VERSION ""

NS_ :

BS_:

BU_: BCM DMS NAB NDG NQS NVO SGW

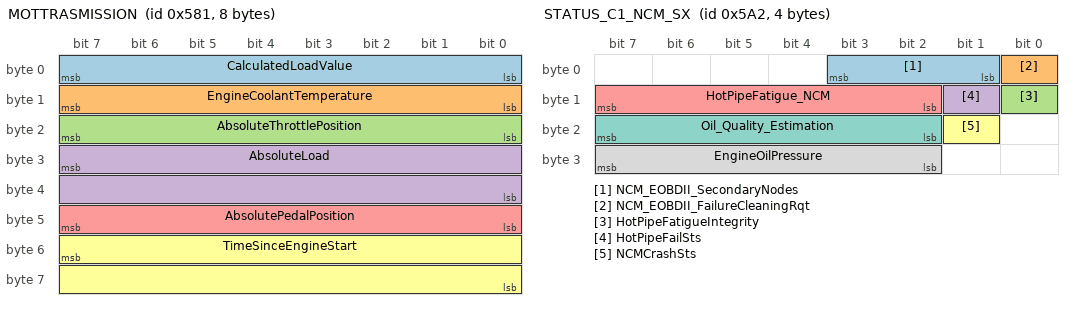
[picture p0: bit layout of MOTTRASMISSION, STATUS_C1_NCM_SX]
BO_ 1409 MOTTRASMISSION: 8 SGW
 SG_ CalculatedLoadValue : 7|8@0+ (0.392,0) [0|99.96] "%" Vector__XXX
 SG_ EngineCoolantTemperature : 15|8@0+ (1,-40) [-40|215] "°C" Vector__XXX
 SG_ AbsoluteThrottlePosition : 23|8@0+ (0.392,0) [0|99.96] "%"  NAB
 SG_ AbsoluteLoad : 31|16@0+ (0.392,0) [0|25689.72] "%" Vector__XXX
 SG_ AbsolutePedalPosition : 47|8@0+ (0.392,0) [0|99.96] "%" Vector__XXX
 SG_ TimeSinceEngineStart : 55|16@0+ (1,0) [0|65535] "sec." Vector__XXX

BO_ 1441 STATUS_C_NCM2: 8 SGW
 SG_ Checksum_STATUS_C_NCM2 : 7|8@0+ (1,0) [0|255] ""  BCM,DMS,NQS
 SG_ EngineOilTemperature : 8|8@0+ (1,-48) [-10|179] "°C"  BCM,NDG,NQS
 SG_ ReducePowerAssist : 9|1@0+ (1,0) [0|1] ""  BCM
 SG_ EM_Ready_Indication : 10|1@0+ (1,0) [0|1] ""  BCM,NQS
 SG_ FuelCapCheckWarning : 13|1@0+ (1,0) [0|1] ""  BCM,NQS
 SG_ VehicleNotInUse : 15|2@0+ (1,0) [0|3] ""  BCM,NDG,NQS
 SG_ EngineOilTemperatureValidData : 16|1@0+ (1,0) [0|1] ""  BCM,NDG,NQS
 SG_ BatteryVoltageLevel : 30|7@0+ (0.16,0) [0|18] "volt"  BCM
 SG_ CruiseControlSts : 31|1@0+ (1,0) [0|1] ""  BCM
 SG_ CruiseControlLampSts : 33|2@0+ (1,0) [0|3] ""  BCM,NAB,NDG,NQS,NVO
 SG_ RechargeSts : 34|1@0+ (1,0) [0|1] ""  BCM
 SG_ MessageCounter : 38|4@0+ (1,0) [0|15] ""  BCM,DMS,NQS
 SG_ BatteryVoltageLevelFailSts : 39|1@0+ (1,0) [0|1] ""  BCM
 SG_ StopStartVisualizationCode : 43|4@0+ (1,0) [0|15] ""  BCM,NDG,NQS
 SG_ EngineSts : 45|2@0+ (1,0) [0|3] ""  BCM,DMS,NDG,NQS
 SG_ StopStartSts : 47|2@0+ (1,0) [0|3] ""  BCM,NQS
 SG_ ColdStartTime : 48|1@0+ (1,0) [0|1] ""  BCM
 SG_ NCMMildHybSysWarningForDisplay : 52|4@0+ (1,0) [0|15] ""  BCM
 SG_ EDriveSts : 54|2@0+ (1,0) [0|3] ""  BCM,DMS,NDG,NQS
 SG_ EngineBonnetSts2 : 55|1@0+ (1,0) [0|1] ""  BCM
 SG_ TargetSpeed : 63|8@0+ (1,0) [0|255] "km/h"  BCM,NQS

BO_ 1442 STATUS_C1_NCM_SX: 4 SGW
 SG_ NCM_EOBDII_SecondaryNodes : 3|3@0+ (1,0) [0|7] ""  BCM
 SG_ NCM_EOBDII_FailureCleaningRqt : 0|1@0+ (1,0) [0|1] ""  BCM
 SG_ HotPipeFatigueIntegrity : 8|1@0+ (1,0) [0|1] ""  NQS
 SG_ HotPipeFailSts : 9|1@0+ (1,0) [0|1] ""  NDG,NQS
 SG_ HotPipeFatigue_NCM : 15|6@0+ (0.016,0) [0|1.008] ""  NQS
 SG_ NCMCrashSts : 17|1@0+ (1,0) [0|1] ""  BCM
 SG_ Oil_Quality_Estimation : 23|6@0+ (1.6,-1) [-1|99.8] "%"  NDG,NQS
 SG_ EngineOilPressure : 31|6@0+ (0.2,0) [0|10] "bar"  NDG,NQS

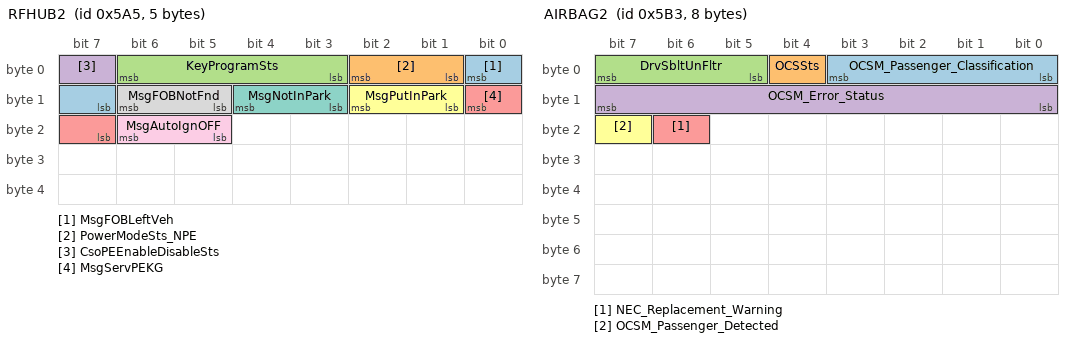
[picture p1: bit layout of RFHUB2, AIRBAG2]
BO_ 1445 RFHUB2: 5 BCM
 SG_ MsgFOBLeftVeh : 0|2@0+ (1,0) [0|3] ""  NQS
 SG_ PowerModeSts_NPE : 2|2@0+ (1,0) [0|3] "" Vector__XXX
 SG_ KeyProgramSts : 6|4@0+ (1,0) [0|15] ""  NDG,NQS
 SG_ CsoPEEnableDisableSts : 7|1@0+ (1,0) [0|1] ""  NQS
 SG_ MsgServPEKG : 8|2@0+ (1,0) [0|3] ""  NDG,NQS
 SG_ MsgPutInPark : 10|2@0+ (1,0) [0|3] ""  NQS
 SG_ MsgNotInPark : 12|2@0+ (1,0) [0|3] ""  NQS
 SG_ MsgFOBNotFnd : 14|2@0+ (1,0) [0|3] ""  NQS
 SG_ MsgAutoIgnOFF : 22|2@0+ (1,0) [0|3] "" Vector__XXX

BO_ 1459 AIRBAG2: 8 NAB
 SG_ OCSM_Passenger_Classification : 3|4@0+ (1,0) [0|15] "" Vector__XXX
 SG_ OCSSts : 4|1@0+ (1,0) [0|1] ""  NQS
 SG_ DrvSbltUnFltr : 7|3@0+ (1,0) [0|7] "" Vector__XXX
 SG_ OCSM_Error_Status : 15|8@0+ (1,0) [0|255] "" Vector__XXX
 SG_ NEC_Replacement_Warning : 22|1@0+ (1,0) [0|1] ""  BCM
 SG_ OCSM_Passenger_Detected : 23|1@0+ (1,0) [0|1] "" Vector__XXX

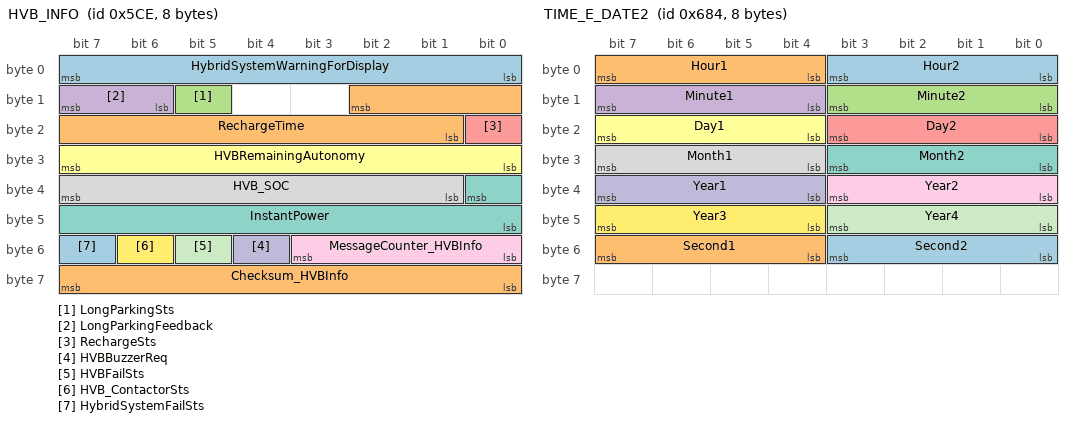
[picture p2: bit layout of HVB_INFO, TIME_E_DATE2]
BO_ 1486 HVB_INFO: 8 SGW
 SG_ HybridSystemWarningForDisplay : 7|8@0+ (1,0) [0|255] ""  BCM,NDG,NQS
 SG_ RechargeTime : 10|10@0+ (1,0) [0|540] "minute"  BCM,NDG,NQS
 SG_ LongParkingSts : 13|1@0+ (1,0) [0|1] ""  BCM,NQS
 SG_ LongParkingFeedback : 15|2@0+ (1,0) [0|3] ""  BCM
 SG_ RechargeSts : 16|1@0+ (1,0) [0|1] ""  BCM,NDG,NQS
 SG_ HVBRemainingAutonomy : 31|8@0+ (1,0) [0|255] "day"  BCM,NDG,NQS
 SG_ InstantPower : 32|9@0+ (1,-256) [-256|255] "kW"  BCM,NQS
 SG_ HVB_SOC : 39|7@0+ (1,0) [0|100] "%"  BCM,NDG,NQS
 SG_ MessageCounter_HVBInfo : 51|4@0+ (1,0) [0|15] ""  BCM,NQS
 SG_ HVBBuzzerReq : 52|1@0+ (1,0) [0|1] ""  BCM,NQS
 SG_ HVBFailSts : 53|1@0+ (1,0) [0|1] ""  BCM,NDG,NQS
 SG_ HVB_ContactorSts : 54|1@0+ (1,0) [0|1] ""  BCM
 SG_ HybridSystemFailSts : 55|1@0+ (1,0) [0|1] ""  BCM,NDG,NQS
 SG_ Checksum_HVBInfo : 63|8@0+ (1,0) [0|255] ""  BCM,NQS

BO_ 1504 STATUS_B_CAN2: 8 BCM
 SG_ EngineOilPressureValidData : 0|1@0+ (1,0) [0|1] ""  SGW
 SG_ EngineOilTemperatureValidData : 1|1@0+ (1,0) [0|1] ""  SGW
 SG_ FuelFlapSts : 2|1@0+ (1,0) [0|1] ""  SGW
 SG_ LowBeamSts : 3|1@0+ (1,0) [0|1] "" Vector__XXX
 SG_ FuelButtonSts : 4|1@0+ (1,0) [0|1] ""  SGW
 SG_ CapoteSts : 7|3@0+ (1,0) [0|7] ""  DMS,SGW
 SG_ EngineOilTemperature : 15|8@0+ (1,-48) [-10|179] "°C"  SGW
 SG_ FoldMirrorSts : 16|1@0+ (1,0) [0|1] ""  SGW
 SG_ WalkAwayEnabled : 17|1@0+ (1,0) [0|1] ""  SGW
 SG_ EngineOilPressure : 23|6@0+ (0.2,0) [0|10] "bar"  SGW
 SG_ TotalOdometer : 27|20@0+ (1,0) [0|999999] "km"  DMS,NAB,SGW
 SG_ ElectricSteeringLamp_FailSts : 29|2@0+ (1,0) [0|3] ""  SGW
 SG_ NAMEnable : 30|1@0+ (1,0) [0|1] ""  SGW
 SG_ InternalLightLevel : 51|4@0+ (1,0) [0|15] ""  SGW
 SG_ NightDaySts : 52|1@0+ (1,0) [0|1] ""  SGW
 SG_ LongParkingSetting : 54|2@0+ (1,0) [0|3] ""  SGW
 SG_ AVHDriverDoorSts : 55|1@0+ (1,0) [0|1] ""  SGW
 SG_ Alcohol_Interlock_Inhibit : 56|1@0+ (1,0) [0|1] ""  SGW
 SG_ TrunkFailSts : 57|1@0+ (1,0) [0|1] ""  NQS,SGW
 SG_ EngineBonnetSts_LH : 58|1@0+ (1,0) [0|1] ""  SGW
 SG_ RechargeFlapSts : 62|1@0+ (1,0) [0|1] ""  SGW
 SG_ InternalLightSts : 63|1@0+ (1,0) [0|1] ""  SGW

BO_ 1628 NQS_DBG_SLWF_07: 8 NQS
 SG_ OUT_DBG_SLWF25 : 7|16@0- (1,0) [-32768|32767] "" Vector__XXX
 SG_ OUT_DBG_SLWF26 : 23|16@0- (1,0) [-32768|32767] "" Vector__XXX
 SG_ OUT_DBG_SLWF27 : 39|16@0- (1,0) [-32768|32767] "" Vector__XXX
 SG_ OUT_DBG_SLWF28 : 55|16@0- (1,0) [-32768|32767] "" Vector__XXX

BO_ 1668 TIME_E_DATE2: 8 NQS
 SG_ Hour2 : 3|4@0+ (1,0) [0|9] ""  NAB
 SG_ Hour1 : 7|4@0+ (1,0) [0|9] ""  NAB
 SG_ Minute2 : 11|4@0+ (1,0) [0|9] ""  NAB
 SG_ Minute1 : 15|4@0+ (1,0) [0|9] ""  NAB
 SG_ Day2 : 19|4@0+ (1,0) [0|9] ""  NAB
 SG_ Day1 : 23|4@0+ (1,0) [0|9] ""  NAB
 SG_ Month2 : 27|4@0+ (1,0) [0|9] ""  NAB
 SG_ Month1 : 31|4@0+ (1,0) [0|9] ""  NAB
 SG_ Year2 : 35|4@0+ (1,0) [0|9] ""  NAB
 SG_ Year1 : 39|4@0+ (1,0) [0|9] ""  NAB
 SG_ Year4 : 43|4@0+ (1,0) [0|9] ""  NAB
 SG_ Year3 : 47|4@0+ (1,0) [0|9] ""  NAB
 SG_ Second2 : 51|4@0+ (1,0) [0|9] ""  NAB
 SG_ Second1 : 55|4@0+ (1,0) [0|9] ""  NAB

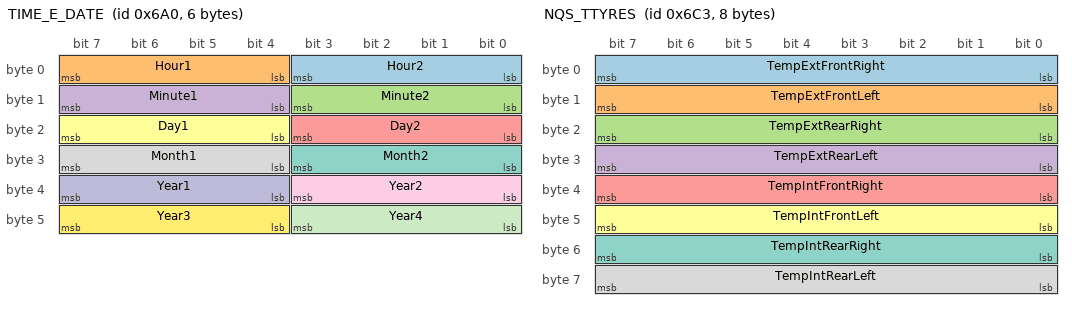
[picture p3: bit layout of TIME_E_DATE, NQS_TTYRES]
BO_ 1696 TIME_E_DATE: 6 NQS
 SG_ Hour2 : 3|4@0+ (1,0) [0|9] ""  BCM,DMS,SGW
 SG_ Hour1 : 7|4@0+ (1,0) [0|9] ""  BCM,DMS,SGW
 SG_ Minute2 : 11|4@0+ (1,0) [0|9] ""  BCM,DMS,SGW
 SG_ Minute1 : 15|4@0+ (1,0) [0|9] ""  BCM,DMS,SGW
 SG_ Day2 : 19|4@0+ (1,0) [0|9] ""  BCM,DMS,SGW
 SG_ Day1 : 23|4@0+ (1,0) [0|9] ""  BCM,DMS,SGW
 SG_ Month2 : 27|4@0+ (1,0) [0|9] ""  BCM,DMS,SGW
 SG_ Month1 : 31|4@0+ (1,0) [0|9] ""  BCM,DMS,SGW
 SG_ Year2 : 35|4@0+ (1,0) [0|9] ""  BCM,DMS,SGW
 SG_ Year1 : 39|4@0+ (1,0) [0|9] ""  BCM,DMS,SGW
 SG_ Year4 : 43|4@0+ (1,0) [0|9] ""  BCM,DMS,SGW
 SG_ Year3 : 47|4@0+ (1,0) [0|9] ""  BCM,DMS,SGW

BO_ 1727 NQS_DBG_SLWF_04: 8 NQS
 SG_ OUT_DBG_SLWF13 : 7|16@0- (1,0) [-32768|32767] "" Vector__XXX
 SG_ OUT_DBG_SLWF14 : 23|16@0- (1,0) [-32768|32767] "" Vector__XXX
 SG_ OUT_DBG_SLWF15 : 39|16@0- (1,0) [-32768|32767] "" Vector__XXX
 SG_ OUT_DBG_SLWF16 : 55|16@0- (1,0) [-32768|32767] "" Vector__XXX

BO_ 1728 EOL_CONFIGURATION_V4: 8 BCM
 SG_ RearWheelCircumference : 7|8@0+ (5,1440) [1440|2715] "mm"  SGW
 SG_ DISABLE_SSV : 8|1@0+ (1,0) [0|1] ""  SGW
 SG_ ENABLE_SAA : 9|1@0+ (1,0) [0|1] ""  SGW
 SG_ BatteryType : 13|4@0+ (1,0) [0|15] ""  SGW
 SG_ NotInUseMonitoringTimer : 15|2@0+ (10,10) [10|40] "minutes"  SGW
 SG_ NCMSoftwareVariant : 18|3@0+ (1,0) [0|7] ""  SGW
 SG_ Vehicle_Type : 22|4@0+ (1,0) [0|15] ""  SGW
 SG_ EOL_CruiseControl : 23|1@0+ (1,0) [0|1] ""  SGW
 SG_ Rear_Doors : 24|1@0+ (1,0) [0|1] ""  SGW
 SG_ STOPANDSTART : 26|1@0+ (1,0) [0|1] ""  SGW
 SG_ TrafficType : 27|1@0+ (1,0) [0|1] ""  SGW
 SG_ Vehicle_Variant : 31|4@0+ (1,0) [0|15] ""  SGW
 SG_ Adaptive_Cruise_Control : 32|1@0+ (1,0) [0|1] ""  SGW
 SG_ Forward_Collision_Mitigation : 33|1@0+ (1,0) [0|1] ""  SGW
 SG_ ACCManettinoHighThr : 42|3@0+ (1,0) [0|7] "count"  SGW
 SG_ Node_19_NSV : 43|1@0+ (1,0) [0|1] ""  SGW
 SG_ EOL_PlockLimiter : 45|1@0+ (1,0) [0|1] ""  SGW
 SG_ Engine_Fan_Management : 46|1@0+ (1,0) [0|1] ""  SGW
 SG_ PowerUnit : 47|1@0+ (1,0) [0|1] ""  SGW

BO_ 1730 NQS_DBG_SLWF_05: 8 NQS
 SG_ OUT_DBG_SLWF17 : 7|16@0- (1,0) [-32768|32767] "" Vector__XXX
 SG_ OUT_DBG_SLWF18 : 23|16@0- (1,0) [-32768|32767] "" Vector__XXX
 SG_ OUT_DBG_SLWF19 : 39|16@0- (1,0) [-32768|32767] "" Vector__XXX
 SG_ OUT_DBG_SLWF20 : 55|16@0- (1,0) [-32768|32767] "" Vector__XXX

BO_ 1731 NQS_TTYRES: 8 NQS
 SG_ TempExtFrontRight : 7|8@0+ (2,-40) [-40|470] "°C"  SGW
 SG_ TempExtFrontLeft : 15|8@0+ (2,-40) [-40|470] "°C"  SGW
 SG_ TempExtRearRight : 23|8@0+ (2,-40) [-40|470] "°C"  SGW
 SG_ TempExtRearLeft : 31|8@0+ (2,-40) [-40|470] "°C"  SGW
 SG_ TempIntFrontRight : 39|8@0+ (2,-40) [-40|470] "°C"  SGW
 SG_ TempIntFrontLeft : 47|8@0+ (2,-40) [-40|470] "°C"  SGW
 SG_ TempIntRearRight : 55|8@0+ (2,-40) [-40|470] "°C"  SGW
 SG_ TempIntRearLeft : 63|8@0+ (2,-40) [-40|470] "°C"  SGW

BO_ 1732 NQS_DBG_SLWF_06: 8 NQS
 SG_ OUT_DBG_SLWF21 : 7|16@0- (1,0) [-32768|32767] "" Vector__XXX
 SG_ OUT_DBG_SLWF22 : 23|16@0- (1,0) [-32768|32767] "" Vector__XXX
 SG_ OUT_DBG_SLWF23 : 39|16@0- (1,0) [-32768|32767] "" Vector__XXX
 SG_ OUT_DBG_SLWF24 : 55|16@0- (1,0) [-32768|32767] "" Vector__XXX

BO_ 1734 NQS_DBG_SLWF_08: 8 NQS
 SG_ OUT_DBG_SLWF29 : 7|16@0- (1,0) [-32768|32767] "" Vector__XXX
 SG_ OUT_DBG_SLWF30 : 23|16@0- (1,0) [-32768|32767] "" Vector__XXX
 SG_ OUT_DBG_SLWF31 : 39|16@0- (1,0) [-32768|32767] "" Vector__XXX
 SG_ OUT_DBG_SLWF32 : 55|16@0- (1,0) [-32768|32767] "" Vector__XXX

BO_ 1742 NQS_DBG_SLWF_09: 8 NQS
 SG_ OUT_DBG_SLWF33 : 7|16@0- (1,0) [-32768|32767] "" Vector__XXX
 SG_ OUT_DBG_SLWF34 : 23|16@0- (1,0) [-32768|32767] "" Vector__XXX
 SG_ OUT_DBG_SLWF35 : 39|16@0- (1,0) [-32768|32767] "" Vector__XXX
 SG_ OUT_DBG_SLWF36 : 55|16@0- (1,0) [-32768|32767] "" Vector__XXX

BO_ 1743 NQS_DBG_SLWF_10: 8 NQS
 SG_ OUT_DBG_SLWF37 : 7|16@0- (1,0) [-32768|32767] "" Vector__XXX
 SG_ OUT_DBG_SLWF38 : 23|16@0- (1,0) [-32768|32767] "" Vector__XXX
 SG_ OUT_DBG_SLWF39 : 39|16@0- (1,0) [-32768|32767] "" Vector__XXX
 SG_ OUT_DBG_SLWF40 : 55|16@0- (1,0) [-32768|32767] "" Vector__XXX

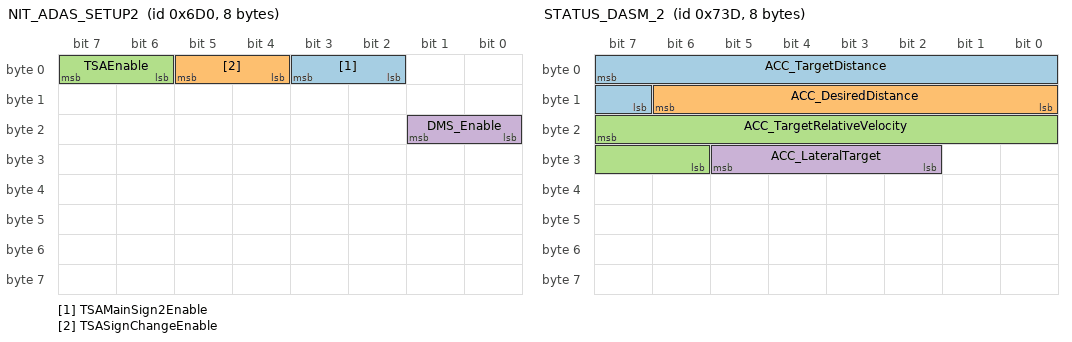
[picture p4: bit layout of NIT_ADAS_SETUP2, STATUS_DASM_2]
BO_ 1744 NIT_ADAS_SETUP2: 8 SGW
 SG_ TSAMainSign2Enable : 3|2@0+ (1,0) [0|3] "" Vector__XXX
 SG_ TSASignChangeEnable : 5|2@0+ (1,0) [0|3] "" Vector__XXX
 SG_ TSAEnable : 7|2@0+ (1,0) [0|3] "" Vector__XXX
 SG_ DMS_Enable : 17|2@0+ (1,0) [0|3] ""  DMS

BO_ 1745 NQS_DBG_SLWF_03: 8 NQS
 SG_ OUT_DBG_SLWF09 : 7|16@0- (1,0) [-32768|32767] "" Vector__XXX
 SG_ OUT_DBG_SLWF10 : 23|16@0- (1,0) [-32768|32767] "" Vector__XXX
 SG_ OUT_DBG_SLWF11 : 39|16@0- (1,0) [-32768|32767] "" Vector__XXX
 SG_ OUT_DBG_SLWF12 : 55|16@0- (1,0) [-32768|32767] "" Vector__XXX

BO_ 1746 NQS_DBG_SLWF_01: 8 NQS
 SG_ OUT_DBG_SLWF01 : 7|16@0- (1,0) [-32768|32767] "" Vector__XXX
 SG_ OUT_DBG_SLWF02 : 23|16@0- (1,0) [-32768|32767] "" Vector__XXX
 SG_ OUT_DBG_SLWF03 : 39|16@0- (1,0) [-32768|32767] "" Vector__XXX
 SG_ OUT_DBG_SLWF04 : 55|16@0- (1,0) [-32768|32767] "" Vector__XXX

BO_ 1747 NQS_DBG_SLWF_02: 8 NQS
 SG_ OUT_DBG_SLWF05 : 7|16@0- (1,0) [-32768|32767] "" Vector__XXX
 SG_ OUT_DBG_SLWF06 : 23|16@0- (1,0) [-32768|32767] "" Vector__XXX
 SG_ OUT_DBG_SLWF07 : 39|16@0- (1,0) [-32768|32767] "" Vector__XXX
 SG_ OUT_DBG_SLWF08 : 55|16@0- (1,0) [-32768|32767] "" Vector__XXX

BO_ 1852 STATUS_DASM: 8 SGW
 SG_ ACC_Dist_fbk : 2|3@0+ (1,0) [0|7] "" Vector__XXX
 SG_ ACCFailReversibleSts : 4|2@0+ (1,0) [0|3] "" Vector__XXX
 SG_ DASMTemporaryFailSts : 8|1@0+ (1,0) [0|1] ""  NAB
 SG_ DASMFailSts : 9|1@0+ (1,0) [0|1] ""  NAB,NQS
 SG_ RadarBlinded : 10|1@0+ (1,0) [0|1] "" Vector__XXX
 SG_ FCWSystemSts : 12|2@0+ (1,0) [0|3] ""  NAB,NQS
 SG_ ACC_DrivingMode_fbk : 13|1@0+ (1,0) [0|1] "" Vector__XXX
 SG_ FCWSts : 15|2@0+ (1,0) [0|3] "" Vector__XXX
 SG_ HMICode_FCW : 21|6@0+ (1,0) [0|63] ""  NQS
 SG_ CameraBlinded : 22|1@0+ (1,0) [0|1] ""  NQS
 SG_ CameraFailure : 23|1@0+ (1,0) [0|1] ""  NQS
 SG_ ACC_SetSpeedKPH : 31|8@0+ (1,0) [0|255] "Kph"  NQS
 SG_ ACC_SetSpeedMPH : 39|8@0+ (1,0) [0|255] "mph"  NQS
 SG_ HMICode_ACC : 45|8@0+ (1,0) [0|255] ""  NQS
 SG_ ACCFailSts : 47|1@0+ (1,0) [0|1] ""  NAB,NQS
 SG_ HMIDisplay_ACC : 53|6@0+ (1,0) [0|63] ""  NQS
 SG_ FCWSensibilitySts : 57|2@0+ (1,0) [0|3] "" Vector__XXX
 SG_ ACC_RadarBlinded : 58|1@0+ (1,0) [0|1] ""  NQS
 SG_ ACCSystemSts : 62|3@0+ (1,0) [0|7] ""  BCM,NAB,NQS,NVO

BO_ 1853 STATUS_DASM_2: 8 SGW
 SG_ ACC_TargetDistance : 7|9@0+ (1,0) [0|511] ""  NQS
 SG_ ACC_DesiredDistance : 14|7@0+ (1,0) [0|127] ""  NQS
 SG_ ACC_TargetRelativeVelocity : 23|10@0+ (0.25,-128) [-128|127.75] "m/s" Vector__XXX
 SG_ ACC_LateralTarget : 29|4@0+ (1,0) [0|15] "" Vector__XXX

BO_ 1904 NQS_DBG_CCM_01: 8 NQS
 SG_ OUT_DBG_debug01_UW : 7|16@0- (1,0) [-32768|32767] "" Vector__XXX
 SG_ OUT_DBG_debug02_UW : 23|16@0- (1,0) [-32768|32767] "" Vector__XXX
 SG_ OUT_DBG_debug03_UW : 39|16@0- (1,0) [-32768|32767] "" Vector__XXX
 SG_ OUT_DBG_debug04_UW : 55|16@0- (1,0) [-32768|32767] "" Vector__XXX

BO_ 1905 NQS_DBG_CCM_02: 8 NQS
 SG_ OUT_DBG_debug05_UW : 7|16@0- (1,0) [-32768|32767] "" Vector__XXX
 SG_ OUT_DBG_debug06_UW : 23|16@0- (1,0) [-32768|32767] "" Vector__XXX
 SG_ OUT_DBG_debug07_UW : 39|16@0- (1,0) [-32768|32767] "" Vector__XXX
 SG_ OUT_DBG_debug08_UW : 55|16@0- (1,0) [-32768|32767] "" Vector__XXX

BO_ 1906 NQS_DBG_CCM_03: 8 NQS
 SG_ OUT_DBG_debug09_UW : 7|16@0- (1,0) [-32768|32767] "" Vector__XXX
 SG_ OUT_DBG_debug10_UW : 23|16@0- (1,0) [-32768|32767] "" Vector__XXX
 SG_ OUT_DBG_debug11_UW : 39|16@0- (1,0) [-32768|32767] "" Vector__XXX
 SG_ OUT_DBG_debug12_UW : 55|16@0- (1,0) [-32768|32767] "" Vector__XXX

BO_ 1907 NQS_DBG_CCM_04: 8 NQS
 SG_ OUT_DBG_debug13_UW : 7|16@0- (1,0) [-32768|32767] "" Vector__XXX
 SG_ OUT_DBG_debug14_UW : 23|16@0- (1,0) [-32768|32767] "" Vector__XXX
 SG_ OUT_DBG_debug15_UW : 39|16@0- (1,0) [-32768|32767] "" Vector__XXX
 SG_ OUT_DBG_debug16_UW : 55|16@0- (1,0) [-32768|32767] "" Vector__XXX

BO_ 1908 NQS_DBG_CCM_05: 8 NQS
 SG_ OUT_DBG_debug17_UW : 7|16@0- (1,0) [-32768|32767] "" Vector__XXX
 SG_ OUT_DBG_debug18_UW : 23|16@0- (1,0) [-32768|32767] "" Vector__XXX
 SG_ OUT_DBG_debug19_UW : 39|16@0- (1,0) [-32768|32767] "" Vector__XXX
 SG_ OUT_DBG_debug20_UW : 55|16@0- (1,0) [-32768|32767] "" Vector__XXX

BO_ 1909 NQS_DBG_CCM_06: 8 NQS
 SG_ OUT_DBG_debug21_UW : 7|16@0- (1,0) [-32768|32767] "" Vector__XXX
 SG_ OUT_DBG_debug22_UW : 23|16@0- (1,0) [-32768|32767] "" Vector__XXX
 SG_ OUT_DBG_debug23_UW : 39|16@0- (1,0) [-32768|32767] "" Vector__XXX
 SG_ OUT_DBG_debug24_UW : 55|16@0- (1,0) [-32768|32767] "" Vector__XXX

BO_ 1910 NQS_DBG_CCM_07: 8 NQS
 SG_ OUT_DBG_debug25_UW : 7|16@0- (1,0) [-32768|32767] "" Vector__XXX
 SG_ OUT_DBG_debug26_UW : 23|16@0- (1,0) [-32768|32767] "" Vector__XXX
 SG_ OUT_DBG_debug27_UW : 39|16@0- (1,0) [-32768|32767] "" Vector__XXX
 SG_ OUT_DBG_debug28_UW : 55|16@0- (1,0) [-32768|32767] "" Vector__XXX

BO_ 1911 NQS_DBG_CCM_08: 8 NQS
 SG_ OUT_DBG_debug29_UW : 7|16@0- (1,0) [-32768|32767] "" Vector__XXX
 SG_ OUT_DBG_debug30_UW : 23|16@0- (1,0) [-32768|32767] "" Vector__XXX
 SG_ OUT_DBG_debug31_UW : 39|16@0- (1,0) [-32768|32767] "" Vector__XXX
 SG_ OUT_DBG_debug32_UW : 55|16@0- (1,0) [-32768|32767] "" Vector__XXX

BO_ 1912 NQS_DBG_CCM_09: 8 NQS
 SG_ OUT_DBG_debug33_UW : 7|16@0- (1,0) [-32768|32767] "" Vector__XXX
 SG_ OUT_DBG_debug34_UW : 23|16@0- (1,0) [-32768|32767] "" Vector__XXX
 SG_ OUT_DBG_debug35_UW : 39|16@0- (1,0) [-32768|32767] "" Vector__XXX
 SG_ OUT_DBG_debug36_UW : 55|16@0- (1,0) [-32768|32767] "" Vector__XXX

BO_ 1913 NQS_DBG_CCM_10: 8 NQS
 SG_ OUT_DBG_debug37_UW : 7|16@0- (1,0) [-32768|32767] "" Vector__XXX
 SG_ OUT_DBG_debug38_UW : 23|16@0- (1,0) [-32768|32767] "" Vector__XXX
 SG_ OUT_DBG_debug39_UW : 39|16@0- (1,0) [-32768|32767] "" Vector__XXX
 SG_ OUT_DBG_debug40_UW : 55|16@0- (1,0) [-32768|32767] "" Vector__XXX

BO_ 1914 NQS_DBG_CCM_11: 8 NQS
 SG_ OUT_DBG_debug41_UW : 7|16@0- (1,0) [-32768|32767] "" Vector__XXX
 SG_ OUT_DBG_debug42_UW : 23|16@0- (1,0) [-32768|32767] "" Vector__XXX
 SG_ OUT_DBG_debug43_UW : 39|16@0- (1,0) [-32768|32767] "" Vector__XXX
 SG_ OUT_DBG_debug44_UW : 55|16@0- (1,0) [-32768|32767] "" Vector__XXX

BO_ 1915 NQS_DBG_CCM_12: 8 NQS
 SG_ OUT_DBG_debug45_UW : 7|16@0- (1,0) [-32768|32767] "" Vector__XXX
 SG_ OUT_DBG_debug46_UW : 23|16@0- (1,0) [-32768|32767] "" Vector__XXX
 SG_ OUT_DBG_debug47_UW : 39|16@0- (1,0) [-32768|32767] "" Vector__XXX
 SG_ OUT_DBG_debug48_UW : 55|16@0- (1,0) [-32768|32767] "" Vector__XXX

BO_ 1916 NQS_DBG_CCM_13: 8 NQS
 SG_ OUT_DBG_debug49_UW : 7|16@0- (1,0) [0|65535] "" Vector__XXX
 SG_ OUT_DBG_debug50_UW : 23|16@0- (1,0) [0|65535] "" Vector__XXX
 SG_ OUT_DBG_debug51_UW : 39|16@0- (1,0) [0|65535] "" Vector__XXX
 SG_ OUT_DBG_debug52_UW : 55|16@0- (1,0) [0|65535] "" Vector__XXX

BO_ 1917 NQS_DBG_CCM_14: 8 NQS
 SG_ OUT_DBG_debug53_UW : 7|16@0- (1,0) [0|65535] "" Vector__XXX
 SG_ OUT_DBG_debug54_UW : 23|16@0- (1,0) [0|65535] "" Vector__XXX
 SG_ OUT_DBG_debug55_UW : 39|16@0- (1,0) [0|65535] "" Vector__XXX
 SG_ OUT_DBG_debug56_UW : 55|16@0- (1,0) [0|65535] "" Vector__XXX

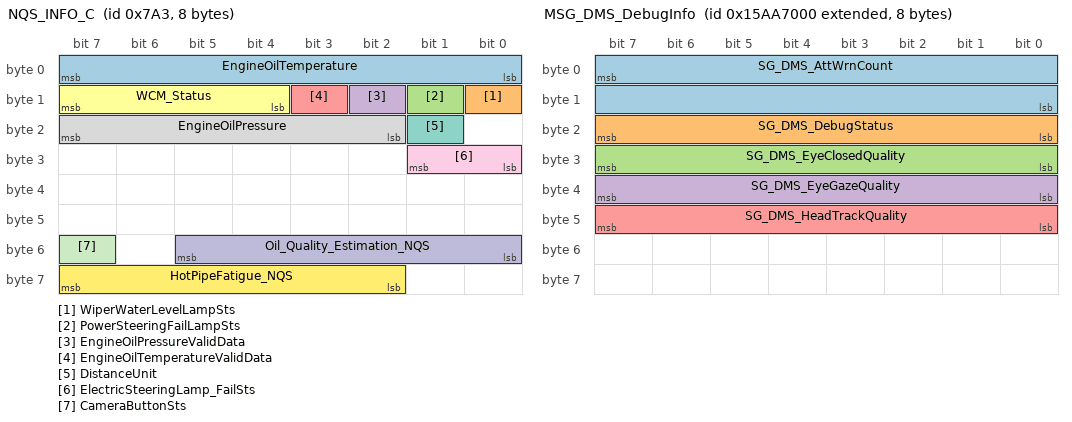
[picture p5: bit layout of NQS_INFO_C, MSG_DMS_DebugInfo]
BO_ 1955 NQS_INFO_C: 8 NQS
 SG_ EngineOilTemperature : 7|8@0+ (1,-48) [-10|179] "°C"  BCM,SGW
 SG_ WiperWaterLevelLampSts : 8|1@0+ (1,0) [0|1] ""  BCM,SGW
 SG_ PowerSteeringFailLampSts : 9|1@0+ (1,0) [0|1] ""  BCM,SGW
 SG_ EngineOilPressureValidData : 10|1@0+ (1,0) [0|1] ""  BCM,SGW
 SG_ EngineOilTemperatureValidData : 11|1@0+ (1,0) [0|1] ""  BCM,SGW
 SG_ WCM_Status : 15|4@0+ (1,0) [0|15] ""  BCM,SGW
 SG_ DistanceUnit : 17|1@0+ (1,0) [0|1] ""  BCM,SGW
 SG_ EngineOilPressure : 23|6@0+ (0.2,0) [0|10] "bar"  BCM,SGW
 SG_ ElectricSteeringLamp_FailSts : 25|2@0+ (1,0) [0|3] ""  BCM,NDG,SGW
 SG_ Oil_Quality_Estimation_NQS : 53|6@0+ (1.6,-1) [-1|99.8] "%"  BCM,SGW
 SG_ CameraButtonSts : 55|1@0+ (1,0) [0|1] ""  BCM,SGW
 SG_ HotPipeFatigue_NQS : 63|6@0+ (0.016,0) [0|1.008] ""  BCM,SGW

BO_ 2443860262 SGW_INFO: 8 SGW
 SG_ SGW_Status : 57|2@0+ (1,0) [0|3] ""  NQS

BO_ 2443869696 DONGLE_INFO: 8 SGW
 SG_ Vin_MSG_MuxID_ M : 2|3@0+ (1,0) [0|7] ""  NDG
 SG_ SCENARIO_ : 4|2@0+ (1,0) [0|3] ""  NDG
 SG_ Station_ : 7|3@0+ (1,0) [0|7] ""  NDG
 SG_ Market_Part2 m6 : 15|40@0+ (1,0) [0|1099511627775] ""  NDG
 SG_ Timestamp_Part2 m3 : 15|48@0+ (1,0) [0|281474976710655] ""  NDG
 SG_ UserID_Part1 m4 : 15|56@0+ (1,0) [0|7.20575940379279E+016] ""  NDG
 SG_ UserID_Part2 m5 : 15|16@0+ (1,0) [0|65535] ""  NDG
 SG_ Vin_Part1 m0 : 15|56@0+ (1,0) [0|7.20575940379279E+016] ""  NDG
 SG_ Vin_Part2 m1 : 15|56@0+ (1,0) [0|7.20575940379279E+016] ""  NDG
 SG_ Vin_Part3 m2 : 15|24@0+ (1,0) [0|16777215] ""  NDG
 SG_ Market_Part1 m5 : 31|40@0+ (1,0) [0|1099511627775] ""  NDG
 SG_ Timestamp_Part1 m2 : 39|32@0+ (1,0) [0|4294967295] ""  NDG
 SG_ TestResult m3 : 63|8@0+ (1,0) [0|255] ""  NDG

BO_ 2510974976 MSG_DMS_DebugInfo: 8 DMS
 SG_ SG_DMS_AttWrnCount : 7|16@0+ (1,0) [0|65535] "" Vector__XXX
 SG_ SG_DMS_DebugStatus : 23|8@0+ (1,0) [0|15] "" Vector__XXX
 SG_ SG_DMS_EyeClosedQuality : 31|8@0+ (1,0) [0|100] "%" Vector__XXX
 SG_ SG_DMS_EyeGazeQuality : 39|8@0+ (1,0) [0|100] "%" Vector__XXX
 SG_ SG_DMS_HeadTrackQuality : 47|8@0+ (1,0) [0|100] "%" Vector__XXX

BO_ 2510974977 MSG_DMS_EyePositionL: 8 DMS
 SG_ SG_DMS_EyePositionLX : 7|16@0- (1,0) [-32768|32767] "mm" Vector__XXX
 SG_ SG_DMS_EyePositionLY : 23|16@0- (1,0) [-32768|32767] "mm" Vector__XXX
 SG_ SG_DMS_EyePositionLZ : 39|16@0- (1,0) [-32768|32767] "mm" Vector__XXX

BO_ 2510974978 MSG_DMS_EyePositionR: 8 DMS
 SG_ SG_DMS_EyePositionRX : 7|16@0- (1,0) [-32768|32767] "mm" Vector__XXX
 SG_ SG_DMS_EyePositionRY : 23|16@0- (1,0) [-32768|32767] "mm" Vector__XXX
 SG_ SG_DMS_EyePositionRZ : 39|16@0- (1,0) [-32768|32767] "mm" Vector__XXX

BO_ 2510974979 MSG_DMS_GazeDirection: 8 DMS
 SG_ SG_DMS_EyeGazeDirectionX : 7|16@0- (1,0) [-32768|32767] "mrad" Vector__XXX
 SG_ SG_DMS_EyeGazeDirectionY : 23|16@0- (1,0) [-32768|32767] "mrad" Vector__XXX
 SG_ SG_DMS_EyeGazeDirectionZ : 39|16@0- (1,0) [-32768|32767] "mrad" Vector__XXX

BO_ 2564440305 UDS_DIAG_REQ_NBC: 8 SGW
 SG_ TPDU_DREQ_NBC : 7|64@0+ (1,0) [0|1.84467440737096E+019] ""  BCM

BO_ 2564443633 UDS_DIAG_REQ_DMS: 8 SGW
 SG_ TPDU_DREQ_DMS : 7|64@0+ (1,0) [0|1.84467440737096E+019] ""  DMS

BO_ 2564452593 UDS_DIAG_REQ_WLMR: 8 SGW
 SG_ TPDU_DREQ_WLMR : 7|64@0+ (1,0) [0|1.84467440737096E+019] ""  BCM

BO_ 2564452849 UDS_DIAG_REQ_WLML: 8 SGW
 SG_ TPDU_DREQ_WLML : 7|64@0+ (1,0) [0|1.84467440737096E+019] ""  BCM

BO_ 2564460785 UDS_DIAG_REQ_NPE: 8 SGW
 SG_ TPDU_DREQ_NPE : 7|64@0+ (1,0) [0|1.84467440737096E+019] ""  BCM

BO_ 2564473073 UDS_DIAG_REQ_NAB: 8 SGW
 SG_ TPDU_DREQ_NAB : 7|64@0+ (1,0) [0|1.84467440737096E+019] ""  NAB

BO_ 2564478449 UDS_DIAG_REQ_LCC: 8 SGW
 SG_ TPDU_DREQ_LCC : 7|64@0+ (1,0) [0|1.84467440737096E+019] ""  BCM

BO_ 2564485440 UDS_DIAG_RES_NBC: 8 BCM
 SG_ TPDU_DRES_NBC : 7|64@0+ (1,0) [0|1.84467440737096E+019] ""  SGW

BO_ 2564485453 UDS_DIAG_RES_DMS: 8 DMS
 SG_ TPDU_DRES_DMS : 7|64@0+ (1,0) [0|1.84467440737096E+019] ""  SGW

BO_ 2564485488 UDS_DIAG_RES_WLMR: 8 BCM
 SG_ TPDU_DRES_WLMR : 7|64@0+ (1,0) [0|1.84467440737096E+019] ""  SGW

BO_ 2564485489 UDS_DIAG_RES_WLML: 8 BCM
 SG_ TPDU_DRES_WLML : 7|64@0+ (1,0) [0|1.84467440737096E+019] ""  SGW

BO_ 2564485520 UDS_DIAG_RES_NPE: 8 BCM
 SG_ TPDU_DRES_NPE : 7|64@0+ (1,0) [0|1.84467440737096E+019] ""  SGW

BO_ 2564485568 UDS_DIAG_RES_NAB: 8 NAB
 SG_ TPDU_DRES_NAB : 7|64@0+ (1,0) [0|1.84467440737096E+019] ""  SGW

BO_ 2564485589 UDS_DIAG_RES_LCC: 8 BCM
 SG_ TPDU_DRES_LCC : 7|64@0+ (1,0) [0|1.84467440737096E+019] ""  SGW

BO_ 2564554481 UDS_DIAG_REQ_FUNC_BODY_CAN: 8 SGW
 SG_ TPDU_UDSFUNC : 7|64@0+ (1,0) [0|1.84467440737096E+019] ""  BCM,DMS,NAB,NQS,NVO

BO_ 2564554737 EDR_DIAG_DATA_REQ: 8 SGW
 SG_ TPDU_EDRDATAREQ : 7|64@0+ (1,0) [0|1.84467440737096E+019] ""  NAB

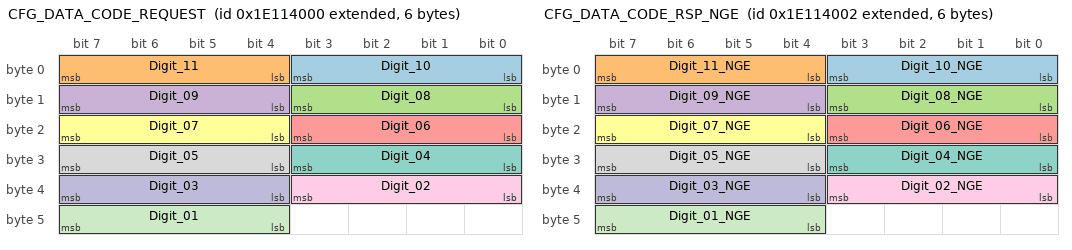
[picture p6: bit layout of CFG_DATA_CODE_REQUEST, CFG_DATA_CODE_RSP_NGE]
BO_ 2651930624 CFG_DATA_CODE_REQUEST: 6 BCM
 SG_ Digit_10 : 3|4@0+ (1,0) [0|15] ""  DMS,NAB,SGW
 SG_ Digit_11 : 7|4@0+ (1,0) [0|15] ""  DMS,NAB,SGW
 SG_ Digit_08 : 11|4@0+ (1,0) [0|15] ""  DMS,NAB,SGW
 SG_ Digit_09 : 15|4@0+ (1,0) [0|15] ""  DMS,NAB,SGW
 SG_ Digit_06 : 19|4@0+ (1,0) [0|15] ""  DMS,NAB,SGW
 SG_ Digit_07 : 23|4@0+ (1,0) [0|15] ""  DMS,NAB,SGW
 SG_ Digit_04 : 27|4@0+ (1,0) [0|15] ""  DMS,NAB,SGW
 SG_ Digit_05 : 31|4@0+ (1,0) [0|15] ""  DMS,NAB,SGW
 SG_ Digit_02 : 35|4@0+ (1,0) [0|15] ""  DMS,NAB,SGW
 SG_ Digit_03 : 39|4@0+ (1,0) [0|15] ""  DMS,NAB,SGW
 SG_ Digit_01 : 47|4@0+ (1,0) [0|15] ""  DMS,NAB,SGW

BO_ 2651930626 CFG_DATA_CODE_RSP_NGE: 6 SGW
 SG_ Digit_10_NGE : 3|4@0+ (1,0) [0|15] ""  BCM
 SG_ Digit_11_NGE : 7|4@0+ (1,0) [0|15] ""  BCM
 SG_ Digit_08_NGE : 11|4@0+ (1,0) [0|15] ""  BCM
 SG_ Digit_09_NGE : 15|4@0+ (1,0) [0|15] ""  BCM
 SG_ Digit_06_NGE : 19|4@0+ (1,0) [0|15] ""  BCM
 SG_ Digit_07_NGE : 23|4@0+ (1,0) [0|15] ""  BCM
 SG_ Digit_04_NGE : 27|4@0+ (1,0) [0|15] ""  BCM
 SG_ Digit_05_NGE : 31|4@0+ (1,0) [0|15] ""  BCM
 SG_ Digit_02_NGE : 35|4@0+ (1,0) [0|15] ""  BCM
 SG_ Digit_03_NGE : 39|4@0+ (1,0) [0|15] ""  BCM
 SG_ Digit_01_NGE : 47|4@0+ (1,0) [0|15] ""  BCM

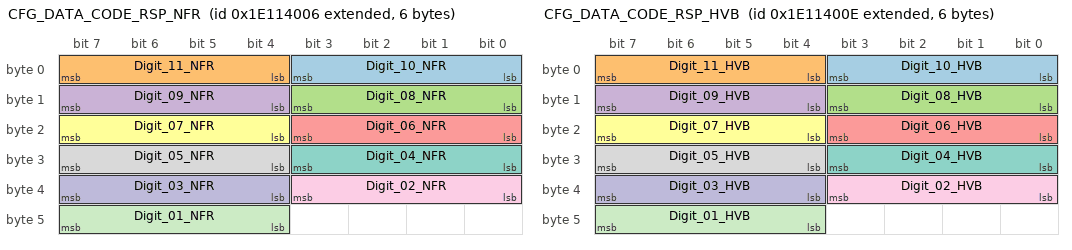
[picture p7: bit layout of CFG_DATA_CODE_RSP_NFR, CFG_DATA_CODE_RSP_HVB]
BO_ 2651930630 CFG_DATA_CODE_RSP_NFR: 6 SGW
 SG_ Digit_10_NFR : 3|4@0+ (1,0) [0|15] ""  BCM
 SG_ Digit_11_NFR : 7|4@0+ (1,0) [0|15] ""  BCM
 SG_ Digit_08_NFR : 11|4@0+ (1,0) [0|15] ""  BCM
 SG_ Digit_09_NFR : 15|4@0+ (1,0) [0|15] ""  BCM
 SG_ Digit_06_NFR : 19|4@0+ (1,0) [0|15] ""  BCM
 SG_ Digit_07_NFR : 23|4@0+ (1,0) [0|15] ""  BCM
 SG_ Digit_04_NFR : 27|4@0+ (1,0) [0|15] ""  BCM
 SG_ Digit_05_NFR : 31|4@0+ (1,0) [0|15] ""  BCM
 SG_ Digit_02_NFR : 35|4@0+ (1,0) [0|15] ""  BCM
 SG_ Digit_03_NFR : 39|4@0+ (1,0) [0|15] ""  BCM
 SG_ Digit_01_NFR : 47|4@0+ (1,0) [0|15] ""  BCM

BO_ 2651930638 CFG_DATA_CODE_RSP_HVB: 6 SGW
 SG_ Digit_10_HVB : 3|4@0+ (1,0) [0|15] ""  BCM
 SG_ Digit_11_HVB : 7|4@0+ (1,0) [0|15] ""  BCM
 SG_ Digit_08_HVB : 11|4@0+ (1,0) [0|15] ""  BCM
 SG_ Digit_09_HVB : 15|4@0+ (1,0) [0|15] ""  BCM
 SG_ Digit_06_HVB : 19|4@0+ (1,0) [0|15] ""  BCM
 SG_ Digit_07_HVB : 23|4@0+ (1,0) [0|15] ""  BCM
 SG_ Digit_04_HVB : 27|4@0+ (1,0) [0|15] ""  BCM
 SG_ Digit_05_HVB : 31|4@0+ (1,0) [0|15] ""  BCM
 SG_ Digit_02_HVB : 35|4@0+ (1,0) [0|15] ""  BCM
 SG_ Digit_03_HVB : 39|4@0+ (1,0) [0|15] ""  BCM
 SG_ Digit_01_HVB : 47|4@0+ (1,0) [0|15] ""  BCM

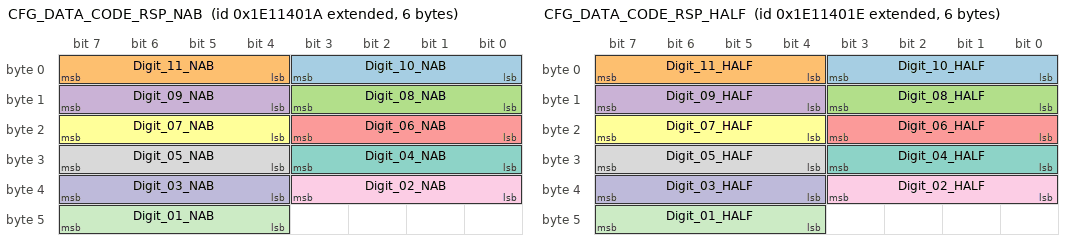
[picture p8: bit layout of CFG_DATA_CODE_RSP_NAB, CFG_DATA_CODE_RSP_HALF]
BO_ 2651930650 CFG_DATA_CODE_RSP_NAB: 6 NAB
 SG_ Digit_10_NAB : 3|4@0+ (1,0) [0|15] ""  BCM
 SG_ Digit_11_NAB : 7|4@0+ (1,0) [0|15] ""  BCM
 SG_ Digit_08_NAB : 11|4@0+ (1,0) [0|15] ""  BCM
 SG_ Digit_09_NAB : 15|4@0+ (1,0) [0|15] ""  BCM
 SG_ Digit_06_NAB : 19|4@0+ (1,0) [0|15] ""  BCM
 SG_ Digit_07_NAB : 23|4@0+ (1,0) [0|15] ""  BCM
 SG_ Digit_04_NAB : 27|4@0+ (1,0) [0|15] ""  BCM
 SG_ Digit_05_NAB : 31|4@0+ (1,0) [0|15] ""  BCM
 SG_ Digit_02_NAB : 35|4@0+ (1,0) [0|15] ""  BCM
 SG_ Digit_03_NAB : 39|4@0+ (1,0) [0|15] ""  BCM
 SG_ Digit_01_NAB : 47|4@0+ (1,0) [0|15] ""  BCM

BO_ 2651930654 CFG_DATA_CODE_RSP_HALF: 6 SGW
 SG_ Digit_10_HALF : 3|4@0+ (1,0) [0|15] ""  BCM
 SG_ Digit_11_HALF : 7|4@0+ (1,0) [0|15] ""  BCM
 SG_ Digit_08_HALF : 11|4@0+ (1,0) [0|15] ""  BCM
 SG_ Digit_09_HALF : 15|4@0+ (1,0) [0|15] ""  BCM
 SG_ Digit_06_HALF : 19|4@0+ (1,0) [0|15] ""  BCM
 SG_ Digit_07_HALF : 23|4@0+ (1,0) [0|15] ""  BCM
 SG_ Digit_04_HALF : 27|4@0+ (1,0) [0|15] ""  BCM
 SG_ Digit_05_HALF : 31|4@0+ (1,0) [0|15] ""  BCM
 SG_ Digit_02_HALF : 35|4@0+ (1,0) [0|15] ""  BCM
 SG_ Digit_03_HALF : 39|4@0+ (1,0) [0|15] ""  BCM
 SG_ Digit_01_HALF : 47|4@0+ (1,0) [0|15] ""  BCM

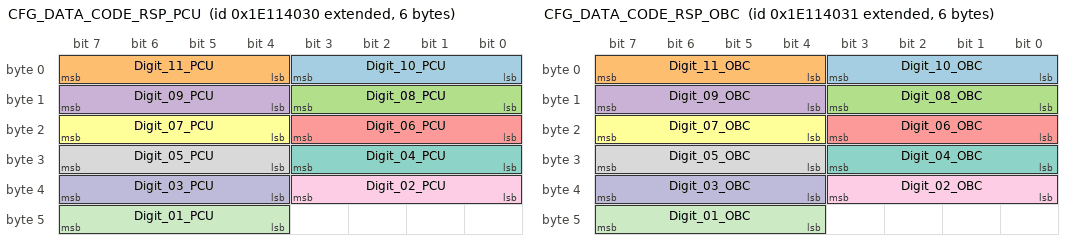
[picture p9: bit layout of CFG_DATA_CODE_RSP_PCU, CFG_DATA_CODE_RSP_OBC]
BO_ 2651930672 CFG_DATA_CODE_RSP_PCU: 6 SGW
 SG_ Digit_10_PCU : 3|4@0+ (1,0) [0|15] ""  BCM
 SG_ Digit_11_PCU : 7|4@0+ (1,0) [0|15] ""  BCM
 SG_ Digit_08_PCU : 11|4@0+ (1,0) [0|15] ""  BCM
 SG_ Digit_09_PCU : 15|4@0+ (1,0) [0|15] ""  BCM
 SG_ Digit_06_PCU : 19|4@0+ (1,0) [0|15] ""  BCM
 SG_ Digit_07_PCU : 23|4@0+ (1,0) [0|15] ""  BCM
 SG_ Digit_04_PCU : 27|4@0+ (1,0) [0|15] ""  BCM
 SG_ Digit_05_PCU : 31|4@0+ (1,0) [0|15] ""  BCM
 SG_ Digit_02_PCU : 35|4@0+ (1,0) [0|15] ""  BCM
 SG_ Digit_03_PCU : 39|4@0+ (1,0) [0|15] ""  BCM
 SG_ Digit_01_PCU : 47|4@0+ (1,0) [0|15] ""  BCM

BO_ 2651930673 CFG_DATA_CODE_RSP_OBC: 6 SGW
 SG_ Digit_10_OBC : 3|4@0+ (1,0) [0|15] ""  BCM
 SG_ Digit_11_OBC : 7|4@0+ (1,0) [0|15] ""  BCM
 SG_ Digit_08_OBC : 11|4@0+ (1,0) [0|15] ""  BCM
 SG_ Digit_09_OBC : 15|4@0+ (1,0) [0|15] ""  BCM
 SG_ Digit_06_OBC : 19|4@0+ (1,0) [0|15] ""  BCM
 SG_ Digit_07_OBC : 23|4@0+ (1,0) [0|15] ""  BCM
 SG_ Digit_04_OBC : 27|4@0+ (1,0) [0|15] ""  BCM
 SG_ Digit_05_OBC : 31|4@0+ (1,0) [0|15] ""  BCM
 SG_ Digit_02_OBC : 35|4@0+ (1,0) [0|15] ""  BCM
 SG_ Digit_03_OBC : 39|4@0+ (1,0) [0|15] ""  BCM
 SG_ Digit_01_OBC : 47|4@0+ (1,0) [0|15] ""  BCM

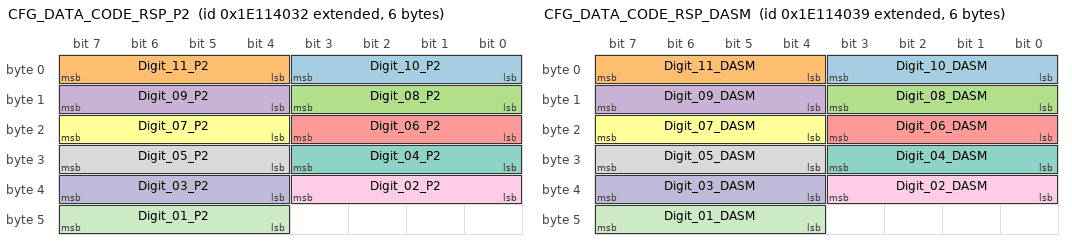
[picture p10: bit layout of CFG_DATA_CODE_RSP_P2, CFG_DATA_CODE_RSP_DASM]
BO_ 2651930674 CFG_DATA_CODE_RSP_P2: 6 SGW
 SG_ Digit_10_P2 : 3|4@0+ (1,0) [0|15] ""  BCM
 SG_ Digit_11_P2 : 7|4@0+ (1,0) [0|15] ""  BCM
 SG_ Digit_08_P2 : 11|4@0+ (1,0) [0|15] ""  BCM
 SG_ Digit_09_P2 : 15|4@0+ (1,0) [0|15] ""  BCM
 SG_ Digit_06_P2 : 19|4@0+ (1,0) [0|15] ""  BCM
 SG_ Digit_07_P2 : 23|4@0+ (1,0) [0|15] ""  BCM
 SG_ Digit_04_P2 : 27|4@0+ (1,0) [0|15] ""  BCM
 SG_ Digit_05_P2 : 31|4@0+ (1,0) [0|15] ""  BCM
 SG_ Digit_02_P2 : 35|4@0+ (1,0) [0|15] ""  BCM
 SG_ Digit_03_P2 : 39|4@0+ (1,0) [0|15] ""  BCM
 SG_ Digit_01_P2 : 47|4@0+ (1,0) [0|15] ""  BCM

BO_ 2651930681 CFG_DATA_CODE_RSP_DASM: 6 SGW
 SG_ Digit_10_DASM : 3|4@0+ (1,0) [0|15] ""  BCM
 SG_ Digit_11_DASM : 7|4@0+ (1,0) [0|15] ""  BCM
 SG_ Digit_08_DASM : 11|4@0+ (1,0) [0|15] ""  BCM
 SG_ Digit_09_DASM : 15|4@0+ (1,0) [0|15] ""  BCM
 SG_ Digit_06_DASM : 19|4@0+ (1,0) [0|15] ""  BCM
 SG_ Digit_07_DASM : 23|4@0+ (1,0) [0|15] ""  BCM
 SG_ Digit_04_DASM : 27|4@0+ (1,0) [0|15] ""  BCM
 SG_ Digit_05_DASM : 31|4@0+ (1,0) [0|15] ""  BCM
 SG_ Digit_02_DASM : 35|4@0+ (1,0) [0|15] ""  BCM
 SG_ Digit_03_DASM : 39|4@0+ (1,0) [0|15] ""  BCM
 SG_ Digit_01_DASM : 47|4@0+ (1,0) [0|15] ""  BCM

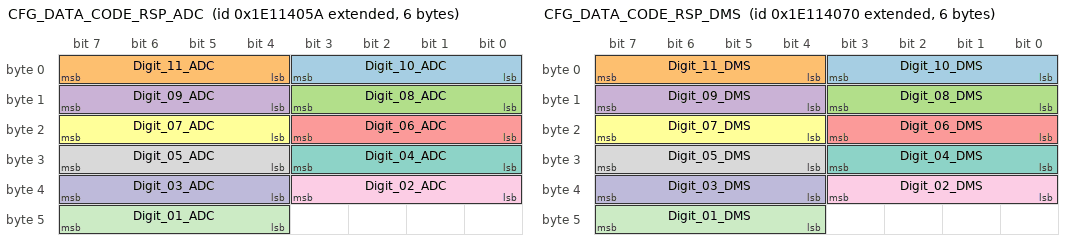
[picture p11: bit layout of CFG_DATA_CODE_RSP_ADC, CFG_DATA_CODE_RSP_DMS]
BO_ 2651930714 CFG_DATA_CODE_RSP_ADC: 6 SGW
 SG_ Digit_10_ADC : 3|4@0+ (1,0) [0|15] ""  BCM
 SG_ Digit_11_ADC : 7|4@0+ (1,0) [0|15] ""  BCM
 SG_ Digit_08_ADC : 11|4@0+ (1,0) [0|15] ""  BCM
 SG_ Digit_09_ADC : 15|4@0+ (1,0) [0|15] ""  BCM
 SG_ Digit_06_ADC : 19|4@0+ (1,0) [0|15] ""  BCM
 SG_ Digit_07_ADC : 23|4@0+ (1,0) [0|15] ""  BCM
 SG_ Digit_04_ADC : 27|4@0+ (1,0) [0|15] ""  BCM
 SG_ Digit_05_ADC : 31|4@0+ (1,0) [0|15] ""  BCM
 SG_ Digit_02_ADC : 35|4@0+ (1,0) [0|15] ""  BCM
 SG_ Digit_03_ADC : 39|4@0+ (1,0) [0|15] ""  BCM
 SG_ Digit_01_ADC : 47|4@0+ (1,0) [0|15] ""  BCM

BO_ 2651930736 CFG_DATA_CODE_RSP_DMS: 6 DMS
 SG_ Digit_10_DMS : 3|4@0+ (1,0) [0|15] ""  BCM
 SG_ Digit_11_DMS : 7|4@0+ (1,0) [0|15] ""  BCM
 SG_ Digit_08_DMS : 11|4@0+ (1,0) [0|15] ""  BCM
 SG_ Digit_09_DMS : 15|4@0+ (1,0) [0|15] ""  BCM
 SG_ Digit_06_DMS : 19|4@0+ (1,0) [0|15] ""  BCM
 SG_ Digit_07_DMS : 23|4@0+ (1,0) [0|15] ""  BCM
 SG_ Digit_04_DMS : 27|4@0+ (1,0) [0|15] ""  BCM
 SG_ Digit_05_DMS : 31|4@0+ (1,0) [0|15] ""  BCM
 SG_ Digit_02_DMS : 35|4@0+ (1,0) [0|15] ""  BCM
 SG_ Digit_03_DMS : 39|4@0+ (1,0) [0|15] ""  BCM
 SG_ Digit_01_DMS : 47|4@0+ (1,0) [0|15] ""  BCM

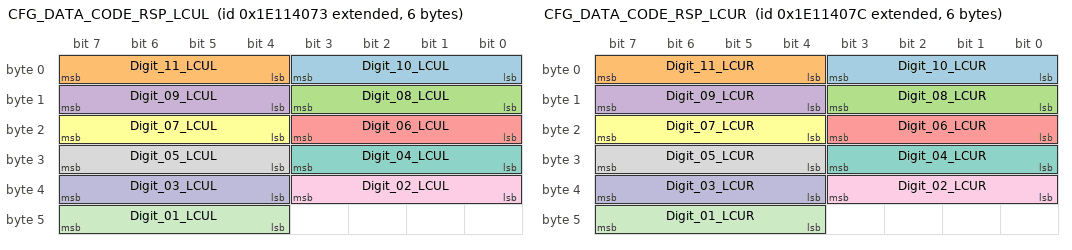
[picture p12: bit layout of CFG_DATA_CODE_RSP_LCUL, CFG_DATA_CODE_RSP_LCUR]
BO_ 2651930739 CFG_DATA_CODE_RSP_LCUL: 6 SGW
 SG_ Digit_10_LCUL : 3|4@0+ (1,0) [0|15] ""  BCM
 SG_ Digit_11_LCUL : 7|4@0+ (1,0) [0|15] ""  BCM
 SG_ Digit_08_LCUL : 11|4@0+ (1,0) [0|15] ""  BCM
 SG_ Digit_09_LCUL : 15|4@0+ (1,0) [0|15] ""  BCM
 SG_ Digit_06_LCUL : 19|4@0+ (1,0) [0|15] ""  BCM
 SG_ Digit_07_LCUL : 23|4@0+ (1,0) [0|15] ""  BCM
 SG_ Digit_04_LCUL : 27|4@0+ (1,0) [0|15] ""  BCM
 SG_ Digit_05_LCUL : 31|4@0+ (1,0) [0|15] ""  BCM
 SG_ Digit_02_LCUL : 35|4@0+ (1,0) [0|15] ""  BCM
 SG_ Digit_03_LCUL : 39|4@0+ (1,0) [0|15] ""  BCM
 SG_ Digit_01_LCUL : 47|4@0+ (1,0) [0|15] ""  BCM

BO_ 2651930748 CFG_DATA_CODE_RSP_LCUR: 6 SGW
 SG_ Digit_10_LCUR : 3|4@0+ (1,0) [0|15] ""  BCM
 SG_ Digit_11_LCUR : 7|4@0+ (1,0) [0|15] ""  BCM
 SG_ Digit_08_LCUR : 11|4@0+ (1,0) [0|15] ""  BCM
 SG_ Digit_09_LCUR : 15|4@0+ (1,0) [0|15] ""  BCM
 SG_ Digit_06_LCUR : 19|4@0+ (1,0) [0|15] ""  BCM
 SG_ Digit_07_LCUR : 23|4@0+ (1,0) [0|15] ""  BCM
 SG_ Digit_04_LCUR : 27|4@0+ (1,0) [0|15] ""  BCM
 SG_ Digit_05_LCUR : 31|4@0+ (1,0) [0|15] ""  BCM
 SG_ Digit_02_LCUR : 35|4@0+ (1,0) [0|15] ""  BCM
 SG_ Digit_03_LCUR : 39|4@0+ (1,0) [0|15] ""  BCM
 SG_ Digit_01_LCUR : 47|4@0+ (1,0) [0|15] ""  BCM

BO_ 2654208000 WAKE_C_NBC: 8 BCM
 SG_ WakeRsn_BCM : 6|7@0+ (1,0) [0|127] ""  SGW
 SG_ MainWakeSts_BCM : 7|1@0+ (1,0) [0|1] ""  DMS,NAB,SGW
 SG_ WakeCntr_BCM : 15|8@0+ (1,0) [0|255] ""  SGW
 SG_ Node24 : 16|1@0+ (1,0) [0|1] ""  SGW
 SG_ Node25 : 17|1@0+ (1,0) [0|1] ""  SGW
 SG_ Node26 : 18|1@0+ (1,0) [0|1] ""  SGW
 SG_ Node27 : 19|1@0+ (1,0) [0|1] ""  SGW
 SG_ Node28 : 20|1@0+ (1,0) [0|1] ""  SGW
 SG_ Node29 : 21|1@0+ (1,0) [0|1] ""  SGW
 SG_ Node30 : 22|1@0+ (1,0) [0|1] ""  SGW
 SG_ Node31 : 23|1@0+ (1,0) [0|1] ""  SGW
 SG_ Node16 : 24|1@0+ (1,0) [0|1] ""  SGW
 SG_ Node17 : 25|1@0+ (1,0) [0|1] ""  SGW
 SG_ Node18 : 26|1@0+ (1,0) [0|1] ""  SGW
 SG_ Node19 : 27|1@0+ (1,0) [0|1] ""  SGW
 SG_ Node20 : 28|1@0+ (1,0) [0|1] ""  SGW
 SG_ Node21 : 29|1@0+ (1,0) [0|1] ""  SGW
 SG_ Node22 : 30|1@0+ (1,0) [0|1] ""  SGW
 SG_ Node23 : 31|1@0+ (1,0) [0|1] ""  SGW
 SG_ Node8 : 32|1@0+ (1,0) [0|1] ""  SGW
 SG_ Node9 : 33|1@0+ (1,0) [0|1] ""  NAB,SGW
 SG_ Node10 : 34|1@0+ (1,0) [0|1] ""  SGW
 SG_ Node11 : 35|1@0+ (1,0) [0|1] ""  SGW
 SG_ Node12 : 36|1@0+ (1,0) [0|1] ""  SGW
 SG_ Node13 : 37|1@0+ (1,0) [0|1] ""  SGW
 SG_ Node14 : 38|1@0+ (1,0) [0|1] ""  SGW
 SG_ Node15 : 39|1@0+ (1,0) [0|1] ""  SGW
 SG_ Node0 : 40|1@0+ (1,0) [0|1] ""  DMS,NAB,SGW
 SG_ Node1 : 41|1@0+ (1,0) [0|1] ""  SGW
 SG_ Node2 : 42|1@0+ (1,0) [0|1] ""  SGW
 SG_ Node3 : 43|1@0+ (1,0) [0|1] ""  SGW
 SG_ Node4 : 44|1@0+ (1,0) [0|1] ""  SGW
 SG_ Node5 : 45|1@0+ (1,0) [0|1] ""  SGW
 SG_ Node6 : 46|1@0+ (1,0) [0|1] ""  SGW
 SG_ Node7 : 47|1@0+ (1,0) [0|1] ""  SGW

BO_ 2654208001 WAKE_C_NCM: 4 SGW
 SG_ WakeRsn_NCM : 6|7@0+ (1,0) [0|127] ""  BCM
 SG_ WakeReq_NCM : 7|1@0+ (1,0) [0|1] ""  BCM
 SG_ WakeCntr_NCM : 15|8@0+ (1,0) [0|255] ""  BCM
 SG_ WakeUpNodeAddress : 23|8@0+ (1,0) [0|255] ""  BCM

BO_ 2654208006 WAKE_C_NFR: 4 SGW
 SG_ WakeRsn_NFR : 6|7@0+ (1,0) [0|127] ""  BCM
 SG_ WakeReq_NFR : 7|1@0+ (1,0) [0|1] ""  BCM
 SG_ WakeCntr_NFR : 15|8@0+ (1,0) [0|255] ""  BCM
 SG_ WakeUpNodeAddress : 23|8@0+ (1,0) [0|255] ""  BCM

BO_ 2654208014 WAKE_C_HVB: 4 SGW
 SG_ WakeRsn_HVB : 6|7@0+ (1,0) [0|127] ""  BCM
 SG_ WakeReq_HVB : 7|1@0+ (1,0) [0|1] ""  BCM
 SG_ WakeCntr_HVB : 15|8@0+ (1,0) [0|255] ""  BCM
 SG_ WakeUpNodeAddress : 23|8@0+ (1,0) [0|255] ""  BCM

BO_ 2654208026 WAKE_C_NAB: 4 NAB
 SG_ WakeRsn_NAB : 6|7@0+ (1,0) [0|127] ""  BCM
 SG_ WakeReq_NAB : 7|1@0+ (1,0) [0|1] ""  BCM
 SG_ WakeCntr_NAB : 15|8@0+ (1,0) [0|255] ""  BCM
 SG_ WakeUpNodeAddress : 23|8@0+ (1,0) [0|255] ""  BCM

BO_ 2654208028 WAKE_C_NTP: 4 SGW
 SG_ WakeRsn_NTP : 6|7@0+ (1,0) [0|127] ""  BCM
 SG_ WakeReq_NTP : 7|1@0+ (1,0) [0|1] ""  BCM
 SG_ WakeCntr_NTP : 15|8@0+ (1,0) [0|255] ""  BCM
 SG_ WakeUpNodeAddress : 23|8@0+ (1,0) [0|255] ""  BCM

BO_ 2654208048 WAKE_C_PCU: 4 SGW
 SG_ WakeRsn_PCU : 6|7@0+ (1,0) [0|127] ""  BCM
 SG_ WakeReq_PCU : 7|1@0+ (1,0) [0|1] ""  BCM
 SG_ WakeCntr_PCU : 15|8@0+ (1,0) [0|255] ""  BCM
 SG_ WakeUpNodeAddress : 23|8@0+ (1,0) [0|255] ""  BCM

BO_ 2654208049 WAKE_C_OBC: 4 SGW
 SG_ WakeRsn_OBC : 6|7@0+ (1,0) [0|127] ""  BCM
 SG_ WakeReq_OBC : 7|1@0+ (1,0) [0|1] ""  BCM
 SG_ WakeCntr_OBC : 15|8@0+ (1,0) [0|255] ""  BCM
 SG_ WakeUpNodeAddress : 23|8@0+ (1,0) [0|255] ""  BCM

BO_ 2654208050 WAKE_C_P2: 4 SGW
 SG_ WakeRsn_P2 : 6|7@0+ (1,0) [0|127] ""  BCM
 SG_ WakeReq_P2 : 7|1@0+ (1,0) [0|1] ""  BCM
 SG_ WakeCntr_P2 : 15|8@0+ (1,0) [0|255] ""  BCM
 SG_ WakeUpNodeAddress : 23|8@0+ (1,0) [0|255] ""  BCM

BO_ 2654208089 WAKE_C_SGW: 4 SGW
 SG_ WakeRsn_SGW : 6|7@0+ (1,0) [0|127] ""  BCM
 SG_ WakeReq_SGW : 7|1@0+ (1,0) [0|1] ""  BCM
 SG_ WakeCntr_SGW : 15|8@0+ (1,0) [0|255] ""  BCM
 SG_ WakeUpNodeAddress_SGW : 23|8@0+ (1,0) [0|255] ""  BCM

BO_ 2654208090 WAKE_C_ADC: 4 SGW
 SG_ WakeRsn_ADC : 6|7@0+ (1,0) [0|127] ""  BCM
 SG_ WakeReq_ADC : 7|1@0+ (1,0) [0|1] ""  BCM
 SG_ WakeCntr_ADC : 15|8@0+ (1,0) [0|255] ""  BCM
 SG_ WakeUpNodeAddress : 23|8@0+ (1,0) [0|255] ""  BCM

BO_ 2654208112 WAKE_C_DMS: 4 DMS
 SG_ WakeRsn_DMS : 6|7@0+ (1,0) [0|127] ""  BCM
 SG_ WakeReq_DMS : 7|1@0+ (1,0) [0|1] ""  BCM
 SG_ WakeCntr_DMS : 15|8@0+ (1,0) [0|255] ""  BCM
 SG_ WakeUpNodeAddress_DMS : 23|8@0+ (1,0) [0|255] ""  BCM

BO_ 2654208125 WAKE_C_BES: 4 SGW
 SG_ WakeRsn_BES : 6|7@0+ (1,0) [0|127] ""  BCM
 SG_ WakeReq_BES : 7|1@0+ (1,0) [0|1] ""  BCM
 SG_ WakeCntr_BES : 15|8@0+ (1,0) [0|255] ""  BCM
 SG_ WakeUpNodeAddress_BES : 23|8@0+ (1,0) [0|255] ""  BCM

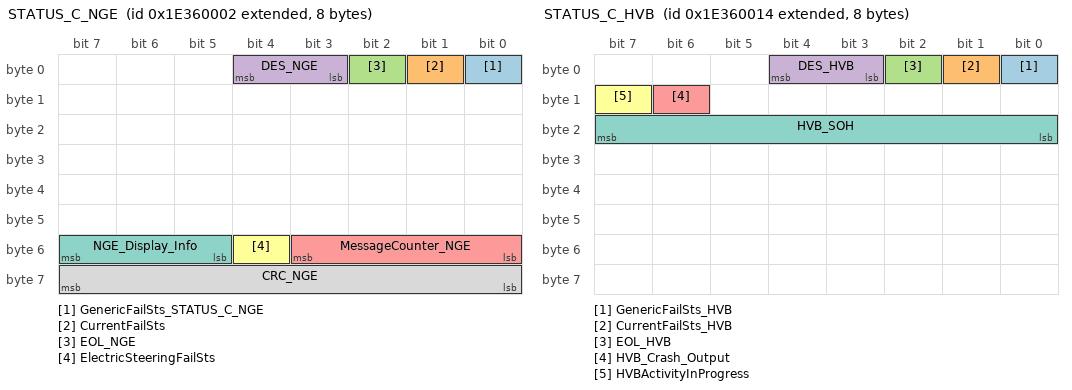
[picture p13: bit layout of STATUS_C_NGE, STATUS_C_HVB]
BO_ 2654339074 STATUS_C_NGE: 8 SGW
 SG_ GenericFailSts_STATUS_C_NGE : 0|1@0+ (1,0) [0|1] ""  BCM
 SG_ CurrentFailSts : 1|1@0+ (1,0) [0|1] ""  BCM
 SG_ EOL_NGE : 2|1@0+ (1,0) [0|1] ""  BCM
 SG_ DES_NGE : 4|2@0+ (1,0) [0|3] ""  BCM
 SG_ MessageCounter_NGE : 51|4@0+ (1,0) [0|15] ""  BCM,NQS
 SG_ ElectricSteeringFailSts : 52|1@0+ (1,0) [0|1] ""  NDG,NQS
 SG_ NGE_Display_Info : 55|3@0+ (1,0) [0|7] ""  NDG,NQS
 SG_ CRC_NGE : 63|8@0+ (1,0) [0|255] ""  BCM,NQS

BO_ 2654339092 STATUS_C_HVB: 8 SGW
 SG_ GenericFailSts_HVB : 0|1@0+ (1,0) [0|1] ""  BCM
 SG_ CurrentFailSts_HVB : 1|1@0+ (1,0) [0|1] ""  BCM
 SG_ EOL_HVB : 2|1@0+ (1,0) [0|1] ""  BCM
 SG_ DES_HVB : 4|2@0+ (1,0) [0|3] ""  BCM
 SG_ HVB_Crash_Output : 14|1@0+ (1,0) [0|1] ""  BCM
 SG_ HVBActivityInProgress : 15|1@0+ (1,0) [0|1] ""  BCM
 SG_ HVB_SOH : 23|8@0+ (0.392156862745098,0) [0|100] "%"  NDG

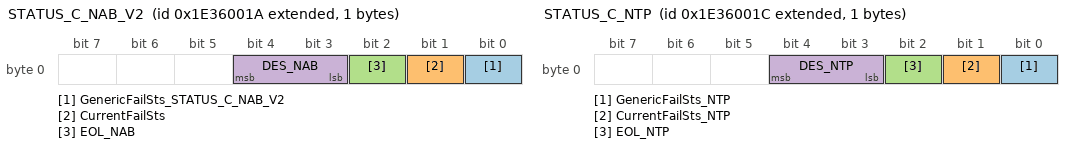
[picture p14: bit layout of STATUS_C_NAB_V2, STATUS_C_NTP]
BO_ 2654339098 STATUS_C_NAB_V2: 1 NAB
 SG_ GenericFailSts_STATUS_C_NAB_V2 : 0|1@0+ (1,0) [0|1] ""  BCM
 SG_ CurrentFailSts : 1|1@0+ (1,0) [0|1] ""  BCM
 SG_ EOL_NAB : 2|1@0+ (1,0) [0|1] ""  BCM
 SG_ DES_NAB : 4|2@0+ (1,0) [0|3] ""  BCM

BO_ 2654339100 STATUS_C_NTP: 1 SGW
 SG_ GenericFailSts_NTP : 0|1@0+ (1,0) [0|1] ""  BCM
 SG_ CurrentFailSts_NTP : 1|1@0+ (1,0) [0|1] ""  BCM
 SG_ EOL_NTP : 2|1@0+ (1,0) [0|1] ""  BCM
 SG_ DES_NTP : 4|2@0+ (1,0) [0|3] ""  BCM

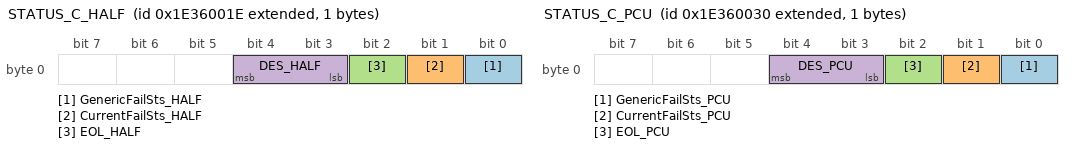
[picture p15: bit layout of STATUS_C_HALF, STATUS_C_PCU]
BO_ 2654339102 STATUS_C_HALF: 1 SGW
 SG_ GenericFailSts_HALF : 0|1@0+ (1,0) [0|1] ""  BCM
 SG_ CurrentFailSts_HALF : 1|1@0+ (1,0) [0|1] ""  BCM
 SG_ EOL_HALF : 2|1@0+ (1,0) [0|1] ""  BCM
 SG_ DES_HALF : 4|2@0+ (1,0) [0|3] ""  BCM

BO_ 2654339120 STATUS_C_PCU: 1 SGW
 SG_ GenericFailSts_PCU : 0|1@0+ (1,0) [0|1] ""  BCM
 SG_ CurrentFailSts_PCU : 1|1@0+ (1,0) [0|1] ""  BCM
 SG_ EOL_PCU : 2|1@0+ (1,0) [0|1] ""  BCM
 SG_ DES_PCU : 4|2@0+ (1,0) [0|3] ""  BCM

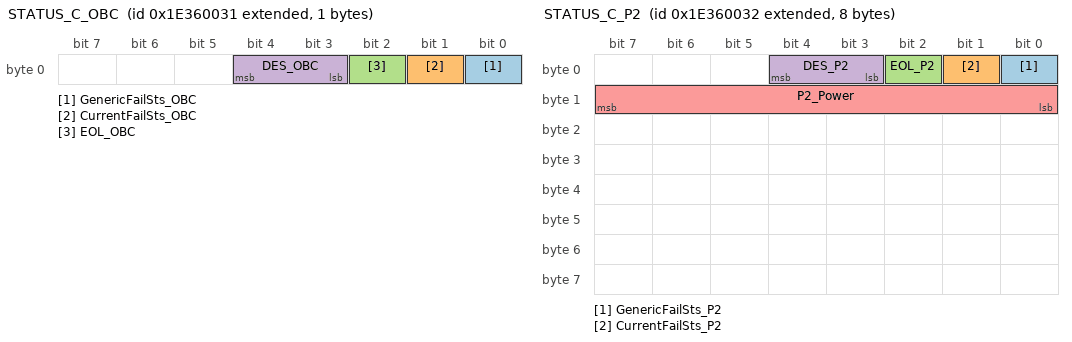
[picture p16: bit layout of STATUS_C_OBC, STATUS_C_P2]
BO_ 2654339121 STATUS_C_OBC: 1 SGW
 SG_ GenericFailSts_OBC : 0|1@0+ (1,0) [0|1] ""  BCM
 SG_ CurrentFailSts_OBC : 1|1@0+ (1,0) [0|1] ""  BCM
 SG_ EOL_OBC : 2|1@0+ (1,0) [0|1] ""  BCM
 SG_ DES_OBC : 4|2@0+ (1,0) [0|3] ""  BCM

BO_ 2654339122 STATUS_C_P2: 8 SGW
 SG_ GenericFailSts_P2 : 0|1@0+ (1,0) [0|1] ""  BCM
 SG_ CurrentFailSts_P2 : 1|1@0+ (1,0) [0|1] ""  BCM
 SG_ EOL_P2 : 2|1@0+ (1,0) [0|1] ""  BCM
 SG_ DES_P2 : 4|2@0+ (1,0) [0|3] ""  BCM
 SG_ P2_Power : 15|8@0+ (2,-254) [-254|254] "kW"  NQS

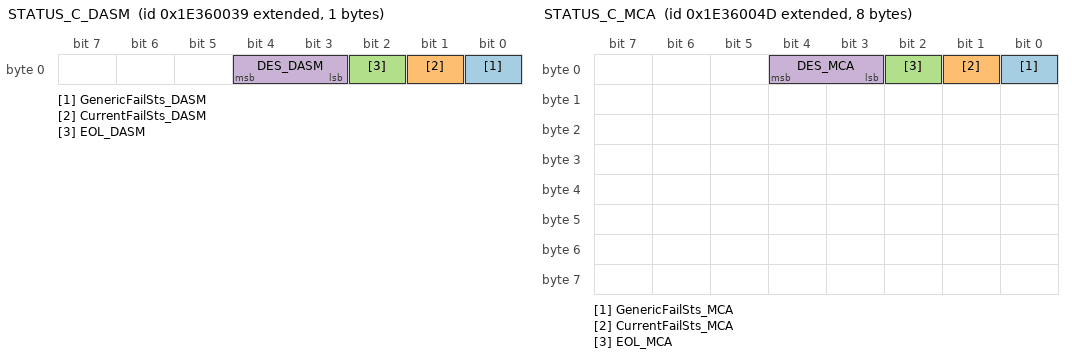
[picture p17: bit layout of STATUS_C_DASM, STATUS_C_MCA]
BO_ 2654339129 STATUS_C_DASM: 1 SGW
 SG_ GenericFailSts_DASM : 0|1@0+ (1,0) [0|1] ""  BCM
 SG_ CurrentFailSts_DASM : 1|1@0+ (1,0) [0|1] ""  BCM
 SG_ EOL_DASM : 2|1@0+ (1,0) [0|1] ""  BCM
 SG_ DES_DASM : 4|2@0+ (1,0) [0|3] ""  BCM

BO_ 2654339149 STATUS_C_MCA: 8 SGW
 SG_ GenericFailSts_MCA : 0|1@0+ (1,0) [0|1] ""  BCM
 SG_ CurrentFailSts_MCA : 1|1@0+ (1,0) [0|1] ""  BCM
 SG_ EOL_MCA : 2|1@0+ (1,0) [0|1] ""  BCM
 SG_ DES_MCA : 4|2@0+ (1,0) [0|3] ""  BCM

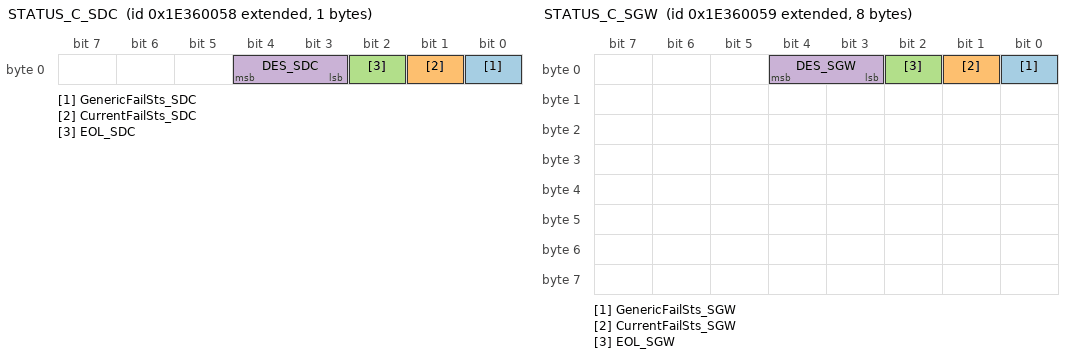
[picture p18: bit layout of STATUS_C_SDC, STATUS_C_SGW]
BO_ 2654339160 STATUS_C_SDC: 1 SGW
 SG_ GenericFailSts_SDC : 0|1@0+ (1,0) [0|1] ""  BCM
 SG_ CurrentFailSts_SDC : 1|1@0+ (1,0) [0|1] ""  BCM
 SG_ EOL_SDC : 2|1@0+ (1,0) [0|1] ""  BCM
 SG_ DES_SDC : 4|2@0+ (1,0) [0|3] ""  BCM

BO_ 2654339161 STATUS_C_SGW: 8 SGW
 SG_ GenericFailSts_SGW : 0|1@0+ (1,0) [0|1] ""  BCM
 SG_ CurrentFailSts_SGW : 1|1@0+ (1,0) [0|1] ""  BCM
 SG_ EOL_SGW : 2|1@0+ (1,0) [0|1] ""  BCM
 SG_ DES_SGW : 4|2@0+ (1,0) [0|3] ""  BCM

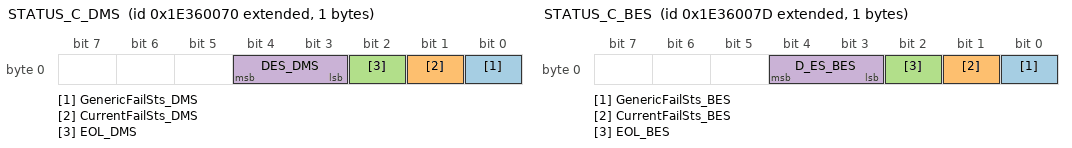
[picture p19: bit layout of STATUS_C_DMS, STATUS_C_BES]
BO_ 2654339184 STATUS_C_DMS: 1 DMS
 SG_ GenericFailSts_DMS : 0|1@0+ (1,0) [0|1] ""  BCM
 SG_ CurrentFailSts_DMS : 1|1@0+ (1,0) [0|1] ""  BCM
 SG_ EOL_DMS : 2|1@0+ (1,0) [0|1] ""  BCM
 SG_ DES_DMS : 4|2@0+ (1,0) [0|3] ""  BCM

BO_ 2654339187 STATUS_C_LCUL: 8 SGW
 SG_ GenericFailSts_STATUS_C_LCUL_C1 : 0|1@0+ (1,0) [0|1] ""  BCM
 SG_ CurrentFailSts_LCUL_C1 : 1|1@0+ (1,0) [0|1] ""  BCM
 SG_ EOL_LCUL_C1 : 2|1@0+ (1,0) [0|1] ""  BCM
 SG_ D_ES_LCUL_C1 : 4|2@0+ (1,0) [0|3] ""  BCM
 SG_ Left_LB_Feedback_LCUL_C1 : 8|1@0+ (1,0) [0|1] ""  BCM
 SG_ Left_LB_FailSts : 9|1@0+ (1,0) [0|1] ""  NQS
 SG_ Left_HB_Feedback_LCUL_C1 : 10|1@0+ (1,0) [0|1] ""  BCM
 SG_ Left_HB_FailSts : 11|1@0+ (1,0) [0|1] ""  NQS
 SG_ Left_PL_Feedback_LCUL_C1 : 12|1@0+ (1,0) [0|1] ""  BCM,NQS
 SG_ Left_PL_FailSts : 13|1@0+ (1,0) [0|1] ""  NQS
 SG_ Left_DRL_Feedback_LCUL_C1 : 14|1@0+ (1,0) [0|1] ""  BCM,NQS
 SG_ Left_DRL_FailSts : 15|1@0+ (1,0) [0|1] ""  NQS
 SG_ Left_TI_Feedback_LCUL_C1 : 16|1@0+ (1,0) [0|1] ""  BCM
 SG_ Left_TI_FailSts_LCUL_C1 : 17|1@0+ (1,0) [0|1] ""  BCM
 SG_ Left_LVL_FailSts : 18|1@0+ (1,0) [0|1] ""  NQS
 SG_ Left_FBLFaiLSts : 19|1@0+ (1,0) [0|1] ""  NQS
 SG_ ADB_FailSts_LH : 20|1@0+ (1,0) [0|1] ""  NQS
 SG_ Left_ParkingLight_Feedback_LCUL1 : 21|1@0+ (1,0) [0|1] ""  BCM
 SG_ Left_TrafficChangeFbk : 23|2@0+ (1,0) [0|3] ""  NQS
 SG_ Left_DodecaDriver_Failure : 24|1@0+ (1,0) [0|1] ""  NQS
 SG_ MsgCounter_LCULSts : 51|4@0+ (1,0) [0|15] ""  BCM,NQS
 SG_ Checksum_LCULSts : 63|8@0+ (1,0) [0|255] ""  BCM,NQS

BO_ 2654339196 STATUS_C_LCUR: 8 SGW
 SG_ GenericFailSts_LCUR_C1 : 0|1@0+ (1,0) [0|1] ""  BCM
 SG_ CurrentFailSts_LCUR_C1 : 1|1@0+ (1,0) [0|1] ""  BCM
 SG_ EOL_LCUR_C1 : 2|1@0+ (1,0) [0|1] ""  BCM
 SG_ D_ES_LCUR_C1 : 4|2@0+ (1,0) [0|3] ""  BCM
 SG_ Right_LB_Feedback_LCUR_C1 : 8|1@0+ (1,0) [0|1] ""  BCM
 SG_ Right_LB_FailSts : 9|1@0+ (1,0) [0|1] ""  NQS
 SG_ Right_HB_Feedback_LCUR_C1 : 10|1@0+ (1,0) [0|1] ""  BCM
 SG_ Right_HB_FailSts : 11|1@0+ (1,0) [0|1] ""  NQS
 SG_ Right_PL_Feedback_LCUR_C1 : 12|1@0+ (1,0) [0|1] ""  BCM,NQS
 SG_ Right_PL_FailSts : 13|1@0+ (1,0) [0|1] ""  NQS
 SG_ Right_DRL_Feedback_LCUR_C1 : 14|1@0+ (1,0) [0|1] ""  BCM,NQS
 SG_ Right_DRL_FailSts : 15|1@0+ (1,0) [0|1] ""  NQS
 SG_ Right_TI_Feedback_LCUR_C1 : 16|1@0+ (1,0) [0|1] ""  BCM
 SG_ Right_TI_FailSts_LCUR_C1 : 17|1@0+ (1,0) [0|1] ""  BCM
 SG_ Right_LVL_FailSts : 18|1@0+ (1,0) [0|1] ""  NQS
 SG_ Right_FBLFaiLSts : 19|1@0+ (1,0) [0|1] ""  NQS
 SG_ ADB_FailSts_RH : 20|1@0+ (1,0) [0|1] ""  NQS
 SG_ Right_ParkingLight_Feedback_LCUR : 21|1@0+ (1,0) [0|1] ""  BCM
 SG_ Right_TrafficChangeFbk : 23|2@0+ (1,0) [0|3] ""  NQS
 SG_ Right_DodecaDriver_Failure : 24|1@0+ (1,0) [0|1] ""  NQS
 SG_ MsgCounter_LCURSts : 51|4@0+ (1,0) [0|15] ""  BCM,NQS
 SG_ Checksum_LCURSts : 63|8@0+ (1,0) [0|255] ""  BCM,NQS

BO_ 2654339197 STATUS_C_BES: 1 SGW
 SG_ GenericFailSts_BES : 0|1@0+ (1,0) [0|1] ""  BCM
 SG_ CurrentFailSts_BES : 1|1@0+ (1,0) [0|1] ""  BCM
 SG_ EOL_BES : 2|1@0+ (1,0) [0|1] ""  BCM
 SG_ D_ES_BES : 4|2@0+ (1,0) [0|3] ""  BCM

CM_ BO_ 1409 "{For F173: Sender = NCM_SX}";
CM_ SG_ 1441 EngineOilTemperature "Startup / Default value = -48°C. This value is not the real extenal temperature processed: it means means no valid data available";
CM_ SG_ 1441 StopStartVisualizationCode "Sent by NCM, signals to NQS the visualization to be show to the user";
CM_ SG_ 1441 EngineSts "This signal indicates the engine state.";
CM_ SG_ 1441 StopStartSts "Engine restart: active 80 mSec before restart, 3 seconds after engine ON";
CM_ BO_ 1442 "{For F173: Sender = NCM_SX}";
CM_ SG_ 1442 Oil_Quality_Estimation "0% - best Oil buality,  100% - bad oil quality ";
CM_ SG_ 1486 HybridSystemWarningForDisplay "see F803 for details about signal";
CM_ SG_ 1504 AVHDriverDoorSts "Sent by the body Computer that read directly the door ajar switch";
CM_ SG_ 1668 Hour2 "BCD CODED";
CM_ SG_ 1668 Hour1 "BCD CODED";
CM_ SG_ 1668 Minute2 "BCD CODED";
CM_ SG_ 1668 Minute1 "BCD CODED";
CM_ SG_ 1668 Day2 "BCD CODED";
CM_ SG_ 1668 Day1 "BCD CODED";
CM_ SG_ 1668 Month2 "BCD CODED";
CM_ SG_ 1668 Month1 "BCD CODED";
CM_ SG_ 1668 Year2 "BCD CODED";
CM_ SG_ 1668 Year1 "BCD CODED";
CM_ SG_ 1668 Year4 "BCD CODED";
CM_ SG_ 1668 Year3 "BCD CODED";
CM_ SG_ 1668 Second2 "BCD CODED";
CM_ SG_ 1668 Second1 "BCD CODED";
CM_ SG_ 1696 Hour2 "BCD CODED 
Hour always in 24 format";
CM_ SG_ 1696 Hour1 "BCD CODED 
Hour always in 24 format";
CM_ SG_ 1696 Minute2 "BCD CODED";
CM_ SG_ 1696 Minute1 "BCD CODED";
CM_ SG_ 1696 Day2 "BCD CODED";
CM_ SG_ 1696 Day1 "BCD CODED";
CM_ SG_ 1696 Month2 "BCD CODED";
CM_ SG_ 1696 Month1 "BCD CODED";
CM_ SG_ 1696 Year2 "BCD CODED";
CM_ SG_ 1696 Year1 "BCD CODED";
CM_ SG_ 1696 Year4 "BCD CODED";
CM_ SG_ 1696 Year3 "BCD CODED";
CM_ SG_ 1728 RearWheelCircumference "NFR USED THIS VALUE TO CALCULATE THE VSO SIGNAL, IN CASE OF WHEEL SPEED SENSOR ERROR , NFR WILL USE THE INTERNAL WHEEL CIRCUMFERENCE . ";
CM_ SG_ 1728 BatteryType "PROXI byte 87, bit 0-3";
CM_ SG_ 1728 NCMSoftwareVariant "Only for F149 and F142 the Variant 0 and Variant 4 are not available because invalid selection on NBC.
For F151 and F152 Variant 0 and 4 are allowed.";
CM_ SG_ 1728 Rear_Doors "{For F175: Sig_name = Rear_Doors}";
CM_ SG_ 1728 STOPANDSTART "The signal indicates the Stop&Start presence";
CM_ SG_ 1728 TrafficType "It?s the road side";
CM_ BO_ 1904 "Only for CCM debug shut off in production";
CM_ BO_ 1905 "Only for CCM debug shut off in production";
CM_ BO_ 1906 "Only for CCM debug shut off in production";
CM_ BO_ 1907 "Only for CCM debug shut off in production";
CM_ BO_ 1908 "Only for CCM debug shut off in production";
CM_ BO_ 1909 "Only for CCM debug shut off in production";
CM_ BO_ 1910 "Only for CCM debug shut off in production";
CM_ BO_ 1911 "Only for CCM debug shut off in production";
CM_ BO_ 1912 "Only for CCM debug shut off in production";
CM_ BO_ 1913 "Only for CCM debug shut off in production";
CM_ BO_ 1914 "Only for CCM debug shut off in production";
CM_ BO_ 1915 "Only for CCM debug shut off in production";
CM_ BO_ 1916 "Only for CCM debug shut off in production";
CM_ BO_ 1917 "Only for CCM debug shut off in production";
CM_ SG_ 1955 Oil_Quality_Estimation_NQS "0% - best Oil buality,  100% - bad oil quality ";
CM_ SG_ 2564440305 TPDU_DREQ_NBC "See spec. CS.00051";
CM_ SG_ 2564452593 TPDU_DREQ_WLMR "See spec. CS.00051";
CM_ SG_ 2564452849 TPDU_DREQ_WLML "See spec. CS.00051";
CM_ SG_ 2564460785 TPDU_DREQ_NPE "See spec. CS.00051";
CM_ SG_ 2564473073 TPDU_DREQ_NAB "See spec. CS.00051";
CM_ SG_ 2564478449 TPDU_DREQ_LCC "See spec. CS.00051";
CM_ SG_ 2564485488 TPDU_DRES_WLMR "See spec. CS.00051";
CM_ SG_ 2564485489 TPDU_DRES_WLML "See spec. CS.00051";
CM_ SG_ 2564485520 TPDU_DRES_NPE "See spec. CS.00051";
CM_ SG_ 2564485568 TPDU_DRES_NAB "See spec. CS.00051";
CM_ SG_ 2564485589 TPDU_DRES_LCC "See spec. CS.00051";
CM_ SG_ 2564554481 TPDU_UDSFUNC "See spec. CS.00051";
CM_ SG_ 2564554737 TPDU_EDRDATAREQ "See Speec CS.00051";
CM_ BO_ 2651930714 "used to ASC functionality";
CM_ BO_ 2651930736 "used to ASC functionality";
CM_ SG_ 2654339187 ADB_FailSts_LH "This fail refers to the functionality of Adaptive Driving Beam (ADB) of the left headlamp (e.g. Matrix High Beam)";
CM_ SG_ 2654339187 MsgCounter_LCULSts "SAE J1850";
CM_ SG_ 2654339187 Checksum_LCULSts "SAE J1850";
CM_ SG_ 2654339196 ADB_FailSts_RH "This fail refers to the functionality of Adaptive Driving Beam (ADB) of the right headlamp (e.g. Matrix High Beam)";
BA_DEF_ SG_  "GenSigSendType" ENUM  "NotUsed","OnWrite","OnWriteWithRepetition","OnChange","OnChangeWithRepetition","IfActive","IfActiveWithRepetition","NoSigSendType";
BA_DEF_ SG_  "GenSigInactiveValue" INT 0 2147483647;
BA_DEF_ SG_  "GenSigStartValue" INT 0 2147483647;
BA_DEF_ BO_  "DiagState" ENUM  "No","Yes";
BA_DEF_ BO_  "GenMsgDelayTime" INT 0 65535;
BA_DEF_ BO_  "GenMsgCycleTimeFast" INT 0 65535;
BA_DEF_ BO_  "GenMsgStartDelayTime" INT 0 65535;
BA_DEF_ BO_  "GenMsgILSupport" ENUM  "No","Yes";
BA_DEF_ BO_  "GenMsgNrOfRepetition" INT 0 255;
BA_DEF_ BO_  "GenMsgTimeoutTime" INT 0 10000;
BA_DEF_ BO_  "GenMsgSendType" ENUM  "Cyclic","NotUsed","NotUsed","NotUsed","NotUsed","NotUsed","NotUsed","NotUsed","NoMsgSendType";
BA_DEF_ BO_  "NmMessage" ENUM  "No","Yes";
BA_DEF_ BO_  "Type" ENUM  "P","C","PE","COC","PE_Cntrl","E","E_Cntrl","OC","S","BAF","DC","EM","MM","-";
BA_DEF_ BO_  "Period" INT 0 65535;
BA_DEF_ SG_  "EventTrans" ENUM  "Yes","No";
BA_DEF_ SG_  "Accuracy" STRING ;
BA_DEF_ SG_  "SignalAge" INT 0 100000;
BA_DEF_ SG_  "InitialValue" INT -65536 65535;
BA_DEF_ BO_  "DiagResponse" ENUM  "No","Yes";
BA_DEF_ BO_  "DiagRequest" ENUM  "No","Yes";
BA_DEF_ BO_  "GenMsgCycleTime" INT 0 10000;
BA_DEF_DEF_  "GenSigSendType" "NoSigSendType";
BA_DEF_DEF_  "GenSigInactiveValue" 0;
BA_DEF_DEF_  "GenSigStartValue" 0;
BA_DEF_DEF_  "DiagState" "No";
BA_DEF_DEF_  "GenMsgDelayTime" 0;
BA_DEF_DEF_  "GenMsgCycleTimeFast" 0;
BA_DEF_DEF_  "GenMsgStartDelayTime" 0;
BA_DEF_DEF_  "GenMsgILSupport" "No";
BA_DEF_DEF_  "GenMsgNrOfRepetition" 0;
BA_DEF_DEF_  "GenMsgTimeoutTime" 0;
BA_DEF_DEF_  "GenMsgSendType" "NoMsgSendType";
BA_DEF_DEF_  "NmMessage" "No";
BA_DEF_DEF_  "Type" "-";
BA_DEF_DEF_  "Period" 0;
BA_DEF_DEF_  "EventTrans" "No";
BA_DEF_DEF_  "Accuracy" "";
BA_DEF_DEF_  "SignalAge" 0;
BA_DEF_DEF_  "InitialValue" 0;
BA_DEF_DEF_  "DiagResponse" "No";
BA_DEF_DEF_  "DiagRequest" "No";
BA_DEF_DEF_  "GenMsgCycleTime" 0;
BA_ "GenMsgCycleTime" BO_ 1409 1000;
BA_ "GenMsgILSupport" BO_ 1409 1;
BA_ "GenMsgSendType" BO_ 1409 0;
BA_ "GenMsgTimeoutTime" BO_ 1409 2500;
BA_ "Period" BO_ 1409 1000;
BA_ "Type" BO_ 1409 0;
BA_ "GenMsgCycleTime" BO_ 1441 50;
BA_ "GenMsgILSupport" BO_ 1441 1;
BA_ "GenMsgSendType" BO_ 1441 0;
BA_ "GenMsgTimeoutTime" BO_ 1441 2500;
BA_ "Period" BO_ 1441 50;
BA_ "Type" BO_ 1441 1;
BA_ "GenMsgCycleTime" BO_ 1442 100;
BA_ "GenMsgILSupport" BO_ 1442 1;
BA_ "GenMsgSendType" BO_ 1442 0;
BA_ "GenMsgTimeoutTime" BO_ 1442 2500;
BA_ "Period" BO_ 1442 100;
BA_ "Type" BO_ 1442 1;
BA_ "GenMsgCycleTime" BO_ 1445 1000;
BA_ "GenMsgILSupport" BO_ 1445 1;
BA_ "GenMsgTimeoutTime" BO_ 1445 2500;
BA_ "Period" BO_ 1445 1000;
BA_ "Type" BO_ 1445 11;
BA_ "GenMsgCycleTime" BO_ 1459 1000;
BA_ "GenMsgILSupport" BO_ 1459 1;
BA_ "GenMsgSendType" BO_ 1459 0;
BA_ "GenMsgTimeoutTime" BO_ 1459 2500;
BA_ "Period" BO_ 1459 1000;
BA_ "Type" BO_ 1459 3;
BA_ "GenMsgCycleTime" BO_ 1486 500;
BA_ "GenMsgILSupport" BO_ 1486 1;
BA_ "GenMsgSendType" BO_ 1486 0;
BA_ "GenMsgTimeoutTime" BO_ 1486 2500;
BA_ "Period" BO_ 1486 500;
BA_ "Type" BO_ 1486 1;
BA_ "GenMsgCycleTime" BO_ 1504 100;
BA_ "GenMsgDelayTime" BO_ 1504 10;
BA_ "GenMsgILSupport" BO_ 1504 1;
BA_ "GenMsgSendType" BO_ 1504 0;
BA_ "GenMsgStartDelayTime" BO_ 1504 10;
BA_ "GenMsgTimeoutTime" BO_ 1504 2500;
BA_ "Period" BO_ 1504 100;
BA_ "Type" BO_ 1504 1;
BA_ "GenMsgCycleTime" BO_ 1628 250;
BA_ "GenMsgILSupport" BO_ 1628 1;
BA_ "GenMsgSendType" BO_ 1628 0;
BA_ "GenMsgTimeoutTime" BO_ 1628 2500;
BA_ "Period" BO_ 1628 250;
BA_ "Type" BO_ 1628 1;
BA_ "GenMsgCycleTime" BO_ 1668 250;
BA_ "GenMsgILSupport" BO_ 1668 1;
BA_ "GenMsgSendType" BO_ 1668 0;
BA_ "GenMsgTimeoutTime" BO_ 1668 2500;
BA_ "Period" BO_ 1668 250;
BA_ "Type" BO_ 1668 1;
BA_ "GenMsgCycleTime" BO_ 1696 1000;
BA_ "GenMsgDelayTime" BO_ 1696 10;
BA_ "GenMsgILSupport" BO_ 1696 1;
BA_ "GenMsgSendType" BO_ 1696 0;
BA_ "GenMsgTimeoutTime" BO_ 1696 2500;
BA_ "Period" BO_ 1696 1000;
BA_ "Type" BO_ 1696 3;
BA_ "GenMsgCycleTime" BO_ 1727 250;
BA_ "GenMsgILSupport" BO_ 1727 1;
BA_ "GenMsgSendType" BO_ 1727 0;
BA_ "GenMsgTimeoutTime" BO_ 1727 2500;
BA_ "Period" BO_ 1727 250;
BA_ "Type" BO_ 1727 1;
BA_ "GenMsgCycleTime" BO_ 1728 1000;
BA_ "GenMsgILSupport" BO_ 1728 1;
BA_ "GenMsgSendType" BO_ 1728 0;
BA_ "GenMsgTimeoutTime" BO_ 1728 2500;
BA_ "Period" BO_ 1728 1000;
BA_ "Type" BO_ 1728 1;
BA_ "GenMsgCycleTime" BO_ 1730 250;
BA_ "GenMsgILSupport" BO_ 1730 1;
BA_ "GenMsgSendType" BO_ 1730 0;
BA_ "GenMsgTimeoutTime" BO_ 1730 2500;
BA_ "Period" BO_ 1730 250;
BA_ "Type" BO_ 1730 1;
BA_ "GenMsgCycleTime" BO_ 1731 1000;
BA_ "GenMsgILSupport" BO_ 1731 1;
BA_ "GenMsgSendType" BO_ 1731 0;
BA_ "GenMsgTimeoutTime" BO_ 1731 2500;
BA_ "Period" BO_ 1731 1000;
BA_ "Type" BO_ 1731 0;
BA_ "GenMsgCycleTime" BO_ 1732 250;
BA_ "GenMsgILSupport" BO_ 1732 1;
BA_ "GenMsgSendType" BO_ 1732 0;
BA_ "GenMsgTimeoutTime" BO_ 1732 2500;
BA_ "Period" BO_ 1732 250;
BA_ "Type" BO_ 1732 1;
BA_ "GenMsgCycleTime" BO_ 1734 250;
BA_ "GenMsgILSupport" BO_ 1734 1;
BA_ "GenMsgSendType" BO_ 1734 0;
BA_ "GenMsgTimeoutTime" BO_ 1734 2500;
BA_ "Period" BO_ 1734 250;
BA_ "Type" BO_ 1734 1;
BA_ "GenMsgCycleTime" BO_ 1742 250;
BA_ "GenMsgILSupport" BO_ 1742 1;
BA_ "GenMsgSendType" BO_ 1742 0;
BA_ "GenMsgTimeoutTime" BO_ 1742 2500;
BA_ "Period" BO_ 1742 250;
BA_ "Type" BO_ 1742 1;
BA_ "GenMsgCycleTime" BO_ 1743 250;
BA_ "GenMsgILSupport" BO_ 1743 1;
BA_ "GenMsgSendType" BO_ 1743 0;
BA_ "GenMsgTimeoutTime" BO_ 1743 2500;
BA_ "Period" BO_ 1743 250;
BA_ "Type" BO_ 1743 1;
BA_ "GenMsgCycleTime" BO_ 1744 1000;
BA_ "GenMsgILSupport" BO_ 1744 1;
BA_ "GenMsgSendType" BO_ 1744 0;
BA_ "GenMsgStartDelayTime" BO_ 1744 10;
BA_ "GenMsgTimeoutTime" BO_ 1744 2500;
BA_ "Period" BO_ 1744 1000;
BA_ "Type" BO_ 1744 3;
BA_ "GenMsgCycleTime" BO_ 1745 250;
BA_ "GenMsgILSupport" BO_ 1745 1;
BA_ "GenMsgSendType" BO_ 1745 0;
BA_ "GenMsgTimeoutTime" BO_ 1745 2500;
BA_ "Period" BO_ 1745 250;
BA_ "Type" BO_ 1745 1;
BA_ "GenMsgCycleTime" BO_ 1746 250;
BA_ "GenMsgILSupport" BO_ 1746 1;
BA_ "GenMsgSendType" BO_ 1746 0;
BA_ "GenMsgTimeoutTime" BO_ 1746 2500;
BA_ "Period" BO_ 1746 250;
BA_ "Type" BO_ 1746 1;
BA_ "GenMsgCycleTime" BO_ 1747 250;
BA_ "GenMsgILSupport" BO_ 1747 1;
BA_ "GenMsgSendType" BO_ 1747 0;
BA_ "GenMsgTimeoutTime" BO_ 1747 2500;
BA_ "Period" BO_ 1747 250;
BA_ "Type" BO_ 1747 1;
BA_ "GenMsgCycleTime" BO_ 1852 1000;
BA_ "GenMsgDelayTime" BO_ 1852 10;
BA_ "GenMsgILSupport" BO_ 1852 1;
BA_ "GenMsgSendType" BO_ 1852 0;
BA_ "GenMsgTimeoutTime" BO_ 1852 2500;
BA_ "Period" BO_ 1852 1000;
BA_ "Type" BO_ 1852 3;
BA_ "GenMsgCycleTime" BO_ 1853 100;
BA_ "GenMsgDelayTime" BO_ 1853 10;
BA_ "GenMsgILSupport" BO_ 1853 1;
BA_ "GenMsgSendType" BO_ 1853 0;
BA_ "GenMsgTimeoutTime" BO_ 1853 2500;
BA_ "Period" BO_ 1853 100;
BA_ "Type" BO_ 1853 1;
BA_ "GenMsgCycleTime" BO_ 1904 250;
BA_ "GenMsgILSupport" BO_ 1904 1;
BA_ "GenMsgSendType" BO_ 1904 0;
BA_ "GenMsgTimeoutTime" BO_ 1904 2500;
BA_ "Period" BO_ 1904 250;
BA_ "Type" BO_ 1904 0;
BA_ "GenMsgCycleTime" BO_ 1905 250;
BA_ "GenMsgILSupport" BO_ 1905 1;
BA_ "GenMsgSendType" BO_ 1905 0;
BA_ "GenMsgTimeoutTime" BO_ 1905 2500;
BA_ "Period" BO_ 1905 250;
BA_ "Type" BO_ 1905 0;
BA_ "GenMsgCycleTime" BO_ 1906 250;
BA_ "GenMsgILSupport" BO_ 1906 1;
BA_ "GenMsgSendType" BO_ 1906 0;
BA_ "GenMsgTimeoutTime" BO_ 1906 2500;
BA_ "Period" BO_ 1906 250;
BA_ "Type" BO_ 1906 0;
BA_ "GenMsgCycleTime" BO_ 1907 250;
BA_ "GenMsgILSupport" BO_ 1907 1;
BA_ "GenMsgSendType" BO_ 1907 0;
BA_ "GenMsgTimeoutTime" BO_ 1907 2500;
BA_ "Period" BO_ 1907 250;
BA_ "Type" BO_ 1907 0;
BA_ "GenMsgCycleTime" BO_ 1908 250;
BA_ "GenMsgILSupport" BO_ 1908 1;
BA_ "GenMsgSendType" BO_ 1908 0;
BA_ "GenMsgTimeoutTime" BO_ 1908 2500;
BA_ "Period" BO_ 1908 250;
BA_ "Type" BO_ 1908 0;
BA_ "GenMsgCycleTime" BO_ 1909 250;
BA_ "GenMsgILSupport" BO_ 1909 1;
BA_ "GenMsgSendType" BO_ 1909 0;
BA_ "GenMsgTimeoutTime" BO_ 1909 2500;
BA_ "Period" BO_ 1909 250;
BA_ "Type" BO_ 1909 0;
BA_ "GenMsgCycleTime" BO_ 1910 250;
BA_ "GenMsgILSupport" BO_ 1910 1;
BA_ "GenMsgSendType" BO_ 1910 0;
BA_ "GenMsgTimeoutTime" BO_ 1910 2500;
BA_ "Period" BO_ 1910 250;
BA_ "Type" BO_ 1910 0;
BA_ "GenMsgCycleTime" BO_ 1911 250;
BA_ "GenMsgILSupport" BO_ 1911 1;
BA_ "GenMsgSendType" BO_ 1911 0;
BA_ "GenMsgTimeoutTime" BO_ 1911 2500;
BA_ "Period" BO_ 1911 250;
BA_ "Type" BO_ 1911 0;
BA_ "GenMsgCycleTime" BO_ 1912 250;
BA_ "GenMsgILSupport" BO_ 1912 1;
BA_ "GenMsgSendType" BO_ 1912 0;
BA_ "GenMsgTimeoutTime" BO_ 1912 2500;
BA_ "Period" BO_ 1912 250;
BA_ "Type" BO_ 1912 0;
BA_ "GenMsgCycleTime" BO_ 1913 250;
BA_ "GenMsgILSupport" BO_ 1913 1;
BA_ "GenMsgSendType" BO_ 1913 0;
BA_ "GenMsgTimeoutTime" BO_ 1913 2500;
BA_ "Period" BO_ 1913 250;
BA_ "Type" BO_ 1913 0;
BA_ "GenMsgCycleTime" BO_ 1914 250;
BA_ "GenMsgILSupport" BO_ 1914 1;
BA_ "GenMsgSendType" BO_ 1914 0;
BA_ "GenMsgTimeoutTime" BO_ 1914 2500;
BA_ "Period" BO_ 1914 250;
BA_ "Type" BO_ 1914 0;
BA_ "GenMsgCycleTime" BO_ 1915 250;
BA_ "GenMsgILSupport" BO_ 1915 1;
BA_ "GenMsgSendType" BO_ 1915 0;
BA_ "GenMsgTimeoutTime" BO_ 1915 2500;
BA_ "Period" BO_ 1915 250;
BA_ "Type" BO_ 1915 0;
BA_ "GenMsgCycleTime" BO_ 1916 250;
BA_ "GenMsgILSupport" BO_ 1916 1;
BA_ "GenMsgSendType" BO_ 1916 0;
BA_ "GenMsgTimeoutTime" BO_ 1916 2500;
BA_ "Period" BO_ 1916 250;
BA_ "Type" BO_ 1916 0;
BA_ "GenMsgCycleTime" BO_ 1917 250;
BA_ "GenMsgILSupport" BO_ 1917 1;
BA_ "GenMsgSendType" BO_ 1917 0;
BA_ "GenMsgTimeoutTime" BO_ 1917 2500;
BA_ "Period" BO_ 1917 250;
BA_ "Type" BO_ 1917 0;
BA_ "GenMsgCycleTime" BO_ 1955 250;
BA_ "GenMsgILSupport" BO_ 1955 1;
BA_ "GenMsgSendType" BO_ 1955 0;
BA_ "GenMsgTimeoutTime" BO_ 1955 2500;
BA_ "Period" BO_ 1955 250;
BA_ "Type" BO_ 1955 3;
BA_ "GenMsgCycleTime" BO_ 2443860262 100;
BA_ "GenMsgILSupport" BO_ 2443860262 1;
BA_ "GenMsgSendType" BO_ 2443860262 0;
BA_ "GenMsgTimeoutTime" BO_ 2443860262 2500;
BA_ "Period" BO_ 2443860262 100;
BA_ "Type" BO_ 2443860262 1;
BA_ "DiagRequest" BO_ 2443869696 1;
BA_ "DiagState" BO_ 2443869696 1;
BA_ "Type" BO_ 2443869696 8;
BA_ "GenMsgCycleTime" BO_ 2510974976 200;
BA_ "GenMsgILSupport" BO_ 2510974976 1;
BA_ "GenMsgSendType" BO_ 2510974976 0;
BA_ "GenMsgTimeoutTime" BO_ 2510974976 2500;
BA_ "Period" BO_ 2510974976 200;
BA_ "Type" BO_ 2510974976 1;
BA_ "GenMsgCycleTime" BO_ 2510974977 200;
BA_ "GenMsgILSupport" BO_ 2510974977 1;
BA_ "GenMsgSendType" BO_ 2510974977 0;
BA_ "GenMsgTimeoutTime" BO_ 2510974977 2500;
BA_ "Period" BO_ 2510974977 200;
BA_ "Type" BO_ 2510974977 1;
BA_ "GenMsgCycleTime" BO_ 2510974978 200;
BA_ "GenMsgILSupport" BO_ 2510974978 1;
BA_ "GenMsgSendType" BO_ 2510974978 0;
BA_ "GenMsgTimeoutTime" BO_ 2510974978 2500;
BA_ "Period" BO_ 2510974978 200;
BA_ "Type" BO_ 2510974978 1;
BA_ "GenMsgCycleTime" BO_ 2510974979 200;
BA_ "GenMsgILSupport" BO_ 2510974979 1;
BA_ "GenMsgSendType" BO_ 2510974979 0;
BA_ "GenMsgTimeoutTime" BO_ 2510974979 2500;
BA_ "Period" BO_ 2510974979 200;
BA_ "Type" BO_ 2510974979 1;
BA_ "DiagRequest" BO_ 2564440305 1;
BA_ "Type" BO_ 2564440305 8;
BA_ "DiagRequest" BO_ 2564443633 1;
BA_ "Type" BO_ 2564443633 8;
BA_ "DiagRequest" BO_ 2564452593 1;
BA_ "Type" BO_ 2564452593 8;
BA_ "DiagRequest" BO_ 2564452849 1;
BA_ "Type" BO_ 2564452849 8;
BA_ "DiagRequest" BO_ 2564460785 1;
BA_ "Type" BO_ 2564460785 8;
BA_ "DiagRequest" BO_ 2564473073 1;
BA_ "Type" BO_ 2564473073 8;
BA_ "DiagRequest" BO_ 2564478449 1;
BA_ "Type" BO_ 2564478449 8;
BA_ "DiagResponse" BO_ 2564485440 1;
BA_ "Type" BO_ 2564485440 8;
BA_ "DiagResponse" BO_ 2564485453 1;
BA_ "Type" BO_ 2564485453 8;
BA_ "DiagResponse" BO_ 2564485488 1;
BA_ "Type" BO_ 2564485488 8;
BA_ "DiagResponse" BO_ 2564485489 1;
BA_ "Type" BO_ 2564485489 8;
BA_ "DiagResponse" BO_ 2564485520 1;
BA_ "Type" BO_ 2564485520 8;
BA_ "DiagResponse" BO_ 2564485568 1;
BA_ "Type" BO_ 2564485568 8;
BA_ "DiagResponse" BO_ 2564485589 1;
BA_ "Type" BO_ 2564485589 8;
BA_ "DiagState" BO_ 2564554481 1;
BA_ "Type" BO_ 2564554481 8;
BA_ "DiagRequest" BO_ 2564554737 1;
BA_ "Type" BO_ 2564554737 8;
BA_ "GenMsgILSupport" BO_ 2651930624 1;
BA_ "GenMsgTimeoutTime" BO_ 2651930624 1000;
BA_ "Type" BO_ 2651930624 8;
BA_ "GenMsgILSupport" BO_ 2651930626 1;
BA_ "GenMsgTimeoutTime" BO_ 2651930626 1000;
BA_ "Type" BO_ 2651930626 8;
BA_ "GenMsgILSupport" BO_ 2651930630 1;
BA_ "GenMsgTimeoutTime" BO_ 2651930630 1000;
BA_ "Type" BO_ 2651930630 8;
BA_ "GenMsgILSupport" BO_ 2651930638 1;
BA_ "GenMsgTimeoutTime" BO_ 2651930638 1000;
BA_ "Type" BO_ 2651930638 8;
BA_ "GenMsgILSupport" BO_ 2651930650 1;
BA_ "GenMsgTimeoutTime" BO_ 2651930650 1000;
BA_ "Type" BO_ 2651930650 8;
BA_ "GenMsgILSupport" BO_ 2651930654 1;
BA_ "GenMsgTimeoutTime" BO_ 2651930654 1000;
BA_ "Type" BO_ 2651930654 8;
BA_ "GenMsgILSupport" BO_ 2651930672 1;
BA_ "GenMsgTimeoutTime" BO_ 2651930672 1000;
BA_ "Type" BO_ 2651930672 8;
BA_ "GenMsgILSupport" BO_ 2651930673 1;
BA_ "GenMsgTimeoutTime" BO_ 2651930673 1000;
BA_ "Type" BO_ 2651930673 8;
BA_ "GenMsgILSupport" BO_ 2651930674 1;
BA_ "GenMsgTimeoutTime" BO_ 2651930674 1000;
BA_ "Type" BO_ 2651930674 8;
BA_ "GenMsgILSupport" BO_ 2651930681 1;
BA_ "GenMsgTimeoutTime" BO_ 2651930681 1000;
BA_ "Type" BO_ 2651930681 8;
BA_ "GenMsgILSupport" BO_ 2651930714 1;
BA_ "GenMsgTimeoutTime" BO_ 2651930714 1000;
BA_ "Type" BO_ 2651930714 8;
BA_ "GenMsgILSupport" BO_ 2651930736 1;
BA_ "GenMsgTimeoutTime" BO_ 2651930736 1000;
BA_ "Type" BO_ 2651930736 8;
BA_ "GenMsgILSupport" BO_ 2651930739 1;
BA_ "GenMsgTimeoutTime" BO_ 2651930739 1000;
BA_ "Type" BO_ 2651930739 8;
BA_ "GenMsgILSupport" BO_ 2651930748 1;
BA_ "GenMsgTimeoutTime" BO_ 2651930748 1000;
BA_ "Type" BO_ 2651930748 8;
BA_ "GenMsgCycleTime" BO_ 2654208000 200;
BA_ "GenMsgILSupport" BO_ 2654208000 1;
BA_ "GenMsgSendType" BO_ 2654208000 0;
BA_ "GenMsgStartDelayTime" BO_ 2654208000 10;
BA_ "GenMsgTimeoutTime" BO_ 2654208000 2500;
BA_ "NmMessage" BO_ 2654208000 1;
BA_ "Period" BO_ 2654208000 200;
BA_ "Type" BO_ 2654208000 3;
BA_ "GenMsgILSupport" BO_ 2654208001 1;
BA_ "GenMsgStartDelayTime" BO_ 2654208001 10;
BA_ "NmMessage" BO_ 2654208001 1;
BA_ "Type" BO_ 2654208001 8;
BA_ "GenMsgILSupport" BO_ 2654208006 1;
BA_ "GenMsgStartDelayTime" BO_ 2654208006 10;
BA_ "NmMessage" BO_ 2654208006 1;
BA_ "Type" BO_ 2654208006 8;
BA_ "GenMsgILSupport" BO_ 2654208014 1;
BA_ "GenMsgStartDelayTime" BO_ 2654208014 10;
BA_ "NmMessage" BO_ 2654208014 1;
BA_ "Type" BO_ 2654208014 8;
BA_ "NmMessage" BO_ 2654208026 1;
BA_ "GenMsgILSupport" BO_ 2654208026 1;
BA_ "GenMsgStartDelayTime" BO_ 2654208026 10;
BA_ "Type" BO_ 2654208026 8;
BA_ "GenMsgILSupport" BO_ 2654208028 1;
BA_ "GenMsgStartDelayTime" BO_ 2654208028 10;
BA_ "NmMessage" BO_ 2654208028 1;
BA_ "Type" BO_ 2654208028 8;
BA_ "GenMsgILSupport" BO_ 2654208048 1;
BA_ "GenMsgStartDelayTime" BO_ 2654208048 10;
BA_ "NmMessage" BO_ 2654208048 1;
BA_ "Type" BO_ 2654208048 8;
BA_ "GenMsgILSupport" BO_ 2654208049 1;
BA_ "GenMsgStartDelayTime" BO_ 2654208049 10;
BA_ "NmMessage" BO_ 2654208049 1;
BA_ "Type" BO_ 2654208049 8;
BA_ "GenMsgILSupport" BO_ 2654208050 1;
BA_ "GenMsgStartDelayTime" BO_ 2654208050 10;
BA_ "NmMessage" BO_ 2654208050 1;
BA_ "Type" BO_ 2654208050 8;
BA_ "NmMessage" BO_ 2654208089 1;
BA_ "GenMsgILSupport" BO_ 2654208089 1;
BA_ "GenMsgStartDelayTime" BO_ 2654208089 10;
BA_ "Type" BO_ 2654208089 8;
BA_ "GenMsgILSupport" BO_ 2654208090 1;
BA_ "GenMsgStartDelayTime" BO_ 2654208090 10;
BA_ "GenMsgTimeoutTime" BO_ 2654208090 2500;
BA_ "NmMessage" BO_ 2654208090 1;
BA_ "Type" BO_ 2654208090 8;
BA_ "NmMessage" BO_ 2654208112 1;
BA_ "GenMsgILSupport" BO_ 2654208125 1;
BA_ "GenMsgStartDelayTime" BO_ 2654208125 10;
BA_ "NmMessage" BO_ 2654208125 1;
BA_ "Type" BO_ 2654208125 8;
BA_ "GenMsgCycleTime" BO_ 2654339074 100;
BA_ "GenMsgILSupport" BO_ 2654339074 1;
BA_ "GenMsgSendType" BO_ 2654339074 0;
BA_ "GenMsgTimeoutTime" BO_ 2654339074 2500;
BA_ "Period" BO_ 2654339074 100;
BA_ "Type" BO_ 2654339074 3;
BA_ "GenMsgCycleTime" BO_ 2654339092 1000;
BA_ "GenMsgDelayTime" BO_ 2654339092 10;
BA_ "GenMsgILSupport" BO_ 2654339092 1;
BA_ "GenMsgSendType" BO_ 2654339092 0;
BA_ "GenMsgTimeoutTime" BO_ 2654339092 2500;
BA_ "Period" BO_ 2654339092 1000;
BA_ "Type" BO_ 2654339092 1;
BA_ "GenMsgCycleTime" BO_ 2654339098 1000;
BA_ "GenMsgILSupport" BO_ 2654339098 1;
BA_ "GenMsgSendType" BO_ 2654339098 0;
BA_ "GenMsgTimeoutTime" BO_ 2654339098 2500;
BA_ "Period" BO_ 2654339098 1000;
BA_ "Type" BO_ 2654339098 1;
BA_ "GenMsgCycleTime" BO_ 2654339100 1000;
BA_ "GenMsgDelayTime" BO_ 2654339100 10;
BA_ "GenMsgILSupport" BO_ 2654339100 1;
BA_ "GenMsgSendType" BO_ 2654339100 0;
BA_ "GenMsgTimeoutTime" BO_ 2654339100 2500;
BA_ "Period" BO_ 2654339100 1000;
BA_ "Type" BO_ 2654339100 1;
BA_ "GenMsgCycleTime" BO_ 2654339102 1000;
BA_ "GenMsgDelayTime" BO_ 2654339102 10;
BA_ "GenMsgILSupport" BO_ 2654339102 1;
BA_ "GenMsgSendType" BO_ 2654339102 0;
BA_ "GenMsgTimeoutTime" BO_ 2654339102 2500;
BA_ "Period" BO_ 2654339102 1000;
BA_ "Type" BO_ 2654339102 1;
BA_ "GenMsgCycleTime" BO_ 2654339120 1000;
BA_ "GenMsgDelayTime" BO_ 2654339120 10;
BA_ "GenMsgILSupport" BO_ 2654339120 1;
BA_ "GenMsgSendType" BO_ 2654339120 0;
BA_ "GenMsgTimeoutTime" BO_ 2654339120 2500;
BA_ "Period" BO_ 2654339120 1000;
BA_ "Type" BO_ 2654339120 1;
BA_ "GenMsgCycleTime" BO_ 2654339121 1000;
BA_ "GenMsgDelayTime" BO_ 2654339121 10;
BA_ "GenMsgILSupport" BO_ 2654339121 1;
BA_ "GenMsgSendType" BO_ 2654339121 0;
BA_ "GenMsgTimeoutTime" BO_ 2654339121 2500;
BA_ "Period" BO_ 2654339121 1000;
BA_ "Type" BO_ 2654339121 1;
BA_ "GenMsgCycleTime" BO_ 2654339122 1000;
BA_ "GenMsgDelayTime" BO_ 2654339122 10;
BA_ "GenMsgILSupport" BO_ 2654339122 1;
BA_ "GenMsgSendType" BO_ 2654339122 0;
BA_ "GenMsgTimeoutTime" BO_ 2654339122 2500;
BA_ "Period" BO_ 2654339122 1000;
BA_ "Type" BO_ 2654339122 1;
BA_ "GenMsgCycleTime" BO_ 2654339129 1000;
BA_ "GenMsgDelayTime" BO_ 2654339129 10;
BA_ "GenMsgILSupport" BO_ 2654339129 1;
BA_ "GenMsgSendType" BO_ 2654339129 0;
BA_ "GenMsgTimeoutTime" BO_ 2654339129 2500;
BA_ "Period" BO_ 2654339129 1000;
BA_ "Type" BO_ 2654339129 1;
BA_ "GenMsgCycleTime" BO_ 2654339149 100;
BA_ "GenMsgILSupport" BO_ 2654339149 1;
BA_ "GenMsgSendType" BO_ 2654339149 0;
BA_ "GenMsgTimeoutTime" BO_ 2654339149 2500;
BA_ "Period" BO_ 2654339149 100;
BA_ "Type" BO_ 2654339149 1;
BA_ "GenMsgCycleTime" BO_ 2654339160 1000;
BA_ "GenMsgDelayTime" BO_ 2654339160 10;
BA_ "GenMsgILSupport" BO_ 2654339160 1;
BA_ "GenMsgSendType" BO_ 2654339160 0;
BA_ "GenMsgTimeoutTime" BO_ 2654339160 2500;
BA_ "Period" BO_ 2654339160 1000;
BA_ "Type" BO_ 2654339160 1;
BA_ "GenMsgCycleTime" BO_ 2654339161 100;
BA_ "GenMsgILSupport" BO_ 2654339161 1;
BA_ "GenMsgSendType" BO_ 2654339161 0;
BA_ "Period" BO_ 2654339161 100;
BA_ "Type" BO_ 2654339161 1;
BA_ "GenMsgCycleTime" BO_ 2654339184 1000;
BA_ "GenMsgILSupport" BO_ 2654339184 1;
BA_ "GenMsgSendType" BO_ 2654339184 0;
BA_ "GenMsgTimeoutTime" BO_ 2654339184 2500;
BA_ "Period" BO_ 2654339184 1000;
BA_ "Type" BO_ 2654339184 1;
BA_ "GenMsgCycleTime" BO_ 2654339187 100;
BA_ "GenMsgDelayTime" BO_ 2654339187 10;
BA_ "GenMsgILSupport" BO_ 2654339187 1;
BA_ "GenMsgSendType" BO_ 2654339187 0;
BA_ "GenMsgTimeoutTime" BO_ 2654339187 2500;
BA_ "Period" BO_ 2654339187 100;
BA_ "Type" BO_ 2654339187 3;
BA_ "GenMsgCycleTime" BO_ 2654339196 100;
BA_ "GenMsgDelayTime" BO_ 2654339196 10;
BA_ "GenMsgILSupport" BO_ 2654339196 1;
BA_ "GenMsgSendType" BO_ 2654339196 0;
BA_ "Period" BO_ 2654339196 100;
BA_ "Type" BO_ 2654339196 3;
BA_ "GenMsgCycleTime" BO_ 2654339197 1000;
BA_ "GenMsgILSupport" BO_ 2654339197 1;
BA_ "GenMsgSendType" BO_ 2654339197 0;
BA_ "GenMsgTimeoutTime" BO_ 2654339197 2500;
BA_ "Period" BO_ 2654339197 1000;
BA_ "Type" BO_ 2654339197 1;
BA_ "Accuracy" SG_ 1409 CalculatedLoadValue "+/-0,392%";
BA_ "SignalAge" SG_ 1409 CalculatedLoadValue 100;
BA_ "Accuracy" SG_ 1409 EngineCoolantTemperature "+/-2°C";
BA_ "InitialValue" SG_ 1409 EngineCoolantTemperature -40;
BA_ "SignalAge" SG_ 1409 EngineCoolantTemperature 100;
BA_ "Accuracy" SG_ 1409 AbsoluteThrottlePosition "+/-0,392%";
BA_ "SignalAge" SG_ 1409 AbsoluteThrottlePosition 100;
BA_ "Accuracy" SG_ 1409 AbsoluteLoad "+/-0,392%";
BA_ "SignalAge" SG_ 1409 AbsoluteLoad 100;
BA_ "Accuracy" SG_ 1409 AbsolutePedalPosition "0,392%";
BA_ "SignalAge" SG_ 1409 AbsolutePedalPosition 100;
BA_ "Accuracy" SG_ 1409 TimeSinceEngineStart "1 sec.";
BA_ "Accuracy" SG_ 1441 EngineOilTemperature "0";
BA_ "InitialValue" SG_ 1441 EngineOilTemperature -48;
BA_ "Accuracy" SG_ 1441 BatteryVoltageLevel "±0,05V";
BA_ "SignalAge" SG_ 1441 BatteryVoltageLevel 1000;
BA_ "GenSigStartValue" SG_ 1441 RechargeSts 1;
BA_ "InitialValue" SG_ 1441 RechargeSts 1;
BA_ "InitialValue" SG_ 1442 Oil_Quality_Estimation -1;
BA_ "Accuracy" SG_ 1442 EngineOilPressure "± 0,2 bar";
BA_ "SignalAge" SG_ 1442 EngineOilPressure 250;
BA_ "GenSigStartValue" SG_ 1486 LongParkingSts 1;
BA_ "InitialValue" SG_ 1486 LongParkingSts 1;
BA_ "GenSigStartValue" SG_ 1486 RechargeSts 1;
BA_ "InitialValue" SG_ 1486 RechargeSts 1;
BA_ "InitialValue" SG_ 1486 InstantPower -256;
BA_ "EventTrans" SG_ 1504 FuelFlapSts 0;
BA_ "GenSigSendType" SG_ 1504 FuelFlapSts 3;
BA_ "EventTrans" SG_ 1504 LowBeamSts 0;
BA_ "GenSigSendType" SG_ 1504 LowBeamSts 3;
BA_ "EventTrans" SG_ 1504 CapoteSts 0;
BA_ "GenSigSendType" SG_ 1504 CapoteSts 3;
BA_ "Accuracy" SG_ 1504 EngineOilTemperature "± 1 °C";
BA_ "InitialValue" SG_ 1504 EngineOilTemperature -48;
BA_ "SignalAge" SG_ 1504 EngineOilTemperature 250;
BA_ "EventTrans" SG_ 1504 FoldMirrorSts 0;
BA_ "GenSigSendType" SG_ 1504 FoldMirrorSts 3;
BA_ "GenSigStartValue" SG_ 1504 WalkAwayEnabled 1;
BA_ "InitialValue" SG_ 1504 WalkAwayEnabled 1;
BA_ "Accuracy" SG_ 1504 EngineOilPressure "± 0.2 bar";
BA_ "Accuracy" SG_ 1504 TotalOdometer "N/A";
BA_ "SignalAge" SG_ 1504 TotalOdometer 1000;
BA_ "GenSigStartValue" SG_ 1504 NightDaySts 1;
BA_ "InitialValue" SG_ 1504 NightDaySts 1;
BA_ "GenSigStartValue" SG_ 1504 LongParkingSetting 3;
BA_ "InitialValue" SG_ 1504 LongParkingSetting 3;
BA_ "GenSigStartValue" SG_ 1504 AVHDriverDoorSts 1;
BA_ "InitialValue" SG_ 1504 AVHDriverDoorSts 1;
BA_ "GenSigStartValue" SG_ 1504 Alcohol_Interlock_Inhibit 1;
BA_ "InitialValue" SG_ 1504 Alcohol_Interlock_Inhibit 1;
BA_ "EventTrans" SG_ 1504 InternalLightSts 0;
BA_ "GenSigSendType" SG_ 1504 InternalLightSts 3;
BA_ "EventTrans" SG_ 1696 Hour2 0;
BA_ "GenSigSendType" SG_ 1696 Hour2 3;
BA_ "EventTrans" SG_ 1696 Hour1 0;
BA_ "GenSigSendType" SG_ 1696 Hour1 3;
BA_ "EventTrans" SG_ 1696 Minute2 0;
BA_ "GenSigSendType" SG_ 1696 Minute2 3;
BA_ "EventTrans" SG_ 1696 Minute1 0;
BA_ "GenSigSendType" SG_ 1696 Minute1 3;
BA_ "EventTrans" SG_ 1696 Day2 0;
BA_ "GenSigSendType" SG_ 1696 Day2 3;
BA_ "EventTrans" SG_ 1696 Day1 0;
BA_ "GenSigSendType" SG_ 1696 Day1 3;
BA_ "EventTrans" SG_ 1696 Month2 0;
BA_ "GenSigSendType" SG_ 1696 Month2 3;
BA_ "EventTrans" SG_ 1696 Month1 0;
BA_ "GenSigSendType" SG_ 1696 Month1 3;
BA_ "EventTrans" SG_ 1696 Year2 0;
BA_ "GenSigSendType" SG_ 1696 Year2 3;
BA_ "EventTrans" SG_ 1696 Year1 0;
BA_ "GenSigSendType" SG_ 1696 Year1 3;
BA_ "EventTrans" SG_ 1696 Year4 0;
BA_ "GenSigSendType" SG_ 1696 Year4 3;
BA_ "EventTrans" SG_ 1696 Year3 0;
BA_ "GenSigSendType" SG_ 1696 Year3 3;
BA_ "Accuracy" SG_ 1728 RearWheelCircumference "N/A";
BA_ "InitialValue" SG_ 1728 RearWheelCircumference 1440;
BA_ "InitialValue" SG_ 1728 NotInUseMonitoringTimer 10;
BA_ "Accuracy" SG_ 1731 TempExtFrontRight "2°C";
BA_ "InitialValue" SG_ 1731 TempExtFrontRight -40;
BA_ "SignalAge" SG_ 1731 TempExtFrontRight 1000;
BA_ "Accuracy" SG_ 1731 TempExtFrontLeft "2°C";
BA_ "InitialValue" SG_ 1731 TempExtFrontLeft -40;
BA_ "SignalAge" SG_ 1731 TempExtFrontLeft 1000;
BA_ "Accuracy" SG_ 1731 TempExtRearRight "2°C";
BA_ "InitialValue" SG_ 1731 TempExtRearRight -40;
BA_ "SignalAge" SG_ 1731 TempExtRearRight 1000;
BA_ "Accuracy" SG_ 1731 TempExtRearLeft "2°C";
BA_ "InitialValue" SG_ 1731 TempExtRearLeft -40;
BA_ "SignalAge" SG_ 1731 TempExtRearLeft 1000;
BA_ "Accuracy" SG_ 1731 TempIntFrontRight "2°C";
BA_ "InitialValue" SG_ 1731 TempIntFrontRight -40;
BA_ "SignalAge" SG_ 1731 TempIntFrontRight 1000;
BA_ "Accuracy" SG_ 1731 TempIntFrontLeft "2°C";
BA_ "InitialValue" SG_ 1731 TempIntFrontLeft -40;
BA_ "SignalAge" SG_ 1731 TempIntFrontLeft 1000;
BA_ "Accuracy" SG_ 1731 TempIntRearRight "2°C";
BA_ "InitialValue" SG_ 1731 TempIntRearRight -40;
BA_ "SignalAge" SG_ 1731 TempIntRearRight 1000;
BA_ "Accuracy" SG_ 1731 TempIntRearLeft "2°C";
BA_ "InitialValue" SG_ 1731 TempIntRearLeft -40;
BA_ "SignalAge" SG_ 1731 TempIntRearLeft 1000;
BA_ "EventTrans" SG_ 1744 TSAMainSign2Enable 0;
BA_ "GenSigSendType" SG_ 1744 TSAMainSign2Enable 3;
BA_ "EventTrans" SG_ 1744 TSASignChangeEnable 0;
BA_ "GenSigSendType" SG_ 1744 TSASignChangeEnable 3;
BA_ "EventTrans" SG_ 1744 TSAEnable 0;
BA_ "GenSigSendType" SG_ 1744 TSAEnable 3;
BA_ "EventTrans" SG_ 1744 DMS_Enable 0;
BA_ "GenSigSendType" SG_ 1744 DMS_Enable 3;
BA_ "EventTrans" SG_ 1852 ACC_Dist_fbk 0;
BA_ "GenSigSendType" SG_ 1852 ACC_Dist_fbk 3;
BA_ "GenSigStartValue" SG_ 1852 ACC_Dist_fbk 5;
BA_ "InitialValue" SG_ 1852 ACC_Dist_fbk 5;
BA_ "EventTrans" SG_ 1852 ACCFailReversibleSts 0;
BA_ "GenSigSendType" SG_ 1852 ACCFailReversibleSts 3;
BA_ "EventTrans" SG_ 1852 DASMTemporaryFailSts 0;
BA_ "GenSigSendType" SG_ 1852 DASMTemporaryFailSts 3;
BA_ "GenSigStartValue" SG_ 1852 DASMTemporaryFailSts 1;
BA_ "InitialValue" SG_ 1852 DASMTemporaryFailSts 1;
BA_ "EventTrans" SG_ 1852 DASMFailSts 0;
BA_ "GenSigSendType" SG_ 1852 DASMFailSts 3;
BA_ "GenSigStartValue" SG_ 1852 DASMFailSts 1;
BA_ "InitialValue" SG_ 1852 DASMFailSts 1;
BA_ "EventTrans" SG_ 1852 RadarBlinded 0;
BA_ "GenSigSendType" SG_ 1852 RadarBlinded 3;
BA_ "GenSigStartValue" SG_ 1852 RadarBlinded 1;
BA_ "InitialValue" SG_ 1852 RadarBlinded 1;
BA_ "EventTrans" SG_ 1852 FCWSystemSts 0;
BA_ "GenSigSendType" SG_ 1852 FCWSystemSts 3;
BA_ "GenSigStartValue" SG_ 1852 FCWSystemSts 3;
BA_ "InitialValue" SG_ 1852 FCWSystemSts 3;
BA_ "EventTrans" SG_ 1852 ACC_DrivingMode_fbk 0;
BA_ "GenSigSendType" SG_ 1852 ACC_DrivingMode_fbk 3;
BA_ "EventTrans" SG_ 1852 FCWSts 0;
BA_ "GenSigSendType" SG_ 1852 FCWSts 3;
BA_ "GenSigStartValue" SG_ 1852 FCWSts 2;
BA_ "InitialValue" SG_ 1852 FCWSts 2;
BA_ "EventTrans" SG_ 1852 HMICode_FCW 0;
BA_ "GenSigSendType" SG_ 1852 HMICode_FCW 3;
BA_ "EventTrans" SG_ 1852 CameraBlinded 0;
BA_ "GenSigSendType" SG_ 1852 CameraBlinded 3;
BA_ "GenSigStartValue" SG_ 1852 CameraBlinded 1;
BA_ "InitialValue" SG_ 1852 CameraBlinded 1;
BA_ "EventTrans" SG_ 1852 CameraFailure 0;
BA_ "GenSigSendType" SG_ 1852 CameraFailure 3;
BA_ "GenSigStartValue" SG_ 1852 CameraFailure 1;
BA_ "InitialValue" SG_ 1852 CameraFailure 1;
BA_ "EventTrans" SG_ 1852 ACC_SetSpeedKPH 0;
BA_ "GenSigSendType" SG_ 1852 ACC_SetSpeedKPH 3;
BA_ "EventTrans" SG_ 1852 ACC_SetSpeedMPH 0;
BA_ "GenSigSendType" SG_ 1852 ACC_SetSpeedMPH 3;
BA_ "EventTrans" SG_ 1852 HMICode_ACC 0;
BA_ "GenSigSendType" SG_ 1852 HMICode_ACC 3;
BA_ "EventTrans" SG_ 1852 ACCFailSts 0;
BA_ "GenSigSendType" SG_ 1852 ACCFailSts 3;
BA_ "EventTrans" SG_ 1852 HMIDisplay_ACC 0;
BA_ "GenSigSendType" SG_ 1852 HMIDisplay_ACC 3;
BA_ "GenSigStartValue" SG_ 1852 FCWSensibilitySts 3;
BA_ "InitialValue" SG_ 1852 FCWSensibilitySts 3;
BA_ "EventTrans" SG_ 1852 ACC_RadarBlinded 0;
BA_ "GenSigSendType" SG_ 1852 ACC_RadarBlinded 3;
BA_ "GenSigStartValue" SG_ 1852 ACC_RadarBlinded 1;
BA_ "InitialValue" SG_ 1852 ACC_RadarBlinded 1;
BA_ "EventTrans" SG_ 1852 ACCSystemSts 0;
BA_ "GenSigSendType" SG_ 1852 ACCSystemSts 3;
BA_ "GenSigStartValue" SG_ 1853 ACC_TargetDistance 511;
BA_ "InitialValue" SG_ 1853 ACC_TargetDistance 511;
BA_ "GenSigStartValue" SG_ 1853 ACC_DesiredDistance 127;
BA_ "InitialValue" SG_ 1853 ACC_DesiredDistance 127;
BA_ "GenSigStartValue" SG_ 1853 ACC_TargetRelativeVelocity 512;
BA_ "Accuracy" SG_ 1955 EngineOilTemperature "± 1 °C";
BA_ "InitialValue" SG_ 1955 EngineOilTemperature -48;
BA_ "SignalAge" SG_ 1955 EngineOilTemperature 250;
BA_ "EventTrans" SG_ 1955 WCM_Status 0;
BA_ "GenSigSendType" SG_ 1955 WCM_Status 3;
BA_ "Accuracy" SG_ 1955 EngineOilPressure "± 0,2 bar";
BA_ "SignalAge" SG_ 1955 EngineOilPressure 250;
BA_ "EventTrans" SG_ 1955 ElectricSteeringLamp_FailSts 0;
BA_ "GenSigSendType" SG_ 1955 ElectricSteeringLamp_FailSts 3;
BA_ "InitialValue" SG_ 1955 Oil_Quality_Estimation_NQS -1;
BA_ "EventTrans" SG_ 1955 CameraButtonSts 0;
BA_ "GenSigSendType" SG_ 1955 CameraButtonSts 3;
BA_ "EventTrans" SG_ 2564440305 TPDU_DREQ_NBC 0;
BA_ "GenSigSendType" SG_ 2564440305 TPDU_DREQ_NBC 1;
BA_ "EventTrans" SG_ 2564452593 TPDU_DREQ_WLMR 0;
BA_ "GenSigSendType" SG_ 2564452593 TPDU_DREQ_WLMR 1;
BA_ "EventTrans" SG_ 2564452849 TPDU_DREQ_WLML 0;
BA_ "GenSigSendType" SG_ 2564452849 TPDU_DREQ_WLML 1;
BA_ "EventTrans" SG_ 2564460785 TPDU_DREQ_NPE 0;
BA_ "GenSigSendType" SG_ 2564460785 TPDU_DREQ_NPE 1;
BA_ "EventTrans" SG_ 2564473073 TPDU_DREQ_NAB 0;
BA_ "GenSigSendType" SG_ 2564473073 TPDU_DREQ_NAB 1;
BA_ "EventTrans" SG_ 2564478449 TPDU_DREQ_LCC 0;
BA_ "GenSigSendType" SG_ 2564478449 TPDU_DREQ_LCC 1;
BA_ "EventTrans" SG_ 2564485440 TPDU_DRES_NBC 0;
BA_ "GenSigSendType" SG_ 2564485440 TPDU_DRES_NBC 1;
BA_ "EventTrans" SG_ 2564485488 TPDU_DRES_WLMR 0;
BA_ "GenSigSendType" SG_ 2564485488 TPDU_DRES_WLMR 1;
BA_ "EventTrans" SG_ 2564485489 TPDU_DRES_WLML 0;
BA_ "GenSigSendType" SG_ 2564485489 TPDU_DRES_WLML 1;
BA_ "EventTrans" SG_ 2564485520 TPDU_DRES_NPE 0;
BA_ "GenSigSendType" SG_ 2564485520 TPDU_DRES_NPE 1;
BA_ "EventTrans" SG_ 2564485568 TPDU_DRES_NAB 0;
BA_ "GenSigSendType" SG_ 2564485568 TPDU_DRES_NAB 1;
BA_ "EventTrans" SG_ 2564485589 TPDU_DRES_LCC 0;
BA_ "GenSigSendType" SG_ 2564485589 TPDU_DRES_LCC 1;
BA_ "EventTrans" SG_ 2564554481 TPDU_UDSFUNC 0;
BA_ "GenSigSendType" SG_ 2564554481 TPDU_UDSFUNC 1;
BA_ "EventTrans" SG_ 2564554737 TPDU_EDRDATAREQ 0;
BA_ "GenSigSendType" SG_ 2564554737 TPDU_EDRDATAREQ 1;
BA_ "EventTrans" SG_ 2651930624 Digit_10 0;
BA_ "GenSigSendType" SG_ 2651930624 Digit_10 1;
BA_ "EventTrans" SG_ 2651930624 Digit_11 0;
BA_ "GenSigSendType" SG_ 2651930624 Digit_11 1;
BA_ "EventTrans" SG_ 2651930624 Digit_08 0;
BA_ "GenSigSendType" SG_ 2651930624 Digit_08 1;
BA_ "EventTrans" SG_ 2651930624 Digit_09 0;
BA_ "GenSigSendType" SG_ 2651930624 Digit_09 1;
BA_ "EventTrans" SG_ 2651930624 Digit_06 0;
BA_ "GenSigSendType" SG_ 2651930624 Digit_06 1;
BA_ "EventTrans" SG_ 2651930624 Digit_07 0;
BA_ "GenSigSendType" SG_ 2651930624 Digit_07 1;
BA_ "EventTrans" SG_ 2651930624 Digit_04 0;
BA_ "GenSigSendType" SG_ 2651930624 Digit_04 1;
BA_ "EventTrans" SG_ 2651930624 Digit_05 0;
BA_ "GenSigSendType" SG_ 2651930624 Digit_05 1;
BA_ "EventTrans" SG_ 2651930624 Digit_02 0;
BA_ "GenSigSendType" SG_ 2651930624 Digit_02 1;
BA_ "EventTrans" SG_ 2651930624 Digit_03 0;
BA_ "GenSigSendType" SG_ 2651930624 Digit_03 1;
BA_ "EventTrans" SG_ 2651930624 Digit_01 0;
BA_ "GenSigSendType" SG_ 2651930624 Digit_01 1;
BA_ "EventTrans" SG_ 2651930626 Digit_10_NGE 0;
BA_ "GenSigSendType" SG_ 2651930626 Digit_10_NGE 1;
BA_ "EventTrans" SG_ 2651930626 Digit_11_NGE 0;
BA_ "GenSigSendType" SG_ 2651930626 Digit_11_NGE 1;
BA_ "EventTrans" SG_ 2651930626 Digit_08_NGE 0;
BA_ "GenSigSendType" SG_ 2651930626 Digit_08_NGE 1;
BA_ "EventTrans" SG_ 2651930626 Digit_09_NGE 0;
BA_ "GenSigSendType" SG_ 2651930626 Digit_09_NGE 1;
BA_ "EventTrans" SG_ 2651930626 Digit_06_NGE 0;
BA_ "GenSigSendType" SG_ 2651930626 Digit_06_NGE 1;
BA_ "EventTrans" SG_ 2651930626 Digit_07_NGE 0;
BA_ "GenSigSendType" SG_ 2651930626 Digit_07_NGE 1;
BA_ "EventTrans" SG_ 2651930626 Digit_04_NGE 0;
BA_ "GenSigSendType" SG_ 2651930626 Digit_04_NGE 1;
BA_ "EventTrans" SG_ 2651930626 Digit_05_NGE 0;
BA_ "GenSigSendType" SG_ 2651930626 Digit_05_NGE 1;
BA_ "EventTrans" SG_ 2651930626 Digit_02_NGE 0;
BA_ "GenSigSendType" SG_ 2651930626 Digit_02_NGE 1;
BA_ "EventTrans" SG_ 2651930626 Digit_03_NGE 0;
BA_ "GenSigSendType" SG_ 2651930626 Digit_03_NGE 1;
BA_ "EventTrans" SG_ 2651930626 Digit_01_NGE 0;
BA_ "GenSigSendType" SG_ 2651930626 Digit_01_NGE 1;
BA_ "EventTrans" SG_ 2651930630 Digit_10_NFR 0;
BA_ "GenSigSendType" SG_ 2651930630 Digit_10_NFR 1;
BA_ "EventTrans" SG_ 2651930630 Digit_11_NFR 0;
BA_ "GenSigSendType" SG_ 2651930630 Digit_11_NFR 1;
BA_ "EventTrans" SG_ 2651930630 Digit_08_NFR 0;
BA_ "GenSigSendType" SG_ 2651930630 Digit_08_NFR 1;
BA_ "EventTrans" SG_ 2651930630 Digit_09_NFR 0;
BA_ "GenSigSendType" SG_ 2651930630 Digit_09_NFR 1;
BA_ "EventTrans" SG_ 2651930630 Digit_06_NFR 0;
BA_ "GenSigSendType" SG_ 2651930630 Digit_06_NFR 1;
BA_ "EventTrans" SG_ 2651930630 Digit_07_NFR 0;
BA_ "GenSigSendType" SG_ 2651930630 Digit_07_NFR 1;
BA_ "EventTrans" SG_ 2651930630 Digit_04_NFR 0;
BA_ "GenSigSendType" SG_ 2651930630 Digit_04_NFR 1;
BA_ "EventTrans" SG_ 2651930630 Digit_05_NFR 0;
BA_ "GenSigSendType" SG_ 2651930630 Digit_05_NFR 1;
BA_ "EventTrans" SG_ 2651930630 Digit_02_NFR 0;
BA_ "GenSigSendType" SG_ 2651930630 Digit_02_NFR 1;
BA_ "EventTrans" SG_ 2651930630 Digit_03_NFR 0;
BA_ "GenSigSendType" SG_ 2651930630 Digit_03_NFR 1;
BA_ "EventTrans" SG_ 2651930630 Digit_01_NFR 0;
BA_ "GenSigSendType" SG_ 2651930630 Digit_01_NFR 1;
BA_ "EventTrans" SG_ 2651930638 Digit_10_HVB 0;
BA_ "GenSigSendType" SG_ 2651930638 Digit_10_HVB 1;
BA_ "EventTrans" SG_ 2651930638 Digit_11_HVB 0;
BA_ "GenSigSendType" SG_ 2651930638 Digit_11_HVB 1;
BA_ "EventTrans" SG_ 2651930638 Digit_08_HVB 0;
BA_ "GenSigSendType" SG_ 2651930638 Digit_08_HVB 1;
BA_ "EventTrans" SG_ 2651930638 Digit_09_HVB 0;
BA_ "GenSigSendType" SG_ 2651930638 Digit_09_HVB 1;
BA_ "EventTrans" SG_ 2651930638 Digit_06_HVB 0;
BA_ "GenSigSendType" SG_ 2651930638 Digit_06_HVB 1;
BA_ "EventTrans" SG_ 2651930638 Digit_07_HVB 0;
BA_ "GenSigSendType" SG_ 2651930638 Digit_07_HVB 1;
BA_ "EventTrans" SG_ 2651930638 Digit_04_HVB 0;
BA_ "GenSigSendType" SG_ 2651930638 Digit_04_HVB 1;
BA_ "EventTrans" SG_ 2651930638 Digit_05_HVB 0;
BA_ "GenSigSendType" SG_ 2651930638 Digit_05_HVB 1;
BA_ "EventTrans" SG_ 2651930638 Digit_02_HVB 0;
BA_ "GenSigSendType" SG_ 2651930638 Digit_02_HVB 1;
BA_ "EventTrans" SG_ 2651930638 Digit_03_HVB 0;
BA_ "GenSigSendType" SG_ 2651930638 Digit_03_HVB 1;
BA_ "EventTrans" SG_ 2651930638 Digit_01_HVB 0;
BA_ "GenSigSendType" SG_ 2651930638 Digit_01_HVB 1;
BA_ "EventTrans" SG_ 2651930650 Digit_10_NAB 0;
BA_ "GenSigSendType" SG_ 2651930650 Digit_10_NAB 1;
BA_ "EventTrans" SG_ 2651930650 Digit_11_NAB 0;
BA_ "GenSigSendType" SG_ 2651930650 Digit_11_NAB 1;
BA_ "EventTrans" SG_ 2651930650 Digit_08_NAB 0;
BA_ "GenSigSendType" SG_ 2651930650 Digit_08_NAB 1;
BA_ "EventTrans" SG_ 2651930650 Digit_09_NAB 0;
BA_ "GenSigSendType" SG_ 2651930650 Digit_09_NAB 1;
BA_ "EventTrans" SG_ 2651930650 Digit_06_NAB 0;
BA_ "GenSigSendType" SG_ 2651930650 Digit_06_NAB 1;
BA_ "EventTrans" SG_ 2651930650 Digit_07_NAB 0;
BA_ "GenSigSendType" SG_ 2651930650 Digit_07_NAB 1;
BA_ "EventTrans" SG_ 2651930650 Digit_04_NAB 0;
BA_ "GenSigSendType" SG_ 2651930650 Digit_04_NAB 1;
BA_ "EventTrans" SG_ 2651930650 Digit_05_NAB 0;
BA_ "GenSigSendType" SG_ 2651930650 Digit_05_NAB 1;
BA_ "EventTrans" SG_ 2651930650 Digit_02_NAB 0;
BA_ "GenSigSendType" SG_ 2651930650 Digit_02_NAB 1;
BA_ "EventTrans" SG_ 2651930650 Digit_03_NAB 0;
BA_ "GenSigSendType" SG_ 2651930650 Digit_03_NAB 1;
BA_ "EventTrans" SG_ 2651930650 Digit_01_NAB 0;
BA_ "GenSigSendType" SG_ 2651930650 Digit_01_NAB 1;
BA_ "EventTrans" SG_ 2651930654 Digit_10_HALF 0;
BA_ "GenSigSendType" SG_ 2651930654 Digit_10_HALF 1;
BA_ "EventTrans" SG_ 2651930654 Digit_11_HALF 0;
BA_ "GenSigSendType" SG_ 2651930654 Digit_11_HALF 1;
BA_ "EventTrans" SG_ 2651930654 Digit_08_HALF 0;
BA_ "GenSigSendType" SG_ 2651930654 Digit_08_HALF 1;
BA_ "EventTrans" SG_ 2651930654 Digit_09_HALF 0;
BA_ "GenSigSendType" SG_ 2651930654 Digit_09_HALF 1;
BA_ "EventTrans" SG_ 2651930654 Digit_06_HALF 0;
BA_ "GenSigSendType" SG_ 2651930654 Digit_06_HALF 1;
BA_ "EventTrans" SG_ 2651930654 Digit_07_HALF 0;
BA_ "GenSigSendType" SG_ 2651930654 Digit_07_HALF 1;
BA_ "EventTrans" SG_ 2651930654 Digit_04_HALF 0;
BA_ "GenSigSendType" SG_ 2651930654 Digit_04_HALF 1;
BA_ "EventTrans" SG_ 2651930654 Digit_05_HALF 0;
BA_ "GenSigSendType" SG_ 2651930654 Digit_05_HALF 1;
BA_ "EventTrans" SG_ 2651930654 Digit_02_HALF 0;
BA_ "GenSigSendType" SG_ 2651930654 Digit_02_HALF 1;
BA_ "EventTrans" SG_ 2651930654 Digit_03_HALF 0;
BA_ "GenSigSendType" SG_ 2651930654 Digit_03_HALF 1;
BA_ "EventTrans" SG_ 2651930654 Digit_01_HALF 0;
BA_ "GenSigSendType" SG_ 2651930654 Digit_01_HALF 1;
BA_ "EventTrans" SG_ 2651930672 Digit_10_PCU 0;
BA_ "GenSigSendType" SG_ 2651930672 Digit_10_PCU 1;
BA_ "EventTrans" SG_ 2651930672 Digit_11_PCU 0;
BA_ "GenSigSendType" SG_ 2651930672 Digit_11_PCU 1;
BA_ "EventTrans" SG_ 2651930672 Digit_08_PCU 0;
BA_ "GenSigSendType" SG_ 2651930672 Digit_08_PCU 1;
BA_ "EventTrans" SG_ 2651930672 Digit_09_PCU 0;
BA_ "GenSigSendType" SG_ 2651930672 Digit_09_PCU 1;
BA_ "EventTrans" SG_ 2651930672 Digit_06_PCU 0;
BA_ "GenSigSendType" SG_ 2651930672 Digit_06_PCU 1;
BA_ "EventTrans" SG_ 2651930672 Digit_07_PCU 0;
BA_ "GenSigSendType" SG_ 2651930672 Digit_07_PCU 1;
BA_ "EventTrans" SG_ 2651930672 Digit_04_PCU 0;
BA_ "GenSigSendType" SG_ 2651930672 Digit_04_PCU 1;
BA_ "EventTrans" SG_ 2651930672 Digit_05_PCU 0;
BA_ "GenSigSendType" SG_ 2651930672 Digit_05_PCU 1;
BA_ "EventTrans" SG_ 2651930672 Digit_02_PCU 0;
BA_ "GenSigSendType" SG_ 2651930672 Digit_02_PCU 1;
BA_ "EventTrans" SG_ 2651930672 Digit_03_PCU 0;
BA_ "GenSigSendType" SG_ 2651930672 Digit_03_PCU 1;
BA_ "EventTrans" SG_ 2651930672 Digit_01_PCU 0;
BA_ "GenSigSendType" SG_ 2651930672 Digit_01_PCU 1;
BA_ "EventTrans" SG_ 2651930673 Digit_10_OBC 0;
BA_ "GenSigSendType" SG_ 2651930673 Digit_10_OBC 1;
BA_ "EventTrans" SG_ 2651930673 Digit_11_OBC 0;
BA_ "GenSigSendType" SG_ 2651930673 Digit_11_OBC 1;
BA_ "EventTrans" SG_ 2651930673 Digit_08_OBC 0;
BA_ "GenSigSendType" SG_ 2651930673 Digit_08_OBC 1;
BA_ "EventTrans" SG_ 2651930673 Digit_09_OBC 0;
BA_ "GenSigSendType" SG_ 2651930673 Digit_09_OBC 1;
BA_ "EventTrans" SG_ 2651930673 Digit_06_OBC 0;
BA_ "GenSigSendType" SG_ 2651930673 Digit_06_OBC 1;
BA_ "EventTrans" SG_ 2651930673 Digit_07_OBC 0;
BA_ "GenSigSendType" SG_ 2651930673 Digit_07_OBC 1;
BA_ "EventTrans" SG_ 2651930673 Digit_04_OBC 0;
BA_ "GenSigSendType" SG_ 2651930673 Digit_04_OBC 1;
BA_ "EventTrans" SG_ 2651930673 Digit_05_OBC 0;
BA_ "GenSigSendType" SG_ 2651930673 Digit_05_OBC 1;
BA_ "EventTrans" SG_ 2651930673 Digit_02_OBC 0;
BA_ "GenSigSendType" SG_ 2651930673 Digit_02_OBC 1;
BA_ "EventTrans" SG_ 2651930673 Digit_03_OBC 0;
BA_ "GenSigSendType" SG_ 2651930673 Digit_03_OBC 1;
BA_ "EventTrans" SG_ 2651930673 Digit_01_OBC 0;
BA_ "GenSigSendType" SG_ 2651930673 Digit_01_OBC 1;
BA_ "EventTrans" SG_ 2651930674 Digit_10_P2 0;
BA_ "GenSigSendType" SG_ 2651930674 Digit_10_P2 1;
BA_ "EventTrans" SG_ 2651930674 Digit_11_P2 0;
BA_ "GenSigSendType" SG_ 2651930674 Digit_11_P2 1;
BA_ "EventTrans" SG_ 2651930674 Digit_08_P2 0;
BA_ "GenSigSendType" SG_ 2651930674 Digit_08_P2 1;
BA_ "EventTrans" SG_ 2651930674 Digit_09_P2 0;
BA_ "GenSigSendType" SG_ 2651930674 Digit_09_P2 1;
BA_ "EventTrans" SG_ 2651930674 Digit_06_P2 0;
BA_ "GenSigSendType" SG_ 2651930674 Digit_06_P2 1;
BA_ "EventTrans" SG_ 2651930674 Digit_07_P2 0;
BA_ "GenSigSendType" SG_ 2651930674 Digit_07_P2 1;
BA_ "EventTrans" SG_ 2651930674 Digit_04_P2 0;
BA_ "GenSigSendType" SG_ 2651930674 Digit_04_P2 1;
BA_ "EventTrans" SG_ 2651930674 Digit_05_P2 0;
BA_ "GenSigSendType" SG_ 2651930674 Digit_05_P2 1;
BA_ "EventTrans" SG_ 2651930674 Digit_02_P2 0;
BA_ "GenSigSendType" SG_ 2651930674 Digit_02_P2 1;
BA_ "EventTrans" SG_ 2651930674 Digit_03_P2 0;
BA_ "GenSigSendType" SG_ 2651930674 Digit_03_P2 1;
BA_ "EventTrans" SG_ 2651930674 Digit_01_P2 0;
BA_ "GenSigSendType" SG_ 2651930674 Digit_01_P2 1;
BA_ "EventTrans" SG_ 2651930681 Digit_10_DASM 0;
BA_ "GenSigSendType" SG_ 2651930681 Digit_10_DASM 1;
BA_ "EventTrans" SG_ 2651930681 Digit_11_DASM 0;
BA_ "GenSigSendType" SG_ 2651930681 Digit_11_DASM 1;
BA_ "EventTrans" SG_ 2651930681 Digit_08_DASM 0;
BA_ "GenSigSendType" SG_ 2651930681 Digit_08_DASM 1;
BA_ "EventTrans" SG_ 2651930681 Digit_09_DASM 0;
BA_ "GenSigSendType" SG_ 2651930681 Digit_09_DASM 1;
BA_ "EventTrans" SG_ 2651930681 Digit_06_DASM 0;
BA_ "GenSigSendType" SG_ 2651930681 Digit_06_DASM 1;
BA_ "EventTrans" SG_ 2651930681 Digit_07_DASM 0;
BA_ "GenSigSendType" SG_ 2651930681 Digit_07_DASM 1;
BA_ "EventTrans" SG_ 2651930681 Digit_04_DASM 0;
BA_ "GenSigSendType" SG_ 2651930681 Digit_04_DASM 1;
BA_ "EventTrans" SG_ 2651930681 Digit_05_DASM 0;
BA_ "GenSigSendType" SG_ 2651930681 Digit_05_DASM 1;
BA_ "EventTrans" SG_ 2651930681 Digit_02_DASM 0;
BA_ "GenSigSendType" SG_ 2651930681 Digit_02_DASM 1;
BA_ "EventTrans" SG_ 2651930681 Digit_03_DASM 0;
BA_ "GenSigSendType" SG_ 2651930681 Digit_03_DASM 1;
BA_ "EventTrans" SG_ 2651930681 Digit_01_DASM 0;
BA_ "GenSigSendType" SG_ 2651930681 Digit_01_DASM 1;
BA_ "EventTrans" SG_ 2651930714 Digit_10_ADC 0;
BA_ "GenSigSendType" SG_ 2651930714 Digit_10_ADC 1;
BA_ "EventTrans" SG_ 2651930714 Digit_11_ADC 0;
BA_ "GenSigSendType" SG_ 2651930714 Digit_11_ADC 1;
BA_ "EventTrans" SG_ 2651930714 Digit_08_ADC 0;
BA_ "GenSigSendType" SG_ 2651930714 Digit_08_ADC 1;
BA_ "EventTrans" SG_ 2651930714 Digit_09_ADC 0;
BA_ "GenSigSendType" SG_ 2651930714 Digit_09_ADC 1;
BA_ "EventTrans" SG_ 2651930714 Digit_06_ADC 0;
BA_ "GenSigSendType" SG_ 2651930714 Digit_06_ADC 1;
BA_ "EventTrans" SG_ 2651930714 Digit_07_ADC 0;
BA_ "GenSigSendType" SG_ 2651930714 Digit_07_ADC 1;
BA_ "EventTrans" SG_ 2651930714 Digit_04_ADC 0;
BA_ "GenSigSendType" SG_ 2651930714 Digit_04_ADC 1;
BA_ "EventTrans" SG_ 2651930714 Digit_05_ADC 0;
BA_ "GenSigSendType" SG_ 2651930714 Digit_05_ADC 1;
BA_ "EventTrans" SG_ 2651930714 Digit_02_ADC 0;
BA_ "GenSigSendType" SG_ 2651930714 Digit_02_ADC 1;
BA_ "EventTrans" SG_ 2651930714 Digit_03_ADC 0;
BA_ "GenSigSendType" SG_ 2651930714 Digit_03_ADC 1;
BA_ "EventTrans" SG_ 2651930714 Digit_01_ADC 0;
BA_ "GenSigSendType" SG_ 2651930714 Digit_01_ADC 1;
BA_ "EventTrans" SG_ 2651930739 Digit_10_LCUL 0;
BA_ "GenSigSendType" SG_ 2651930739 Digit_10_LCUL 1;
BA_ "EventTrans" SG_ 2651930739 Digit_11_LCUL 0;
BA_ "GenSigSendType" SG_ 2651930739 Digit_11_LCUL 1;
BA_ "EventTrans" SG_ 2651930739 Digit_08_LCUL 0;
BA_ "GenSigSendType" SG_ 2651930739 Digit_08_LCUL 1;
BA_ "EventTrans" SG_ 2651930739 Digit_09_LCUL 0;
BA_ "GenSigSendType" SG_ 2651930739 Digit_09_LCUL 1;
BA_ "EventTrans" SG_ 2651930739 Digit_06_LCUL 0;
BA_ "GenSigSendType" SG_ 2651930739 Digit_06_LCUL 1;
BA_ "EventTrans" SG_ 2651930739 Digit_07_LCUL 0;
BA_ "GenSigSendType" SG_ 2651930739 Digit_07_LCUL 1;
BA_ "EventTrans" SG_ 2651930739 Digit_04_LCUL 0;
BA_ "GenSigSendType" SG_ 2651930739 Digit_04_LCUL 1;
BA_ "EventTrans" SG_ 2651930739 Digit_05_LCUL 0;
BA_ "GenSigSendType" SG_ 2651930739 Digit_05_LCUL 1;
BA_ "EventTrans" SG_ 2651930739 Digit_02_LCUL 0;
BA_ "GenSigSendType" SG_ 2651930739 Digit_02_LCUL 1;
BA_ "EventTrans" SG_ 2651930739 Digit_03_LCUL 0;
BA_ "GenSigSendType" SG_ 2651930739 Digit_03_LCUL 1;
BA_ "EventTrans" SG_ 2651930739 Digit_01_LCUL 0;
BA_ "GenSigSendType" SG_ 2651930739 Digit_01_LCUL 1;
BA_ "EventTrans" SG_ 2651930748 Digit_10_LCUR 0;
BA_ "GenSigSendType" SG_ 2651930748 Digit_10_LCUR 1;
BA_ "EventTrans" SG_ 2651930748 Digit_11_LCUR 0;
BA_ "GenSigSendType" SG_ 2651930748 Digit_11_LCUR 1;
BA_ "EventTrans" SG_ 2651930748 Digit_08_LCUR 0;
BA_ "GenSigSendType" SG_ 2651930748 Digit_08_LCUR 1;
BA_ "EventTrans" SG_ 2651930748 Digit_09_LCUR 0;
BA_ "GenSigSendType" SG_ 2651930748 Digit_09_LCUR 1;
BA_ "EventTrans" SG_ 2651930748 Digit_06_LCUR 0;
BA_ "GenSigSendType" SG_ 2651930748 Digit_06_LCUR 1;
BA_ "EventTrans" SG_ 2651930748 Digit_07_LCUR 0;
BA_ "GenSigSendType" SG_ 2651930748 Digit_07_LCUR 1;
BA_ "EventTrans" SG_ 2651930748 Digit_04_LCUR 0;
BA_ "GenSigSendType" SG_ 2651930748 Digit_04_LCUR 1;
BA_ "EventTrans" SG_ 2651930748 Digit_05_LCUR 0;
BA_ "GenSigSendType" SG_ 2651930748 Digit_05_LCUR 1;
BA_ "EventTrans" SG_ 2651930748 Digit_02_LCUR 0;
BA_ "GenSigSendType" SG_ 2651930748 Digit_02_LCUR 1;
BA_ "EventTrans" SG_ 2651930748 Digit_03_LCUR 0;
BA_ "GenSigSendType" SG_ 2651930748 Digit_03_LCUR 1;
BA_ "EventTrans" SG_ 2651930748 Digit_01_LCUR 0;
BA_ "GenSigSendType" SG_ 2651930748 Digit_01_LCUR 1;
BA_ "EventTrans" SG_ 2654208000 WakeRsn_BCM 0;
BA_ "GenSigSendType" SG_ 2654208000 WakeRsn_BCM 3;
BA_ "EventTrans" SG_ 2654208000 MainWakeSts_BCM 0;
BA_ "GenSigSendType" SG_ 2654208000 MainWakeSts_BCM 3;
BA_ "EventTrans" SG_ 2654208000 WakeCntr_BCM 0;
BA_ "GenSigSendType" SG_ 2654208000 WakeCntr_BCM 3;
BA_ "EventTrans" SG_ 2654208001 WakeRsn_NCM 0;
BA_ "GenSigSendType" SG_ 2654208001 WakeRsn_NCM 1;
BA_ "EventTrans" SG_ 2654208001 WakeReq_NCM 0;
BA_ "GenSigSendType" SG_ 2654208001 WakeReq_NCM 1;
BA_ "EventTrans" SG_ 2654208001 WakeCntr_NCM 0;
BA_ "GenSigSendType" SG_ 2654208001 WakeCntr_NCM 1;
BA_ "EventTrans" SG_ 2654208001 WakeUpNodeAddress 0;
BA_ "GenSigSendType" SG_ 2654208001 WakeUpNodeAddress 1;
BA_ "EventTrans" SG_ 2654208006 WakeRsn_NFR 0;
BA_ "GenSigSendType" SG_ 2654208006 WakeRsn_NFR 1;
BA_ "EventTrans" SG_ 2654208006 WakeReq_NFR 0;
BA_ "GenSigSendType" SG_ 2654208006 WakeReq_NFR 1;
BA_ "EventTrans" SG_ 2654208006 WakeCntr_NFR 0;
BA_ "GenSigSendType" SG_ 2654208006 WakeCntr_NFR 1;
BA_ "EventTrans" SG_ 2654208006 WakeUpNodeAddress 0;
BA_ "GenSigSendType" SG_ 2654208006 WakeUpNodeAddress 1;
BA_ "EventTrans" SG_ 2654208014 WakeRsn_HVB 0;
BA_ "GenSigSendType" SG_ 2654208014 WakeRsn_HVB 1;
BA_ "EventTrans" SG_ 2654208014 WakeReq_HVB 0;
BA_ "GenSigSendType" SG_ 2654208014 WakeReq_HVB 1;
BA_ "EventTrans" SG_ 2654208014 WakeCntr_HVB 0;
BA_ "GenSigSendType" SG_ 2654208014 WakeCntr_HVB 1;
BA_ "EventTrans" SG_ 2654208014 WakeUpNodeAddress 0;
BA_ "GenSigSendType" SG_ 2654208014 WakeUpNodeAddress 1;
BA_ "EventTrans" SG_ 2654208026 WakeRsn_NAB 0;
BA_ "GenSigSendType" SG_ 2654208026 WakeRsn_NAB 1;
BA_ "EventTrans" SG_ 2654208026 WakeReq_NAB 0;
BA_ "GenSigSendType" SG_ 2654208026 WakeReq_NAB 1;
BA_ "EventTrans" SG_ 2654208026 WakeCntr_NAB 0;
BA_ "GenSigSendType" SG_ 2654208026 WakeCntr_NAB 1;
BA_ "EventTrans" SG_ 2654208026 WakeUpNodeAddress 0;
BA_ "GenSigSendType" SG_ 2654208026 WakeUpNodeAddress 1;
BA_ "EventTrans" SG_ 2654208028 WakeRsn_NTP 0;
BA_ "GenSigSendType" SG_ 2654208028 WakeRsn_NTP 1;
BA_ "EventTrans" SG_ 2654208028 WakeReq_NTP 0;
BA_ "GenSigSendType" SG_ 2654208028 WakeReq_NTP 1;
BA_ "EventTrans" SG_ 2654208028 WakeCntr_NTP 0;
BA_ "GenSigSendType" SG_ 2654208028 WakeCntr_NTP 1;
BA_ "EventTrans" SG_ 2654208028 WakeUpNodeAddress 0;
BA_ "GenSigSendType" SG_ 2654208028 WakeUpNodeAddress 1;
BA_ "EventTrans" SG_ 2654208048 WakeRsn_PCU 0;
BA_ "GenSigSendType" SG_ 2654208048 WakeRsn_PCU 1;
BA_ "EventTrans" SG_ 2654208048 WakeReq_PCU 0;
BA_ "GenSigSendType" SG_ 2654208048 WakeReq_PCU 1;
BA_ "EventTrans" SG_ 2654208048 WakeCntr_PCU 0;
BA_ "GenSigSendType" SG_ 2654208048 WakeCntr_PCU 1;
BA_ "EventTrans" SG_ 2654208048 WakeUpNodeAddress 0;
BA_ "GenSigSendType" SG_ 2654208048 WakeUpNodeAddress 1;
BA_ "EventTrans" SG_ 2654208049 WakeRsn_OBC 0;
BA_ "GenSigSendType" SG_ 2654208049 WakeRsn_OBC 1;
BA_ "EventTrans" SG_ 2654208049 WakeReq_OBC 0;
BA_ "GenSigSendType" SG_ 2654208049 WakeReq_OBC 1;
BA_ "EventTrans" SG_ 2654208049 WakeCntr_OBC 0;
BA_ "GenSigSendType" SG_ 2654208049 WakeCntr_OBC 1;
BA_ "EventTrans" SG_ 2654208049 WakeUpNodeAddress 0;
BA_ "GenSigSendType" SG_ 2654208049 WakeUpNodeAddress 1;
BA_ "EventTrans" SG_ 2654208050 WakeRsn_P2 0;
BA_ "GenSigSendType" SG_ 2654208050 WakeRsn_P2 1;
BA_ "EventTrans" SG_ 2654208050 WakeReq_P2 0;
BA_ "GenSigSendType" SG_ 2654208050 WakeReq_P2 1;
BA_ "EventTrans" SG_ 2654208050 WakeCntr_P2 0;
BA_ "GenSigSendType" SG_ 2654208050 WakeCntr_P2 1;
BA_ "EventTrans" SG_ 2654208050 WakeUpNodeAddress 0;
BA_ "GenSigSendType" SG_ 2654208050 WakeUpNodeAddress 1;
BA_ "EventTrans" SG_ 2654208090 WakeRsn_ADC 0;
BA_ "GenSigSendType" SG_ 2654208090 WakeRsn_ADC 1;
BA_ "EventTrans" SG_ 2654208090 WakeReq_ADC 0;
BA_ "GenSigSendType" SG_ 2654208090 WakeReq_ADC 1;
BA_ "EventTrans" SG_ 2654208090 WakeCntr_ADC 0;
BA_ "GenSigSendType" SG_ 2654208090 WakeCntr_ADC 1;
BA_ "EventTrans" SG_ 2654208090 WakeUpNodeAddress 0;
BA_ "GenSigSendType" SG_ 2654208090 WakeUpNodeAddress 1;
BA_ "GenSigStartValue" SG_ 2654339122 P2_Power 127;
BA_ "EventTrans" SG_ 2654339187 Left_LB_Feedback_LCUL_C1 0;
BA_ "GenSigSendType" SG_ 2654339187 Left_LB_Feedback_LCUL_C1 3;
BA_ "EventTrans" SG_ 2654339187 Left_LB_FailSts 0;
BA_ "GenSigSendType" SG_ 2654339187 Left_LB_FailSts 3;
BA_ "EventTrans" SG_ 2654339187 Left_HB_Feedback_LCUL_C1 0;
BA_ "GenSigSendType" SG_ 2654339187 Left_HB_Feedback_LCUL_C1 3;
BA_ "EventTrans" SG_ 2654339187 Left_HB_FailSts 0;
BA_ "GenSigSendType" SG_ 2654339187 Left_HB_FailSts 3;
BA_ "EventTrans" SG_ 2654339187 Left_PL_Feedback_LCUL_C1 0;
BA_ "GenSigSendType" SG_ 2654339187 Left_PL_Feedback_LCUL_C1 3;
BA_ "EventTrans" SG_ 2654339187 Left_PL_FailSts 0;
BA_ "GenSigSendType" SG_ 2654339187 Left_PL_FailSts 3;
BA_ "EventTrans" SG_ 2654339187 Left_DRL_Feedback_LCUL_C1 0;
BA_ "GenSigSendType" SG_ 2654339187 Left_DRL_Feedback_LCUL_C1 3;
BA_ "EventTrans" SG_ 2654339187 Left_DRL_FailSts 0;
BA_ "GenSigSendType" SG_ 2654339187 Left_DRL_FailSts 3;
BA_ "EventTrans" SG_ 2654339187 Left_TI_Feedback_LCUL_C1 0;
BA_ "GenSigSendType" SG_ 2654339187 Left_TI_Feedback_LCUL_C1 3;
BA_ "EventTrans" SG_ 2654339187 Left_TI_FailSts_LCUL_C1 0;
BA_ "GenSigSendType" SG_ 2654339187 Left_TI_FailSts_LCUL_C1 3;
BA_ "EventTrans" SG_ 2654339187 Left_LVL_FailSts 0;
BA_ "GenSigSendType" SG_ 2654339187 Left_LVL_FailSts 3;
BA_ "EventTrans" SG_ 2654339187 Left_FBLFaiLSts 0;
BA_ "GenSigSendType" SG_ 2654339187 Left_FBLFaiLSts 3;
BA_ "EventTrans" SG_ 2654339187 ADB_FailSts_LH 0;
BA_ "GenSigSendType" SG_ 2654339187 ADB_FailSts_LH 3;
BA_ "EventTrans" SG_ 2654339187 Left_ParkingLight_Feedback_LCUL1 0;
BA_ "GenSigSendType" SG_ 2654339187 Left_ParkingLight_Feedback_LCUL1 3;
BA_ "EventTrans" SG_ 2654339187 Left_TrafficChangeFbk 0;
BA_ "GenSigSendType" SG_ 2654339187 Left_TrafficChangeFbk 3;
BA_ "EventTrans" SG_ 2654339187 Left_DodecaDriver_Failure 0;
BA_ "GenSigSendType" SG_ 2654339187 Left_DodecaDriver_Failure 3;
BA_ "EventTrans" SG_ 2654339196 Right_LB_Feedback_LCUR_C1 0;
BA_ "GenSigSendType" SG_ 2654339196 Right_LB_Feedback_LCUR_C1 3;
BA_ "EventTrans" SG_ 2654339196 Right_LB_FailSts 0;
BA_ "GenSigSendType" SG_ 2654339196 Right_LB_FailSts 3;
BA_ "EventTrans" SG_ 2654339196 Right_HB_Feedback_LCUR_C1 0;
BA_ "GenSigSendType" SG_ 2654339196 Right_HB_Feedback_LCUR_C1 3;
BA_ "EventTrans" SG_ 2654339196 Right_HB_FailSts 0;
BA_ "GenSigSendType" SG_ 2654339196 Right_HB_FailSts 3;
BA_ "EventTrans" SG_ 2654339196 Right_PL_Feedback_LCUR_C1 0;
BA_ "GenSigSendType" SG_ 2654339196 Right_PL_Feedback_LCUR_C1 3;
BA_ "EventTrans" SG_ 2654339196 Right_PL_FailSts 0;
BA_ "GenSigSendType" SG_ 2654339196 Right_PL_FailSts 3;
BA_ "EventTrans" SG_ 2654339196 Right_DRL_Feedback_LCUR_C1 0;
BA_ "GenSigSendType" SG_ 2654339196 Right_DRL_Feedback_LCUR_C1 3;
BA_ "EventTrans" SG_ 2654339196 Right_DRL_FailSts 0;
BA_ "GenSigSendType" SG_ 2654339196 Right_DRL_FailSts 3;
BA_ "EventTrans" SG_ 2654339196 Right_TI_Feedback_LCUR_C1 0;
BA_ "GenSigSendType" SG_ 2654339196 Right_TI_Feedback_LCUR_C1 3;
BA_ "EventTrans" SG_ 2654339196 Right_TI_FailSts_LCUR_C1 0;
BA_ "GenSigSendType" SG_ 2654339196 Right_TI_FailSts_LCUR_C1 3;
BA_ "EventTrans" SG_ 2654339196 Right_LVL_FailSts 0;
BA_ "GenSigSendType" SG_ 2654339196 Right_LVL_FailSts 3;
BA_ "EventTrans" SG_ 2654339196 Right_FBLFaiLSts 0;
BA_ "GenSigSendType" SG_ 2654339196 Right_FBLFaiLSts 3;
BA_ "EventTrans" SG_ 2654339196 ADB_FailSts_RH 0;
BA_ "GenSigSendType" SG_ 2654339196 ADB_FailSts_RH 3;
BA_ "EventTrans" SG_ 2654339196 Right_ParkingLight_Feedback_LCUR 0;
BA_ "GenSigSendType" SG_ 2654339196 Right_ParkingLight_Feedback_LCUR 3;
BA_ "EventTrans" SG_ 2654339196 Right_TrafficChangeFbk 0;
BA_ "GenSigSendType" SG_ 2654339196 Right_TrafficChangeFbk 3;
BA_ "EventTrans" SG_ 2654339196 Right_DodecaDriver_Failure 0;
BA_ "GenSigSendType" SG_ 2654339196 Right_DodecaDriver_Failure 3;
VAL_ 1441 EngineOilTemperature 0 "FaultValue" ;
VAL_ 1441 ReducePowerAssist 0 "Not_Active" 1 "Active" ;
VAL_ 1441 EM_Ready_Indication 0 "Not_Active" 1 "Active" ;
VAL_ 1441 FuelCapCheckWarning 0 "OFF" 1 "ON" ;
VAL_ 1441 VehicleNotInUse 0 "Vehicle_in_Use" 1 "Start_Countdown" 2 "Start_Signalling" 3 "System_Failure" ;
VAL_ 1441 EngineOilTemperatureValidData 0 "Valid" 1 "Not_Valid" ;
VAL_ 1441 CruiseControlSts 0 "Not_inserted" 1 "Inserted" ;
VAL_ 1441 CruiseControlLampSts 0 "cruise_off" 1 "cruise_on_not_engaged" 2 "cruise_on_engaged" 3 "cruise_error" ;
VAL_ 1441 RechargeSts 0 "Charging" 1 "Not_charging" ;
VAL_ 1441 BatteryVoltageLevelFailSts 0 "Fail_not_present" 1 "Fail_present" ;
VAL_ 1441 StopStartVisualizationCode 0 "No_visualization" 1 "StopStart_Failure_Go_to_dealer" 2 "Stop_E_Start_Active" 3 "Stop_E_Start_Not_available" 4 "Stop_E_Start_OFF" 5 "Stop_E_Start_ON" 6 "Release_The_accelerator_Pedal" 7 "SS_temp_inhibit_Fasten_SeatBelt" 8 "SS_temp_inhibit_Close_Psgr_Door" 9 "Press_Engine_Start_to_Restart" 10 "Depress_Brake_Pedal" 11 "Press_and_hold_EngStart_to_start" 12 "Stop_E_Start_Failure" 13 "Starter_failure_Go_to_dealer" 14 "Stop_E_Start_Temp_Inhibit" 15 "Not_used" ;
VAL_ 1441 EngineSts 0 "Engine_OFF" 1 "Engine_ON" 2 "Engine_cranking" 3 "Engine_Shut_down" ;
VAL_ 1441 StopStartSts 0 "Off" 1 "On" 2 "Engine_Restart" 3 "Stop_Request" ;
VAL_ 1441 ColdStartTime 0 "Time_not_elapsed" 1 "Time_elapsed" ;
VAL_ 1441 NCMMildHybSysWarningForDisplay 0 "No_Warning" 1 "Temporary_Fault" 2 "Permanent_Fault" 3 "Stop_The_CAR" 4 "Not_used" 5 "Not_used" 6 "Not_used" 7 "Not_used" 8 "Not_used" 9 "Not_used" 10 "Not_used" 11 "Not_used" 12 "Not_used" 13 "Not_used" 14 "Not_used" 15 "Not_used" ;
VAL_ 1441 EDriveSts 0 "Off" 1 "Prepare_E_Drive" 2 "E_Drive" 3 "Stop_E_Drive" ;
VAL_ 1441 EngineBonnetSts2 0 "Closed" 1 "Open" ;
VAL_ 1442 NCM_EOBDII_SecondaryNodes 7 "Not_used" 6 "BSG" 5 "NCP" 4 "NPS" 3 "NSV" 2 "NCL" 0 "None" 1 "NBC" ;
VAL_ 1442 NCM_EOBDII_FailureCleaningRqt 0 "NO_Cleaning_Request" 1 "Cleaning_Request" ;
VAL_ 1442 HotPipeFatigueIntegrity 0 "init" 1 "Valid" ;
VAL_ 1442 HotPipeFailSts 0 "Fail_not_present" 1 "Fail_Present" ;
VAL_ 1442 NCMCrashSts 0 "Not_Active" 1 "Active" ;
VAL_ 1445 MsgFOBLeftVeh 0 "MSG_DEFAULT" 1 "MSG_ACTIVE" 2 "Not_used" 3 "SNA" ;
VAL_ 1445 PowerModeSts_NPE 0 "Standard_Power" 1 "Logistic_Mode_ON" 2 "Logistic_Mode_PR" 3 "Not_used" ;
VAL_ 1445 KeyProgramSts 0 "RKE_NORM_STAT" 1 "EN_KEY_PROG" 2 "PROG_ACT" 3 "EX_KEY_PROG" 4 "KEY_PROG" 5 "DMG_KEY" 6 "INV_KEY" 7 "EXCD_KEY" 8 "RKE_BATT_LO" 9 "SRV_SKREEM" 10 "BTN_DLY_ACT" 11 "BTN_DLY_INACT" 12 "KEY_NOT_PROG" 13 "Not_used" 14 "Not_used" 15 "SNA" ;
VAL_ 1445 MsgServPEKG 0 "MSG_DEFAULT" 1 "MSG_ACTIVE" 2 "Not_used" 3 "SNA" ;
VAL_ 1445 MsgPutInPark 0 "MSG_DEFAULT" 1 "MSG_ACTIVE" 2 "Not_used" 3 "SNA" ;
VAL_ 1445 MsgNotInPark 0 "MSG_DEFAULT" 1 "MSG_ACTIVE" 2 "Not_used" 3 "SNA" ;
VAL_ 1445 MsgFOBNotFnd 0 "MSG_DEFAULT" 1 "MSG_ACTIVE" 2 "Not_used" 3 "SNA" ;
VAL_ 1445 MsgAutoIgnOFF 0 "No_Message" 1 "Engine_ON_Required" 2 "Key_OFF_Ongoing" 3 "Not_used" ;
VAL_ 1459 OCSM_Passenger_Classification 0 "Not_Used" 1 "Child" 2 "Adult" 3 "Indeterminate" ;
VAL_ 1459 OCSSts 0 "OK" 1 "Fail" ;
VAL_ 1459 DrvSbltUnFltr 0 "Seat_belt_fastened_buckled" 1 "Seatbelt_not_fastened_unbuckled" 2 "Seatbelt_shorted_low" 3 "Seatbelt_shorted_high" 4 "Not_used" 5 "Not_used" 6 "Not_used" 7 "SNA" ;
VAL_ 1459 NEC_Replacement_Warning 0 "Not_Active" 1 "Active" ;
VAL_ 1459 OCSM_Passenger_Detected 0 "False" 1 "True" ;
VAL_ 1486 HybridSystemWarningForDisplay 0 "no_messages" 1 "HybridSystemFailure" 2 "HybridSystemFailure_GoToDealer_" 3 "HybridFailure_Stop_E_TurnOff_" 4 "Plug_in_recharge_not_available" 5 "PlugInRechNotAvail_GoToDealer_" 6 "PlugInRechNotAvail_CheckPlug" 7 "NextVehicleStartNotAvailable" 8 "NextStartNotAvailableGoToDealer" 9 "High_Voltage_Disabled" 10 "LVB_recharge_not_available_" 11 "LVBRechNotAvailable_GoToDealer_" 12 "LVBRechNotAvail_Stop_E_TurnOff" 13 "PlugInCarInCaseLongParking" 14 "PlugInCarLongParking_GoToDealer_" 15 "Fault_message_15" 16 "Plug_in_the_car_immediatly_" 17 "PlugInCarImmediatly_GoToDealer_" 18 "Fault_message_18" 19 "Plug_in_recharge_not_been_done_" 20 "PlugInRechNotBeenDoneGoToDealer" 21 "Long_Parking_Performed" 22 "Thermal_runaway_danger" 23 "Fault_message_23" 24 "Turn_On_Engine" 25 "Connect_LV_Charger" 26 "Fault_message_26" 27 "Fault_message_27" 28 "Fault_message_28" 29 "Fault_message_29" 30 "Fault_message_30" 31 "Fault_message_31" 32 "Fault_message_32" 33 "Fault_message_33" 34 "Fault_message_34" 35 "Fault_message_35" 36 "not_used" 37 "not_used" 38 "not_used" 39 "not_used" 40 "not_used" 41 "not_used" 42 "not_used" 43 "not_used" 44 "not_used" 45 "not_used" 46 "not_used" 47 "not_used" 48 "not_used" 49 "not_used" 50 "not_used" 51 "not_used" 52 "not_used" 53 "not_used" 54 "not_used" 55 "not_used" 56 "not_used" 57 "not_used" 58 "not_used" 59 "not_used" 60 "not_used" 61 "not_used" 62 "not_used" 63 "not_used" 64 "not_used" 65 "not_used" 66 "not_used" 67 "not_used" 68 "not_used" 69 "not_used" 70 "not_used" 71 "not_used" 72 "not_used" 73 "not_used" 74 "not_used" 75 "not_used" 76 "not_used" 77 "not_used" 78 "not_used" 79 "not_used" 80 "not_used" 81 "not_used" 82 "not_used" 83 "not_used" 84 "not_used" 85 "not_used" 86 "not_used" 87 "not_used" 88 "not_used" 89 "not_used" 90 "not_used" 91 "not_used" 92 "not_used" 93 "not_used" 94 "not_used" 95 "not_used" 96 "not_used" 97 "not_used" 98 "not_used" 99 "not_used" 100 "not_used" 101 "not_used" 102 "not_used" 103 "not_used" 104 "not_used" 105 "not_used" 106 "not_used" 107 "not_used" 108 "not_used" 109 "not_used" 110 "not_used" 111 "not_used" 112 "not_used" 113 "not_used" 114 "not_used" 115 "not_used" 116 "not_used" 117 "not_used" 118 "not_used" 119 "not_used" 120 "not_used" 121 "not_used" 122 "not_used" 123 "not_used" 124 "not_used" 125 "not_used" 126 "not_used" 127 "not_used" 128 "not_used" 129 "not_used" 130 "not_used" 131 "not_used" 132 "not_used" 133 "not_used" 134 "not_used" 135 "not_used" 136 "not_used" 137 "not_used" 138 "not_used" 139 "not_used" 140 "not_used" 141 "not_used" 142 "not_used" 143 "not_used" 144 "not_used" 145 "not_used" 146 "not_used" 147 "not_used" 148 "not_used" 149 "not_used" 150 "not_used" 151 "not_used" 152 "not_used" 153 "not_used" 154 "not_used" 155 "not_used" 156 "not_used" 157 "not_used" 158 "not_used" 159 "not_used" 160 "not_used" 161 "not_used" 162 "not_used" 163 "not_used" 164 "not_used" 165 "not_used" 166 "not_used" 167 "not_used" 168 "not_used" 169 "not_used" 170 "not_used" 171 "not_used" 172 "not_used" 173 "not_used" 174 "not_used" 175 "not_used" 176 "not_used" 177 "not_used" 178 "not_used" 179 "not_used" 180 "not_used" 181 "not_used" 182 "not_used" 183 "not_used" 184 "not_used" 185 "not_used" 186 "not_used" 187 "not_used" 188 "not_used" 189 "not_used" 190 "not_used" 191 "not_used" 192 "not_used" 193 "not_used" 194 "not_used" 195 "not_used" 196 "not_used" 197 "not_used" 198 "not_used" 199 "not_used" 200 "not_used" 201 "not_used" 202 "not_used" 203 "not_used" 204 "not_used" 205 "not_used" 206 "not_used" 207 "not_used" 208 "not_used" 209 "not_used" 210 "not_used" 211 "not_used" 212 "not_used" 213 "not_used" 214 "not_used" 215 "not_used" 216 "not_used" 217 "not_used" 218 "not_used" 219 "not_used" 220 "not_used" 221 "not_used" 222 "not_used" 223 "not_used" 224 "not_used" 225 "not_used" 226 "not_used" 227 "not_used" 228 "not_used" 229 "not_used" 230 "not_used" 231 "not_used" 232 "not_used" 233 "not_used" 234 "not_used" 235 "not_used" 236 "not_used" 237 "not_used" 238 "not_used" 239 "not_used" 240 "not_used" 241 "not_used" 242 "not_used" 243 "not_used" 244 "not_used" 245 "not_used" 246 "not_used" 247 "not_used" 248 "not_used" 249 "not_used" 250 "not_used" 251 "not_used" 252 "not_used" 253 "not_used" 254 "not_used" 255 "not_used" ;
VAL_ 1486 LongParkingSts 0 "Not_Active" 1 "Active" ;
VAL_ 1486 LongParkingFeedback 0 "OFF" 1 "ON" 2 "not_used" 3 "INIT" ;
VAL_ 1486 RechargeSts 0 "Charging" 1 "Not_charging" ;
VAL_ 1486 HVBRemainingAutonomy 255 "Condition_mismatch" ;
VAL_ 1486 HVBBuzzerReq 0 "Not_Active" 1 "Active" ;
VAL_ 1486 HVBFailSts 0 "No_One_Fault_is_Present" 1 "Fault_Present" ;
VAL_ 1486 HVB_ContactorSts 0 "Contactor_closed" 1 "Contactor_opened" ;
VAL_ 1486 HybridSystemFailSts 0 "Fail_Not_Present" 1 "Fail_Present" ;
VAL_ 1504 EngineOilPressureValidData 0 "Valid" 1 "Not_Valid" ;
VAL_ 1504 EngineOilTemperatureValidData 0 "Valid" 1 "Not_Valid" ;
VAL_ 1504 FuelFlapSts 0 "Closed" 1 "Opened" ;
VAL_ 1504 LowBeamSts 0 "OFF" 1 "ON" ;
VAL_ 1504 FuelButtonSts 0 "Not_Pressed" 1 "Pressed" ;
VAL_ 1504 CapoteSts 0 "Closed" 1 "Opened" 2 "Closing" 3 "Opening" 4 "Middle" 5 "Not_used" 6 "Not_used" 7 "Not_used" ;
VAL_ 1504 EngineOilTemperature 0 "FaultValue" ;
VAL_ 1504 FoldMirrorSts 0 "Unfolded" 1 "Folded" ;
VAL_ 1504 WalkAwayEnabled 0 "Disable" 1 "Enable" ;
VAL_ 1504 ElectricSteeringLamp_FailSts 0 "OFF_Fail_not_present" 1 "OFF_Fail_present" 2 "ON_Fail_not_present" 3 "Not_used" ;
VAL_ 1504 NAMEnable 0 "Enabled" 1 "Not_Enabled" ;
VAL_ 1504 InternalLightLevel 0 "Level_1" 1 "Level_2" 2 "Level_3" 3 "Level_4" 4 "Level_5" 5 "Level_6" 6 "Level_7" 7 "Level_8" 8 "Level_9" 9 "Level_10" 10 "Level_11" 11 "Level_12" 12 "Level_13" 13 "Level_14" 14 "Level_15" 15 "Level_16" ;
VAL_ 1504 NightDaySts 0 "Night" 1 "Day" ;
VAL_ 1504 LongParkingSetting 0 "OFF" 1 "ON" 2 "not_used" 3 "INIT" ;
VAL_ 1504 AVHDriverDoorSts 0 "Closed" 1 "Open" ;
VAL_ 1504 Alcohol_Interlock_Inhibit 0 "Not_active" 1 "Active" ;
VAL_ 1504 TrunkFailSts 0 "Fail_Not_Present" 1 "Fail_Present" ;
VAL_ 1504 EngineBonnetSts_LH 0 "Closed" 1 "Open" ;
VAL_ 1504 RechargeFlapSts 0 "Closed" 1 "Open" ;
VAL_ 1504 InternalLightSts 0 "Not_active" 1 "Active" ;
VAL_ 1728 RearWheelCircumference 112 "Not_Programmed" ;
VAL_ 1728 DISABLE_SSV 0 "Enable_SSV_on_NSV_module" 1 "DISABLE_SSV_on_NSV_module" ;
VAL_ 1728 ENABLE_SAA 0 "DISABLE_SAA_on_NSV_module" 1 "Enable_SAA_on_NSV_module" ;
VAL_ 1728 BatteryType 0 "IBS_not_present" 1 "Reserved" 2 "Reserved" 3 "Reserved" 4 "Reserved" 5 "Reserved" 6 "Reserved" 7 "Reserved" 8 "Reserved" 9 "A123_60Ah" 10 "Odissey_70_Ah" 11 "Odissey_95_Ah" 12 "FIAMM_80_Ah" 13 "FIAMM_95_Ah" 14 "FIAMM_70_Ah" 15 "ERROR" ;
VAL_ 1728 NCMSoftwareVariant 0 "Not_Programmed" 1 "europe" 2 "japan" 3 "taiwan" 4 "russia" 5 "usa" 6 "korea" 7 "China" ;
VAL_ 1728 Vehicle_Type 0 "Invalid" 1 "F142M" 2 "F151M_v12" 3 "F151M_v8" 4 "F152M" 5 "F164" 6 "F176" 7 "F173" 8 "F169" 9 "F171" 10 "F152MVS" 11 "F175" 12 "F167" 13 "_" 14 "_" 15 "_" ;
VAL_ 1728 EOL_CruiseControl 0 "Absent" 1 "Present" ;
VAL_ 1728 Rear_Doors 0 "Absent" 1 "Present" ;
VAL_ 1728 STOPANDSTART 0 "Absent" 1 "Present" ;
VAL_ 1728 TrafficType 0 "On_the_Right_Not_Programmed" 1 "On_the_Left" ;
VAL_ 1728 Vehicle_Variant 0 "invalid" 1 "Coupè" 2 "Spider" 3 "Special_Coupè" 4 "Special_Spider" 5 "Challenge" 6 "XX" 7 "OneOff" 8 "_" 9 "_" 10 "_" 11 "_" 12 "_" 13 "_" 14 "_" 15 "_" ;
VAL_ 1728 Adaptive_Cruise_Control 0 "Not_present_in_this_config" 1 "Is_present_in_this_configuration" ;
VAL_ 1728 Forward_Collision_Mitigation 0 "Not_present_in_this_config" 1 "Is_present_in_this_configuration" ;
VAL_ 1728 Node_19_NSV 0 "Not_present_in_this_config" 1 "Is_present_in_this_configuration" ;
VAL_ 1728 EOL_PlockLimiter 0 "Disable" 1 "Enable" ;
VAL_ 1728 Engine_Fan_Management 0 "NCM" 1 "NBC" ;
VAL_ 1728 PowerUnit 0 "Hybrid" 1 "Thermic" ;
VAL_ 1744 TSAMainSign2Enable 0 "Init" 1 "Not_Enable" 2 "Enable" 3 "not_used" ;
VAL_ 1744 TSASignChangeEnable 0 "Init" 1 "Not_Enable" 2 "Enable" 3 "not_used" ;
VAL_ 1744 TSAEnable 0 "Init" 1 "OFF" 2 "VisualWarning" 3 "Visual_AcousticWarning" ;
VAL_ 1744 DMS_Enable 0 "Init" 1 "Not_Enable" 2 "Enable" 3 "not_used" ;
VAL_ 1852 ACC_Dist_fbk 0 "No_Setting" 1 "D1" 2 "D2" 3 "D3" 4 "D4" 5 "INIT" 6 "not_used" 7 "not_used" ;
VAL_ 1852 ACCFailReversibleSts 0 "No_ACC_Fail" 1 "ACC_Reversible_Fail" 2 "ACC_Irreversible_Fail" 3 "Not_used" ;
VAL_ 1852 DASMTemporaryFailSts 0 "Fail_not_present" 1 "Fail_Present" ;
VAL_ 1852 DASMFailSts 0 "Fail_not_present" 1 "Fail_Present" ;
VAL_ 1852 RadarBlinded 0 "Fail_not_present" 1 "Fail_Present" ;
VAL_ 1852 FCWSystemSts 0 "Off" 1 "On_Only_Warning" 2 "On_Only_Braking" 3 "On_Full" ;
VAL_ 1852 ACC_DrivingMode_fbk 0 "Comfort" 1 "Sport" ;
VAL_ 1852 FCWSts 0 "Off" 1 "Sound" 2 "Sound_Brake" 3 "Brake" ;
VAL_ 1852 HMICode_FCW 0 "Idle" 1 "Pre_Intervention_warning" 2 "Intervention_warning" 3 "Not_Available_warning_type1" 4 "Not_Available_warning_4WD_Low" 5 "Post_Intervention_warning" 6 "Not_used" 7 "Not_used" 8 "Not_used" 9 "Not_used" 10 "Not_used" 11 "Not_used" 12 "Not_used" 13 "Not_used" 14 "Not_used" 15 "Not_used" 16 "Not_used" 17 "Not_used" 18 "Not_used" 19 "Not_used" 20 "Not_used" 21 "Not_used" 22 "Not_used" 23 "Not_used" 24 "Not_used" 25 "Not_used" 26 "Not_used" 27 "Not_used" 28 "Not_used" 29 "Not_used" 30 "Not_used" 31 "Not_used" 32 "Not_used" 33 "Not_used" 34 "Not_used" 35 "Not_used" 36 "Not_used" 37 "Not_used" 38 "Not_used" 39 "Not_used" 40 "Not_used" 41 "Not_used" 42 "Not_used" 43 "Not_used" 44 "Not_used" 45 "Not_used" 46 "Not_used" 47 "Not_used" 48 "Not_used" 49 "Not_used" 50 "Not_used" 51 "Not_used" 52 "Not_used" 53 "Not_used" 54 "Not_used" 55 "Not_used" 56 "Not_used" 57 "Not_used" 58 "Not_used" 59 "Not_used" 60 "Not_used" 61 "Not_used" 62 "Not_used" 63 "Not_used" ;
VAL_ 1852 CameraBlinded 0 "Fail_not_present" 1 "Fail_Present" ;
VAL_ 1852 CameraFailure 0 "Fail_not_present" 1 "Fail_Present" ;
VAL_ 1852 ACC_SetSpeedKPH 255 "SNA" ;
VAL_ 1852 ACC_SetSpeedMPH 255 "SNA" ;
VAL_ 1852 HMICode_ACC 0 "No_CODE" 1 "ACC_USER_DISABLED" 2 "ACC_USER_ENABLED_D1" 3 "ACC_USER_ENABLED_D2" 4 "ACC_USER_ENABLED_D3" 5 "ACC_USER_ENABLED_D4" 6 "ACC_SET_D1_TARGET" 7 "ACC_SET_D2_TARGET" 8 "ACC_SET_D3_TARGET" 9 "ACC_SET_D4_TARGET" 10 "ACC_SET_D1_NO_TARGET" 11 "ACC_SET_D2_NO_TARGET" 12 "ACC_SET_D3_NO_TARGET" 13 "ACC_SET_D4_NO_TARGET" 14 "ACC_CANCEL" 15 "ACC_CANCEL_D1" 16 "ACC_CANCEL_D2" 17 "ACC_CANCEL_D3" 18 "ACC_CANCEL_D4" 19 "ACC_CANCEL_SHIFT_D" 20 "ACC_CANCEL_BACKWARD" 21 "ACC_CANCEL_ESC_EVENT" 22 "ACC_CANCEL_HIGH_RPM" 23 "ACC_CANCEL_CHIME" 24 "ACC_CANCEL_EPB_ACTIVE" 25 "ACC_CANCEL_BELT" 26 "ACC_CANCEL_LIFTER_ON" 27 "ACC_UNAVAILABLE" 28 "ACC_UNAVAILABLE_BRAKE_APPLIED" 29 "ACC_UNAVAILABLE_BELT" 30 "ACC_UNAVAILABLE_OBST_DETECTED" 31 "ACC_UNAVAILABLE_ABOVE_MAX_SPEED" 32 "ACC_UNAVAILABLE_EPB_ACTIVE" 33 "ACC_UNAVAILABLE_ESC_EVENT" 34 "ACC_UNAVAILABLE_DRIVE_MODE" 35 "ACC_UNAVAILABLE_BACKWARD" 36 "ACC_UNAVAILABLE_SHIFT_D" 37 "ACC_UNAVAILABLE_LIFTER_ON" 38 "ACC_STOP_GO_AUTO_DRIVE_OFF" 39 "ACC_STOP_GO_RESUME_NEEDED" 40 "ACC_PROX_WARNING" 41 "ACC_OVERRIDE" 42 "ACC_UNAVAILABLE_BRAKES_COOLING" 43 "ACC_CANC_BRAKE_COOLING" 44 "ACC_OVERTAKE_INIBITHION" 45 "ACC_CANC_ROAD_TOO_STEEP" 46 "ACC_UNAVAILABLE_ROAD_TOO_STEEP" 47 "ACC_UNAVAILABLE_DOOR_OPEN" 48 "ACC_CANC_DOOR_OPEN" 49 "ACC_FRONT_RADAR_SENSOR_PLANTMODE" 50 "ACC_UNAVAILABLE_LOW_RPM" 51 "ACC_UNAVAILABLE_HIGH_RPM" 52 "ACC_CAMERA_FAIL" 53 "ACC_CAMERA_BLINDED" 54 "ACC_MAX_SPEED_EDRIVE_BELOW" 55 "ACC_MAX_SPEED_EDRIVE_ABOVE" 56 "ACC_DRIVEOFF_WNG_OPTICAL" 57 "ACC_DRIVEOFF_WNG_OPTICAL_ACL_1" 58 "ACC_DRIVEOFF_WNG_OPTICAL_ACL_2" 59 "ACC_HDC_Active" 60 "ACC_MAX_SPEED_ECO_BELOW" 61 "ACC_MAX_SPEED_ECO_ABOVE" 62 "ACC_MAX_SPEED_STD_BELOW" 63 "ACC_MAX_SPEED_STD_ABOVE" 64 "ACC_MAX_SPEED_PERF_BELOW" 65 "ACC_MAX_SPEED_PERF_ABOVE" 66 "ACC_LONG_PRESS_TO_ENA_NEEDED" 67 "Not_used" 68 "Not_used" 69 "Not_used" 70 "Not_used" 71 "Not_used" 72 "Not_used" 73 "Not_used" 74 "Not_used" 75 "Not_used" 76 "Not_used" 77 "Not_used" 78 "Not_used" 79 "Not_used" 80 "Not_used" 81 "Not_used" 82 "Not_used" 83 "Not_used" 84 "Not_used" 85 "Not_used" 86 "Not_used" 87 "Not_used" 88 "Not_used" 89 "Not_used" 90 "Not_used" 91 "Not_used" 92 "Not_used" 93 "Not_used" 94 "Not_used" 95 "Not_used" 96 "Not_used" 97 "Not_used" 98 "Not_used" 99 "Not_used" 100 "Not_used" 101 "Not_used" 102 "Not_used" 103 "Not_used" 104 "Not_used" 105 "Not_used" 106 "Not_used" 107 "Not_used" 108 "Not_used" 109 "Not_used" 110 "Not_used" 111 "Not_used" 112 "Not_used" 113 "Not_used" 114 "Not_used" 115 "Not_used" 116 "Not_used" 117 "Not_used" 118 "Not_used" 119 "Not_used" 120 "Not_used" 121 "Not_used" 122 "Not_used" 123 "Not_used" 124 "Not_used" 125 "Not_used" 126 "Not_used" 127 "Not_used" 128 "Not_used" 129 "Not_used" 130 "Not_used" 131 "Not_used" 132 "Not_used" 133 "Not_used" 134 "Not_used" 135 "Not_used" 136 "Not_used" 137 "Not_used" 138 "Not_used" 139 "Not_used" 140 "Not_used" 141 "Not_used" 142 "Not_used" 143 "Not_used" 144 "Not_used" 145 "Not_used" 146 "Not_used" 147 "Not_used" 148 "Not_used" 149 "Not_used" 150 "Not_used" 151 "Not_used" 152 "Not_used" 153 "Not_used" 154 "Not_used" 155 "Not_used" 156 "Not_used" 157 "Not_used" 158 "Not_used" 159 "Not_used" 160 "Not_used" 161 "Not_used" 162 "Not_used" 163 "Not_used" 164 "Not_used" 165 "Not_used" 166 "Not_used" 167 "Not_used" 168 "Not_used" 169 "Not_used" 170 "Not_used" 171 "Not_used" 172 "Not_used" 173 "Not_used" 174 "Not_used" 175 "Not_used" 176 "Not_used" 177 "Not_used" 178 "Not_used" 179 "Not_used" 180 "Not_used" 181 "Not_used" 182 "Not_used" 183 "Not_used" 184 "Not_used" 185 "Not_used" 186 "Not_used" 187 "Not_used" 188 "Not_used" 189 "Not_used" 190 "Not_used" 191 "Not_used" 192 "Not_used" 193 "Not_used" 194 "Not_used" 195 "Not_used" 196 "Not_used" 197 "Not_used" 198 "Not_used" 199 "Not_used" 200 "Not_used" 201 "Not_used" 202 "Not_used" 203 "Not_used" 204 "Not_used" 205 "Not_used" 206 "Not_used" 207 "Not_used" 208 "Not_used" 209 "Not_used" 210 "Not_used" 211 "Not_used" 212 "Not_used" 213 "Not_used" 214 "Not_used" 215 "Not_used" 216 "Not_used" 217 "Not_used" 218 "Not_used" 219 "Not_used" 220 "Not_used" 221 "Not_used" 222 "Not_used" 223 "Not_used" 224 "Not_used" 225 "Not_used" 226 "Not_used" 227 "Not_used" 228 "Not_used" 229 "Not_used" 230 "Not_used" 231 "Not_used" 232 "Not_used" 233 "Not_used" 234 "Not_used" 235 "Not_used" 236 "Not_used" 237 "Not_used" 238 "Not_used" 239 "Not_used" 240 "Not_used" 241 "Not_used" 242 "Not_used" 243 "Not_used" 244 "Not_used" 245 "Not_used" 246 "Not_used" 247 "Not_used" 248 "Not_used" 249 "Not_used" 250 "Not_used" 251 "Not_used" 252 "Not_used" 253 "Not_used" 254 "Not_used" 255 "Not_used" ;
VAL_ 1852 ACCFailSts 0 "Fail_not_present" 1 "Fail_Present" ;
VAL_ 1852 HMIDisplay_ACC 0 "No_Code" 1 "ACC_USER_DISABLED" 2 "ACC_USER_ENABLED_D1" 3 "ACC_USER_ENABLED_D2" 4 "ACC_USER_ENABLED_D3" 5 "ACC_USER_ENABLED_D4" 6 "ACC_SET_D1_TARGET" 7 "ACC_SET_D2_TARGET" 8 "ACC_SET_D3_TARGET" 9 "ACC_SET_D4_TARGET" 10 "ACC_SET_D1_NO_TARGET" 11 "ACC_SET_D2_NO_TARGET" 12 "ACC_SET_D3_NO_TARGET" 13 "ACC_SET_D4_NO_TARGET" 14 "ACC_CANCEL_D1" 15 "ACC_CANCEL_D2" 16 "ACC_CANCEL_D3" 17 "ACC_CANCEL_D4" 18 "ACC_CANCEL" 19 "ACC_ENABLED" 20 "ACC_SET" 21 "ACC_RESUME" 22 "ACC_OVERRIDE" 23 "ACC_OVERRIDE_D1" 24 "ACC_OVERRIDE_D2" 25 "ACC_OVERRIDE_D3" 26 "ACC_OVERRIDE_D4" 27 "NCC_CANCEL" 28 "NCC_USER_ENABLED" 29 "NCC_SET" 30 "NCC_RESUME" 31 "NCC_USER_DISABLED" 32 "NCC_OVERRIDE" 33 "ACC_UNAVAILABLE_HDC" 34 "Not_used" 35 "Not_used" 36 "Not_used" 37 "Not_used" 38 "Not_used" 39 "Not_used" 40 "Not_used" 41 "Not_used" 42 "Not_used" 43 "Not_used" 44 "Not_used" 45 "Not_used" 46 "Not_used" 47 "Not_used" 48 "Not_used" 49 "Not_used" 50 "Not_used" 51 "Not_used" 52 "Not_used" 53 "Not_used" 54 "Not_used" 55 "Not_used" 56 "Not_used" 57 "Not_used" 58 "Not_used" 59 "Not_used" 60 "Not_used" 61 "Not_used" 62 "Not_used" 63 "Not_used" ;
VAL_ 1852 FCWSensibilitySts 0 "Near" 1 "Med" 2 "Far" 3 "INIT" ;
VAL_ 1852 ACC_RadarBlinded 0 "Fail_not_present" 1 "Fail_Present" ;
VAL_ 1852 ACCSystemSts 0 "OFF" 1 "Enabled" 2 "Engaged" 3 "Engaged_BrakeOnly" 4 "Override" 5 "Cancel" 6 "Not_used" 7 "Not_used" ;
VAL_ 1853 ACC_TargetDistance 0 "_0" 1 "_1" 2 "_2" 3 "_3" 4 "_4" 5 "_5" 6 "_6" 7 "_7" 8 "_8" 9 "_9" 10 "_10" 11 "_11" 12 "_12" 13 "_13" 14 "_14" 15 "_15" 16 "_16" 17 "_17" 18 "_18" 19 "_19" 20 "_20" 21 "_21" 22 "_22" 23 "_23" 24 "_24" 25 "_25" 26 "_26" 27 "_27" 28 "_28" 29 "_29" 30 "_30" 31 "_31" 32 "_32" 33 "_33" 34 "_34" 35 "_35" 36 "_36" 37 "_37" 38 "_38" 39 "_39" 40 "_40" 41 "_41" 42 "_42" 43 "_43" 44 "_44" 45 "_45" 46 "_46" 47 "_47" 48 "_48" 49 "_49" 50 "_50" 51 "_51" 52 "_52" 53 "_53" 54 "_54" 55 "_55" 56 "_56" 57 "_57" 58 "_58" 59 "_59" 60 "_60" 61 "_61" 62 "_62" 63 "_63" 64 "_64" 65 "_65" 66 "_66" 67 "_67" 68 "_68" 69 "_69" 70 "_70" 71 "_71" 72 "_72" 73 "_73" 74 "_74" 75 "_75" 76 "_76" 77 "_77" 78 "_78" 79 "_79" 80 "_80" 81 "_81" 82 "_82" 83 "_83" 84 "_84" 85 "_85" 86 "_86" 87 "_87" 88 "_88" 89 "_89" 90 "_90" 91 "_91" 92 "_92" 93 "_93" 94 "_94" 95 "_95" 96 "_96" 97 "_97" 98 "_98" 99 "_99" 100 "_100" 101 "_101" 102 "_102" 103 "_103" 104 "_104" 105 "_105" 106 "_106" 107 "_107" 108 "_108" 109 "_109" 110 "_110" 111 "_111" 112 "_112" 113 "_113" 114 "_114" 115 "_115" 116 "_116" 117 "_117" 118 "_118" 119 "_119" 120 "_120" 121 "_121" 122 "_122" 123 "_123" 124 "_124" 125 "_125" 126 "_126" 127 "_127" 128 "_128" 129 "_129" 130 "_130" 131 "_131" 132 "_132" 133 "_133" 134 "_134" 135 "_135" 136 "_136" 137 "_137" 138 "_138" 139 "_139" 140 "_140" 141 "_141" 142 "_142" 143 "_143" 144 "_144" 145 "_145" 146 "_146" 147 "_147" 148 "_148" 149 "_149" 150 "_150" 151 "_151" 152 "_152" 153 "_153" 154 "_154" 155 "_155" 156 "_156" 157 "_157" 158 "_158" 159 "_159" 160 "_160" 161 "_161" 162 "_162" 163 "_163" 164 "_164" 165 "_165" 166 "_166" 167 "_167" 168 "_168" 169 "_169" 170 "_170" 171 "_171" 172 "_172" 173 "_173" 174 "_174" 175 "_175" 176 "_176" 177 "_177" 178 "_178" 179 "_179" 180 "_180" 181 "_181" 182 "_182" 183 "_183" 184 "_184" 185 "_185" 186 "_186" 187 "_187" 188 "_188" 189 "_189" 190 "_190" 191 "_191" 192 "_192" 193 "_193" 194 "_194" 195 "_195" 196 "_196" 197 "_197" 198 "_198" 199 "_199" 200 "_200" 201 "_201" 202 "_202" 203 "_203" 204 "_204" 205 "_205" 206 "_206" 207 "_207" 208 "_208" 209 "_209" 210 "_210" 211 "_211" 212 "_212" 213 "_213" 214 "_214" 215 "_215" 216 "_216" 217 "_217" 218 "_218" 219 "_219" 220 "_220" 221 "_221" 222 "_222" 223 "_223" 224 "_224" 225 "_225" 226 "_226" 227 "_227" 228 "_228" 229 "_229" 230 "_230" 231 "_231" 232 "_232" 233 "_233" 234 "_234" 235 "_235" 236 "_236" 237 "_237" 238 "_238" 239 "_239" 240 "_240" 241 "_241" 242 "_242" 243 "_243" 244 "_244" 245 "_245" 246 "_246" 247 "_247" 248 "_248" 249 "_249" 250 "_250" 251 "_251" 252 "_252" 253 "_253" 254 "_254" 255 "_255" 256 "_256" 257 "_257" 258 "_258" 259 "_259" 260 "_260" 261 "_261" 262 "_262" 263 "_263" 264 "_264" 265 "_265" 266 "_266" 267 "_267" 268 "_268" 269 "_269" 270 "_270" 271 "_271" 272 "_272" 273 "_273" 274 "_274" 275 "_275" 276 "_276" 277 "_277" 278 "_278" 279 "_279" 280 "_280" 281 "_281" 282 "_282" 283 "_283" 284 "_284" 285 "_285" 286 "_286" 287 "_287" 288 "_288" 289 "_289" 290 "_290" 291 "_291" 292 "_292" 293 "_293" 294 "_294" 295 "_295" 296 "_296" 297 "_297" 298 "_298" 299 "_299" 300 "_300" 301 "not_used" 302 "not_used" 303 "not_used" 304 "not_used" 305 "not_used" 306 "not_used" 307 "not_used" 308 "not_used" 309 "not_used" 310 "not_used" 311 "not_used" 312 "not_used" 313 "not_used" 314 "not_used" 315 "not_used" 316 "not_used" 317 "not_used" 318 "not_used" 319 "not_used" 320 "not_used" 321 "not_used" 322 "not_used" 323 "not_used" 324 "not_used" 325 "not_used" 326 "not_used" 327 "not_used" 328 "not_used" 329 "not_used" 330 "not_used" 331 "not_used" 332 "not_used" 333 "not_used" 334 "not_used" 335 "not_used" 336 "not_used" 337 "not_used" 338 "not_used" 339 "not_used" 340 "not_used" 341 "not_used" 342 "not_used" 343 "not_used" 344 "not_used" 345 "not_used" 346 "not_used" 347 "not_used" 348 "not_used" 349 "not_used" 350 "not_used" 351 "not_used" 352 "not_used" 353 "not_used" 354 "not_used" 355 "not_used" 356 "not_used" 357 "not_used" 358 "not_used" 359 "not_used" 360 "not_used" 361 "not_used" 362 "not_used" 363 "not_used" 364 "not_used" 365 "not_used" 366 "not_used" 367 "not_used" 368 "not_used" 369 "not_used" 370 "not_used" 371 "not_used" 372 "not_used" 373 "not_used" 374 "not_used" 375 "not_used" 376 "not_used" 377 "not_used" 378 "not_used" 379 "not_used" 380 "not_used" 381 "not_used" 382 "not_used" 383 "not_used" 384 "not_used" 385 "not_used" 386 "not_used" 387 "not_used" 388 "not_used" 389 "not_used" 390 "not_used" 391 "not_used" 392 "not_used" 393 "not_used" 394 "not_used" 395 "not_used" 396 "not_used" 397 "not_used" 398 "not_used" 399 "not_used" 400 "not_used" 401 "not_used" 402 "not_used" 403 "not_used" 404 "not_used" 405 "not_used" 406 "not_used" 407 "not_used" 408 "not_used" 409 "not_used" 410 "not_used" 411 "not_used" 412 "not_used" 413 "not_used" 414 "not_used" 415 "not_used" 416 "not_used" 417 "not_used" 418 "not_used" 419 "not_used" 420 "not_used" 421 "not_used" 422 "not_used" 423 "not_used" 424 "not_used" 425 "not_used" 426 "not_used" 427 "not_used" 428 "not_used" 429 "not_used" 430 "not_used" 431 "not_used" 432 "not_used" 433 "not_used" 434 "not_used" 435 "not_used" 436 "not_used" 437 "not_used" 438 "not_used" 439 "not_used" 440 "not_used" 441 "not_used" 442 "not_used" 443 "not_used" 444 "not_used" 445 "not_used" 446 "not_used" 447 "not_used" 448 "not_used" 449 "not_used" 450 "not_used" 451 "not_used" 452 "not_used" 453 "not_used" 454 "not_used" 455 "not_used" 456 "not_used" 457 "not_used" 458 "not_used" 459 "not_used" 460 "not_used" 461 "not_used" 462 "not_used" 463 "not_used" 464 "not_used" 465 "not_used" 466 "not_used" 467 "not_used" 468 "not_used" 469 "not_used" 470 "not_used" 471 "not_used" 472 "not_used" 473 "not_used" 474 "not_used" 475 "not_used" 476 "not_used" 477 "not_used" 478 "not_used" 479 "not_used" 480 "not_used" 481 "not_used" 482 "not_used" 483 "not_used" 484 "not_used" 485 "not_used" 486 "not_used" 487 "not_used" 488 "not_used" 489 "not_used" 490 "not_used" 491 "not_used" 492 "not_used" 493 "not_used" 494 "not_used" 495 "not_used" 496 "not_used" 497 "not_used" 498 "not_used" 499 "not_used" 500 "not_used" 501 "not_used" 502 "not_used" 503 "not_used" 504 "not_used" 505 "not_used" 506 "not_used" 507 "not_used" 508 "not_used" 509 "not_used" 510 "Not_Valid" 511 "Target_not_found" ;
VAL_ 1853 ACC_DesiredDistance 0 "_0" 1 "_1" 2 "_2" 3 "_3" 4 "_4" 5 "_5" 6 "_6" 7 "_7" 8 "_8" 9 "_9" 10 "_10" 11 "_11" 12 "_12" 13 "_13" 14 "_14" 15 "_15" 16 "_16" 17 "_17" 18 "_18" 19 "_19" 20 "_20" 21 "_21" 22 "_22" 23 "_23" 24 "_24" 25 "_25" 26 "_26" 27 "_27" 28 "_28" 29 "_29" 30 "_30" 31 "_31" 32 "_32" 33 "_33" 34 "_34" 35 "_35" 36 "_36" 37 "_37" 38 "_38" 39 "_39" 40 "_40" 41 "_41" 42 "_42" 43 "_43" 44 "_44" 45 "_45" 46 "_46" 47 "_47" 48 "_48" 49 "_49" 50 "_50" 51 "_51" 52 "_52" 53 "_53" 54 "_54" 55 "_55" 56 "_56" 57 "_57" 58 "_58" 59 "_59" 60 "_60" 61 "_61" 62 "_62" 63 "_63" 64 "_64" 65 "_65" 66 "_66" 67 "_67" 68 "_68" 69 "_69" 70 "_70" 71 "_71" 72 "_72" 73 "_73" 74 "_74" 75 "_75" 76 "_76" 77 "_77" 78 "_78" 79 "_79" 80 "_80" 81 "_81" 82 "_82" 83 "_83" 84 "_84" 85 "_85" 86 "_86" 87 "_87" 88 "_88" 89 "_89" 90 "_90" 91 "_91" 92 "_92" 93 "_93" 94 "_94" 95 "_95" 96 "_96" 97 "_97" 98 "_98" 99 "_99" 100 "_100" 101 "_101" 102 "_102" 103 "_103" 104 "_104" 105 "_105" 106 "_106" 107 "_107" 108 "_108" 109 "_109" 110 "_110" 111 "_111" 112 "_112" 113 "_113" 114 "_114" 115 "_115" 116 "_116" 117 "_117" 118 "_118" 119 "_119" 120 "_120" 121 "_121" 122 "_122" 123 "_123" 124 "_124" 125 "Not_used" 126 "Not_used" 127 "No_desired_Distance" ;
VAL_ 1853 ACC_TargetRelativeVelocity 1022 "Not_Valid" 1023 "Target_not_found" ;
VAL_ 1853 ACC_LateralTarget 0 "None" 1 "Cut_In_From_Left" 2 "Cut_In_From_Right" 3 "Cut_Out_To_Left" 4 "Cut_Out_To_Right" 5 "Approaching" 6 "Leaving" 7 "Cut_In_From_Left_add" 8 "Cut_In_From_Right_add" 9 "Cut_Out_To_Left_add" 10 "Cut_Out_To_Right_add" 11 "Not_used" 12 "Not_used" 13 "Not_used" 14 "Not_used" 15 "SNA" ;
VAL_ 1955 EngineOilTemperature 0 "FaultValue" ;
VAL_ 1955 WiperWaterLevelLampSts 0 "Not_Active" 1 "Active" ;
VAL_ 1955 PowerSteeringFailLampSts 0 "Not_Active" 1 "Active" ;
VAL_ 1955 EngineOilPressureValidData 0 "Valid" 1 "Not_Valid" ;
VAL_ 1955 EngineOilTemperatureValidData 0 "Valid" 1 "Not_Valid" ;
VAL_ 1955 WCM_Status 0 "READY_TO_CHARGE" 1 "BASIC_POWER_PROFILE_CHARGE" 2 "EXTENDED_POWER_PROFILE_CHARGE" 3 "SAMSUNG_FAST_CHARGE" 4 "APPLE_FAST_CHARGE" 5 "CHARGE_COMPLETE" 6 "SCAN_FOR_RX" 7 "BATTERY_STAND_BY" 8 "FOB_STAND_BY" 9 "FOREIGN_OBJ_DETECT_ON_CHARGE" 10 "FOREIGN_OBJ_DETECT_Not_CHARGING" 11 "Not_used" 12 "Not_used" 13 "Not_used" 14 "Not_used" 15 "SYSTEM_ERROR" ;
VAL_ 1955 DistanceUnit 0 "Km" 1 "Miles" ;
VAL_ 1955 ElectricSteeringLamp_FailSts 0 "OFF_Fail_not_present" 1 "OFF_Fail_present" 2 "ON_Fail_not_present" 3 "Not_used" ;
VAL_ 1955 CameraButtonSts 0 "Not_Pressed" 1 "Pressed" ;
VAL_ 2443860262 SGW_Status 0 "Normal_Operation" 1 "Active_Firewall" 2 "FailPresent" ;
VAL_ 2443869696 Vin_MSG_MuxID_ 0 "DONGLE_INFO_Vin_MSG_MuxID__DynamicPart_0" 1 "DONGLE_INFO_Vin_MSG_MuxID__DynamicPart_1" 2 "DONGLE_INFO_Vin_MSG_MuxID__DynamicPart_2" 3 "DONGLE_INFO_Vin_MSG_MuxID__DynamicPart_3" 4 "DONGLE_INFO_Vin_MSG_MuxID__DynamicPart_4" 5 "DONGLE_INFO_Vin_MSG_MuxID__DynamicPart_5" 6 "DONGLE_INFO_Vin_MSG_MuxID__DynamicPart_6" ;
VAL_ 2443869696 SCENARIO_ 0 "Not_used" 1 "Plant_Test" 2 "Dealer_Test" 3 "Dealer_Service_Activation" ;
VAL_ 2443869696 Station_ 15 "Test_Passed" 255 "Soft_SIM_Deactivation" ;
VAL_ 2443869696 TestResult 0 "Test_Ongoing" ;
VAL_ 2510974976 SG_DMS_DebugStatus 0 "Init" 1 "Calibration" 2 "Pause" 3 "Active" 4 "Running" 5 "Warning" 6 "Degraded" 7 "Error" 8 "Not_Used" 9 "Not_Used" 10 "Not_Used" 11 "Not_Used" 12 "Not_Used" 13 "Not_Used" 14 "Not_Used" 15 "Not_Used" ;
VAL_ 2654208000 WakeRsn_BCM 0 "'Diag'" 1 "'Network'" 2 "Trunk_Opening_Closing" 3 "Trunk_Movement_Request" 4 "Front_Bonnet_Closing" 5 "Fuel_Flap_Button_Activation" 6 "Recharge_Flap_Button_Activation" 7 "'WakeRsn7'" 8 "'WakeRsn8'" 9 "'WakeRsn9'" 10 "'WakeRsn10'" 11 "'WakeRsn11'" 12 "'WakeRsn12'" 13 "'WakeRsn13'" 14 "'WakeRsn14'" 15 "'WakeRsn15'" 16 "'WakeRsn16'" 17 "'WakeRsn17'" 18 "'WakeRsn18'" 19 "'WakeRsn19'" 20 "'WakeRsn20'" 21 "'WakeRsn21'" 22 "'WakeRsn22'" 23 "'WakeRsn23'" 24 "'WakeRsn24'" 25 "'WakeRsn25'" 26 "'WakeRsn26'" 27 "'WakeRsn27'" 28 "'WakeRsn28'" 29 "'WakeRsn29'" 30 "'WakeRsn30'" 31 "'WakeRsn31'" 32 "'WakeRsn32'" 33 "'WakeRsn33'" 34 "'WakeRsn34'" 35 "'WakeRsn35'" 36 "'WakeRsn36'" 37 "'WakeRsn37'" 38 "'WakeRsn38'" 39 "'WakeRsn39'" 40 "'WakeRsn40'" 41 "'WakeRsn41'" 42 "'WakeRsn42'" 43 "'WakeRsn43'" 44 "'WakeRsn44'" 45 "'WakeRsn45'" 46 "'WakeRsn46'" 47 "'WakeRsn47'" 48 "'WakeRsn48'" 49 "'WakeRsn49'" 50 "'WakeRsn50'" 51 "'WakeRsn51'" 52 "'WakeRsn52'" 53 "'WakeRsn53'" 54 "'WakeRsn54'" 55 "'WakeRsn55'" 56 "'WakeRsn56'" 57 "'WakeRsn57'" 58 "'WakeRsn58'" 59 "'WakeRsn59'" 60 "'WakeRsn60'" 61 "'WakeRsn61'" 62 "'WakeRsn62'" 63 "'WakeRsn63'" 64 "'WakeRsn64'" 65 "'WakeRsn65'" 66 "'WakeRsn66'" 67 "'WakeRsn67'" 68 "'WakeRsn68'" 69 "'WakeRsn69'" 70 "'WakeRsn70'" 71 "'WakeRsn71'" 72 "'WakeRsn72'" 73 "'WakeRsn73'" 74 "'WakeRsn74'" 75 "'WakeRsn75'" 76 "'WakeRsn76'" 77 "'WakeRsn77'" 78 "'WakeRsn78'" 79 "'WakeRsn79'" 80 "'WakeRsn80'" 81 "'WakeRsn81'" 82 "'WakeRsn82'" 83 "'WakeRsn83'" 84 "'WakeRsn84'" 85 "'WakeRsn85'" 86 "'WakeRsn86'" 87 "'WakeRsn87'" 88 "'WakeRsn88'" 89 "'WakeRsn89'" 90 "'WakeRsn90'" 91 "'WakeRsn91'" 92 "'WakeRsn92'" 93 "'WakeRsn93'" 94 "'WakeRsn94'" 95 "'WakeRsn95'" 96 "'WakeRsn96'" 97 "'WakeRsn97'" 98 "'WakeRsn98'" 99 "'WakeRsn99'" 100 "'WakeRsn100'" 101 "'WakeRsn101'" 102 "'WakeRsn102'" 103 "'WakeRsn103'" 104 "'WakeRsn104'" 105 "'WakeRsn105'" 106 "'WakeRsn106'" 107 "'WakeRsn107'" 108 "'WakeRsn108'" 109 "'WakeRsn109'" 110 "'WakeRsn110'" 111 "'WakeRsn111'" 112 "'WakeRsn112'" 113 "'WakeRsn113'" 114 "'WakeRsn114'" 115 "'WakeRsn115'" 116 "'WakeRsn116'" 117 "'WakeRsn117'" 118 "'WakeRsn118'" 119 "'WakeRsn119'" 120 "'WakeRsn120'" 121 "'WakeRsn121'" 122 "'WakeRsn122'" 123 "'WakeRsn123'" 124 "'WakeRsn124'" 125 "'WakeRsn125'" 126 "'WakeRsn126'" 127 "'WakeRsn127'" ;
VAL_ 2654208000 MainWakeSts_BCM 0 "'Not_Active'" 1 "'Active'" ;
VAL_ 2654208000 Node24 0 "'Not_active'" 1 "'Active'" ;
VAL_ 2654208000 Node25 0 "'Not_active'" 1 "'Active'" ;
VAL_ 2654208000 Node26 0 "'Not_active'" 1 "'Active'" ;
VAL_ 2654208000 Node27 0 "'Not_active'" 1 "'Active'" ;
VAL_ 2654208000 Node28 0 "'Not_active'" 1 "'Active'" ;
VAL_ 2654208000 Node29 0 "'Not_active'" 1 "'Active'" ;
VAL_ 2654208000 Node30 0 "'Not_active'" 1 "'Active'" ;
VAL_ 2654208000 Node31 0 "'Not_active'" 1 "'Active'" ;
VAL_ 2654208000 Node16 0 "'Not_active'" 1 "'Active'" ;
VAL_ 2654208000 Node17 0 "'Not_active'" 1 "'Active'" ;
VAL_ 2654208000 Node18 0 "'Not_active'" 1 "'Active'" ;
VAL_ 2654208000 Node19 0 "'Not_active'" 1 "'Active'" ;
VAL_ 2654208000 Node20 0 "'Not_active'" 1 "'Active'" ;
VAL_ 2654208000 Node21 0 "'Not_active'" 1 "'Active'" ;
VAL_ 2654208000 Node22 0 "'Not_active'" 1 "'Active'" ;
VAL_ 2654208000 Node23 0 "'Not_active'" 1 "'Active'" ;
VAL_ 2654208000 Node8 0 "'Not_active'" 1 "'Active'" ;
VAL_ 2654208000 Node9 0 "'Not_active'" 1 "'Active'" ;
VAL_ 2654208000 Node10 0 "'Not_active'" 1 "'Active'" ;
VAL_ 2654208000 Node11 0 "'Not_active'" 1 "'Active'" ;
VAL_ 2654208000 Node12 0 "'Not_active'" 1 "'Active'" ;
VAL_ 2654208000 Node13 0 "'Not_active'" 1 "'Active'" ;
VAL_ 2654208000 Node14 0 "'Not_active'" 1 "'Active'" ;
VAL_ 2654208000 Node15 0 "'Not_active'" 1 "'Active'" ;
VAL_ 2654208000 Node0 0 "'Not_active'" 1 "'Active'" ;
VAL_ 2654208000 Node1 0 "'Not_active'" 1 "'Active'" ;
VAL_ 2654208000 Node2 0 "'Not_active'" 1 "'Active'" ;
VAL_ 2654208000 Node3 0 "'Not_active'" 1 "'Active'" ;
VAL_ 2654208000 Node4 0 "'Not_active'" 1 "'Active'" ;
VAL_ 2654208000 Node5 0 "'Not_active'" 1 "'Active'" ;
VAL_ 2654208000 Node6 0 "'Not_active'" 1 "'Active'" ;
VAL_ 2654208000 Node7 0 "'Not_active'" 1 "'Active'" ;
VAL_ 2654208001 WakeRsn_NCM 0 "'Diag'" 1 "'Network'" 2 "'WakeRsn2'" 3 "'WakeRsn3'" 4 "'WakeRsn4'" 5 "'WakeRsn5'" 6 "'WakeRsn6'" 7 "'WakeRsn7'" 8 "'WakeRsn8'" 9 "'WakeRsn9'" 10 "'WakeRsn10'" 11 "'WakeRsn11'" 12 "'WakeRsn12'" 13 "'WakeRsn13'" 14 "'WakeRsn14'" 15 "'WakeRsn15'" 16 "'WakeRsn16'" 17 "'WakeRsn17'" 18 "'WakeRsn18'" 19 "'WakeRsn19'" 20 "'WakeRsn20'" 21 "'WakeRsn21'" 22 "'WakeRsn22'" 23 "'WakeRsn23'" 24 "'WakeRsn24'" 25 "'WakeRsn25'" 26 "'WakeRsn26'" 27 "'WakeRsn27'" 28 "'WakeRsn28'" 29 "'WakeRsn29'" 30 "'WakeRsn30'" 31 "'WakeRsn31'" 32 "'WakeRsn32'" 33 "'WakeRsn33'" 34 "'WakeRsn34'" 35 "'WakeRsn35'" 36 "'WakeRsn36'" 37 "'WakeRsn37'" 38 "'WakeRsn38'" 39 "'WakeRsn39'" 40 "'WakeRsn40'" 41 "'WakeRsn41'" 42 "'WakeRsn42'" 43 "'WakeRsn43'" 44 "'WakeRsn44'" 45 "'WakeRsn45'" 46 "'WakeRsn46'" 47 "'WakeRsn47'" 48 "'WakeRsn48'" 49 "'WakeRsn49'" 50 "'WakeRsn50'" 51 "'WakeRsn51'" 52 "'WakeRsn52'" 53 "'WakeRsn53'" 54 "'WakeRsn54'" 55 "'WakeRsn55'" 56 "'WakeRsn56'" 57 "'WakeRsn57'" 58 "'WakeRsn58'" 59 "'WakeRsn59'" 60 "'WakeRsn60'" 61 "'WakeRsn61'" 62 "'WakeRsn62'" 63 "'WakeRsn63'" 64 "'WakeRsn64'" 65 "'WakeRsn65'" 66 "'WakeRsn66'" 67 "'WakeRsn67'" 68 "'WakeRsn68'" 69 "'WakeRsn69'" 70 "'WakeRsn70'" 71 "'WakeRsn71'" 72 "'WakeRsn72'" 73 "'WakeRsn73'" 74 "'WakeRsn74'" 75 "'WakeRsn75'" 76 "'WakeRsn76'" 77 "'WakeRsn77'" 78 "'WakeRsn78'" 79 "'WakeRsn79'" 80 "'WakeRsn80'" 81 "'WakeRsn81'" 82 "'WakeRsn82'" 83 "'WakeRsn83'" 84 "'WakeRsn84'" 85 "'WakeRsn85'" 86 "'WakeRsn86'" 87 "'WakeRsn87'" 88 "'WakeRsn88'" 89 "'WakeRsn89'" 90 "'WakeRsn90'" 91 "'WakeRsn91'" 92 "'WakeRsn92'" 93 "'WakeRsn93'" 94 "'WakeRsn94'" 95 "'WakeRsn95'" 96 "'WakeRsn96'" 97 "'WakeRsn97'" 98 "'WakeRsn98'" 99 "'WakeRsn99'" 100 "'WakeRsn100'" 101 "'WakeRsn101'" 102 "'WakeRsn102'" 103 "'WakeRsn103'" 104 "'WakeRsn104'" 105 "'WakeRsn105'" 106 "'WakeRsn106'" 107 "'WakeRsn107'" 108 "'WakeRsn108'" 109 "'WakeRsn109'" 110 "'WakeRsn110'" 111 "'WakeRsn111'" 112 "'WakeRsn112'" 113 "'WakeRsn113'" 114 "'WakeRsn114'" 115 "'WakeRsn115'" 116 "'WakeRsn116'" 117 "'WakeRsn117'" 118 "'WakeRsn118'" 119 "'WakeRsn119'" 120 "'WakeRsn120'" 121 "'WakeRsn121'" 122 "'WakeRsn122'" 123 "'WakeRsn123'" 124 "'WakeRsn124'" 125 "'WakeRsn125'" 126 "'WakeRsn126'" 127 "'WakeRsn127'" ;
VAL_ 2654208001 WakeReq_NCM 0 "'NotActive'" 1 "'Active'" ;
VAL_ 2654208006 WakeRsn_NFR 0 "'Diag'" 1 "'Network'" 2 "EPB_PostRun" 3 "Speed" 4 "'WakeRsn4'" 5 "'WakeRsn5'" 6 "'WakeRsn6'" 7 "'WakeRsn7'" 8 "'WakeRsn8'" 9 "'WakeRsn9'" 10 "'WakeRsn10'" 11 "'WakeRsn11'" 12 "'WakeRsn12'" 13 "'WakeRsn13'" 14 "'WakeRsn14'" 15 "'WakeRsn15'" 16 "'WakeRsn16'" 17 "'WakeRsn17'" 18 "'WakeRsn18'" 19 "'WakeRsn19'" 20 "'WakeRsn20'" 21 "'WakeRsn21'" 22 "'WakeRsn22'" 23 "'WakeRsn23'" 24 "'WakeRsn24'" 25 "'WakeRsn25'" 26 "'WakeRsn26'" 27 "'WakeRsn27'" 28 "'WakeRsn28'" 29 "'WakeRsn29'" 30 "'WakeRsn30'" 31 "'WakeRsn31'" 32 "'WakeRsn32'" 33 "'WakeRsn33'" 34 "'WakeRsn34'" 35 "'WakeRsn35'" 36 "'WakeRsn36'" 37 "'WakeRsn37'" 38 "'WakeRsn38'" 39 "'WakeRsn39'" 40 "'WakeRsn40'" 41 "'WakeRsn41'" 42 "'WakeRsn42'" 43 "'WakeRsn43'" 44 "'WakeRsn44'" 45 "'WakeRsn45'" 46 "'WakeRsn46'" 47 "'WakeRsn47'" 48 "'WakeRsn48'" 49 "'WakeRsn49'" 50 "'WakeRsn50'" 51 "'WakeRsn51'" 52 "'WakeRsn52'" 53 "'WakeRsn53'" 54 "'WakeRsn54'" 55 "'WakeRsn55'" 56 "'WakeRsn56'" 57 "'WakeRsn57'" 58 "'WakeRsn58'" 59 "'WakeRsn59'" 60 "'WakeRsn60'" 61 "'WakeRsn61'" 62 "'WakeRsn62'" 63 "'WakeRsn63'" 64 "'WakeRsn64'" 65 "'WakeRsn65'" 66 "'WakeRsn66'" 67 "'WakeRsn67'" 68 "'WakeRsn68'" 69 "'WakeRsn69'" 70 "'WakeRsn70'" 71 "'WakeRsn71'" 72 "'WakeRsn72'" 73 "'WakeRsn73'" 74 "'WakeRsn74'" 75 "'WakeRsn75'" 76 "'WakeRsn76'" 77 "'WakeRsn77'" 78 "'WakeRsn78'" 79 "'WakeRsn79'" 80 "'WakeRsn80'" 81 "'WakeRsn81'" 82 "'WakeRsn82'" 83 "'WakeRsn83'" 84 "'WakeRsn84'" 85 "'WakeRsn85'" 86 "'WakeRsn86'" 87 "'WakeRsn87'" 88 "'WakeRsn88'" 89 "'WakeRsn89'" 90 "'WakeRsn90'" 91 "'WakeRsn91'" 92 "'WakeRsn92'" 93 "'WakeRsn93'" 94 "'WakeRsn94'" 95 "'WakeRsn95'" 96 "'WakeRsn96'" 97 "'WakeRsn97'" 98 "'WakeRsn98'" 99 "'WakeRsn99'" 100 "'WakeRsn100'" 101 "'WakeRsn101'" 102 "'WakeRsn102'" 103 "'WakeRsn103'" 104 "'WakeRsn104'" 105 "'WakeRsn105'" 106 "'WakeRsn106'" 107 "'WakeRsn107'" 108 "'WakeRsn108'" 109 "'WakeRsn109'" 110 "'WakeRsn110'" 111 "'WakeRsn111'" 112 "'WakeRsn112'" 113 "'WakeRsn113'" 114 "'WakeRsn114'" 115 "'WakeRsn115'" 116 "'WakeRsn116'" 117 "'WakeRsn117'" 118 "'WakeRsn118'" 119 "'WakeRsn119'" 120 "'WakeRsn120'" 121 "'WakeRsn121'" 122 "'WakeRsn122'" 123 "'WakeRsn123'" 124 "'WakeRsn124'" 125 "'WakeRsn125'" 126 "'WakeRsn126'" 127 "'WakeRsn127'" ;
VAL_ 2654208006 WakeReq_NFR 0 "'NotActive'" 1 "'Active'" ;
VAL_ 2654208014 WakeRsn_HVB 0 "'Diag'" 1 "'Network'" 2 "HVB_In_Charge" 3 "LVB_In_Charge" 4 "'High_DC_Voltage'" 5 "DMTL" 6 "'WakeRsn6'" 7 "'WakeRsn7'" 8 "'WakeRsn8'" 9 "'WakeRsn9'" 10 "'WakeRsn10'" 11 "'WakeRsn11'" 12 "'WakeRsn12'" 13 "'WakeRsn13'" 14 "'WakeRsn14'" 15 "'WakeRsn15'" 16 "'WakeRsn16'" 17 "'WakeRsn17'" 18 "'WakeRsn18'" 19 "'WakeRsn19'" 20 "'WakeRsn20'" 21 "'WakeRsn21'" 22 "'WakeRsn22'" 23 "'WakeRsn23'" 24 "'WakeRsn24'" 25 "'WakeRsn25'" 26 "'WakeRsn26'" 27 "'WakeRsn27'" 28 "'WakeRsn28'" 29 "'WakeRsn29'" 30 "'WakeRsn30'" 31 "'WakeRsn31'" 32 "'WakeRsn32'" 33 "'WakeRsn33'" 34 "'WakeRsn34'" 35 "'WakeRsn35'" 36 "'WakeRsn36'" 37 "'WakeRsn37'" 38 "'WakeRsn38'" 39 "'WakeRsn39'" 40 "'WakeRsn40'" 41 "'WakeRsn41'" 42 "'WakeRsn42'" 43 "'WakeRsn43'" 44 "'WakeRsn44'" 45 "'WakeRsn45'" 46 "'WakeRsn46'" 47 "'WakeRsn47'" 48 "'WakeRsn48'" 49 "'WakeRsn49'" 50 "'WakeRsn50'" 51 "'WakeRsn51'" 52 "'WakeRsn52'" 53 "'WakeRsn53'" 54 "'WakeRsn54'" 55 "'WakeRsn55'" 56 "'WakeRsn56'" 57 "'WakeRsn57'" 58 "'WakeRsn58'" 59 "'WakeRsn59'" 60 "'WakeRsn60'" 61 "'WakeRsn61'" 62 "'WakeRsn62'" 63 "'WakeRsn63'" 64 "'WakeRsn64'" 65 "'WakeRsn65'" 66 "'WakeRsn66'" 67 "'WakeRsn67'" 68 "'WakeRsn68'" 69 "'WakeRsn69'" 70 "'WakeRsn70'" 71 "'WakeRsn71'" 72 "'WakeRsn72'" 73 "'WakeRsn73'" 74 "'WakeRsn74'" 75 "'WakeRsn75'" 76 "'WakeRsn76'" 77 "'WakeRsn77'" 78 "'WakeRsn78'" 79 "'WakeRsn79'" 80 "'WakeRsn80'" 81 "'WakeRsn81'" 82 "'WakeRsn82'" 83 "'WakeRsn83'" 84 "'WakeRsn84'" 85 "'WakeRsn85'" 86 "'WakeRsn86'" 87 "'WakeRsn87'" 88 "'WakeRsn88'" 89 "'WakeRsn89'" 90 "'WakeRsn90'" 91 "'WakeRsn91'" 92 "'WakeRsn92'" 93 "'WakeRsn93'" 94 "'WakeRsn94'" 95 "'WakeRsn95'" 96 "'WakeRsn96'" 97 "'WakeRsn97'" 98 "'WakeRsn98'" 99 "'WakeRsn99'" 100 "'WakeRsn100'" 101 "'WakeRsn101'" 102 "'WakeRsn102'" 103 "'WakeRsn103'" 104 "'WakeRsn104'" 105 "'WakeRsn105'" 106 "'WakeRsn106'" 107 "'WakeRsn107'" 108 "'WakeRsn108'" 109 "'WakeRsn109'" 110 "'WakeRsn110'" 111 "'WakeRsn111'" 112 "'WakeRsn112'" 113 "'WakeRsn113'" 114 "'WakeRsn114'" 115 "'WakeRsn115'" 116 "'WakeRsn116'" 117 "'WakeRsn117'" 118 "'WakeRsn118'" 119 "'WakeRsn119'" 120 "'WakeRsn120'" 121 "'WakeRsn121'" 122 "'WakeRsn122'" 123 "'WakeRsn123'" 124 "'WakeRsn124'" 125 "'WakeRsn125'" 126 "'WakeRsn126'" 127 "'WakeRsn127'" ;
VAL_ 2654208014 WakeReq_HVB 0 "'NotActive'" 1 "'Active'" ;
VAL_ 2654208026 WakeRsn_NAB 0 "'Diag'" 1 "'Network'" 2 "'High_DC_Voltage'" 3 "Crash_Output" 4 "'WakeRsn4'" 5 "'WakeRsn5'" 6 "'WakeRsn6'" 7 "'WakeRsn7'" 8 "'WakeRsn8'" 9 "'WakeRsn9'" 10 "'WakeRsn10'" 11 "'WakeRsn11'" 12 "'WakeRsn12'" 13 "'WakeRsn13'" 14 "'WakeRsn14'" 15 "'WakeRsn15'" 16 "'WakeRsn16'" 17 "'WakeRsn17'" 18 "'WakeRsn18'" 19 "'WakeRsn19'" 20 "'WakeRsn20'" 21 "'WakeRsn21'" 22 "'WakeRsn22'" 23 "'WakeRsn23'" 24 "'WakeRsn24'" 25 "'WakeRsn25'" 26 "'WakeRsn26'" 27 "'WakeRsn27'" 28 "'WakeRsn28'" 29 "'WakeRsn29'" 30 "'WakeRsn30'" 31 "'WakeRsn31'" 32 "'WakeRsn32'" 33 "'WakeRsn33'" 34 "'WakeRsn34'" 35 "'WakeRsn35'" 36 "'WakeRsn36'" 37 "'WakeRsn37'" 38 "'WakeRsn38'" 39 "'WakeRsn39'" 40 "'WakeRsn40'" 41 "'WakeRsn41'" 42 "'WakeRsn42'" 43 "'WakeRsn43'" 44 "'WakeRsn44'" 45 "'WakeRsn45'" 46 "'WakeRsn46'" 47 "'WakeRsn47'" 48 "'WakeRsn48'" 49 "'WakeRsn49'" 50 "'WakeRsn50'" 51 "'WakeRsn51'" 52 "'WakeRsn52'" 53 "'WakeRsn53'" 54 "'WakeRsn54'" 55 "'WakeRsn55'" 56 "'WakeRsn56'" 57 "'WakeRsn57'" 58 "'WakeRsn58'" 59 "'WakeRsn59'" 60 "'WakeRsn60'" 61 "'WakeRsn61'" 62 "'WakeRsn62'" 63 "'WakeRsn63'" 64 "'WakeRsn64'" 65 "'WakeRsn65'" 66 "'WakeRsn66'" 67 "'WakeRsn67'" 68 "'WakeRsn68'" 69 "'WakeRsn69'" 70 "'WakeRsn70'" 71 "'WakeRsn71'" 72 "'WakeRsn72'" 73 "'WakeRsn73'" 74 "'WakeRsn74'" 75 "'WakeRsn75'" 76 "'WakeRsn76'" 77 "'WakeRsn77'" 78 "'WakeRsn78'" 79 "'WakeRsn79'" 80 "'WakeRsn80'" 81 "'WakeRsn81'" 82 "'WakeRsn82'" 83 "'WakeRsn83'" 84 "'WakeRsn84'" 85 "'WakeRsn85'" 86 "'WakeRsn86'" 87 "'WakeRsn87'" 88 "'WakeRsn88'" 89 "'WakeRsn89'" 90 "'WakeRsn90'" 91 "'WakeRsn91'" 92 "'WakeRsn92'" 93 "'WakeRsn93'" 94 "'WakeRsn94'" 95 "'WakeRsn95'" 96 "'WakeRsn96'" 97 "'WakeRsn97'" 98 "'WakeRsn98'" 99 "'WakeRsn99'" 100 "'WakeRsn100'" 101 "'WakeRsn101'" 102 "'WakeRsn102'" 103 "'WakeRsn103'" 104 "'WakeRsn104'" 105 "'WakeRsn105'" 106 "'WakeRsn106'" 107 "'WakeRsn107'" 108 "'WakeRsn108'" 109 "'WakeRsn109'" 110 "'WakeRsn110'" 111 "'WakeRsn111'" 112 "'WakeRsn112'" 113 "'WakeRsn113'" 114 "'WakeRsn114'" 115 "'WakeRsn115'" 116 "'WakeRsn116'" 117 "'WakeRsn117'" 118 "'WakeRsn118'" 119 "'WakeRsn119'" 120 "'WakeRsn120'" 121 "'WakeRsn121'" 122 "'WakeRsn122'" 123 "'WakeRsn123'" 124 "'WakeRsn124'" 125 "'WakeRsn125'" 126 "'WakeRsn126'" 127 "'WakeRsn127'" ;
VAL_ 2654208026 WakeReq_NAB 0 "'NotActive'" 1 "'Active'" ;
VAL_ 2654208028 WakeRsn_NTP 0 "'Diag'" 1 "'Network'" 2 "'High_DC_Voltage'" 3 "'WakeRsn3'" 4 "'WakeRsn4'" 5 "'WakeRsn5'" 6 "'WakeRsn6'" 7 "'WakeRsn7'" 8 "'WakeRsn8'" 9 "'WakeRsn9'" 10 "'WakeRsn10'" 11 "'WakeRsn11'" 12 "'WakeRsn12'" 13 "'WakeRsn13'" 14 "'WakeRsn14'" 15 "'WakeRsn15'" 16 "'WakeRsn16'" 17 "'WakeRsn17'" 18 "'WakeRsn18'" 19 "'WakeRsn19'" 20 "'WakeRsn20'" 21 "'WakeRsn21'" 22 "'WakeRsn22'" 23 "'WakeRsn23'" 24 "'WakeRsn24'" 25 "'WakeRsn25'" 26 "'WakeRsn26'" 27 "'WakeRsn27'" 28 "'WakeRsn28'" 29 "'WakeRsn29'" 30 "'WakeRsn30'" 31 "'WakeRsn31'" 32 "'WakeRsn32'" 33 "'WakeRsn33'" 34 "'WakeRsn34'" 35 "'WakeRsn35'" 36 "'WakeRsn36'" 37 "'WakeRsn37'" 38 "'WakeRsn38'" 39 "'WakeRsn39'" 40 "'WakeRsn40'" 41 "'WakeRsn41'" 42 "'WakeRsn42'" 43 "'WakeRsn43'" 44 "'WakeRsn44'" 45 "'WakeRsn45'" 46 "'WakeRsn46'" 47 "'WakeRsn47'" 48 "'WakeRsn48'" 49 "'WakeRsn49'" 50 "'WakeRsn50'" 51 "'WakeRsn51'" 52 "'WakeRsn52'" 53 "'WakeRsn53'" 54 "'WakeRsn54'" 55 "'WakeRsn55'" 56 "'WakeRsn56'" 57 "'WakeRsn57'" 58 "'WakeRsn58'" 59 "'WakeRsn59'" 60 "'WakeRsn60'" 61 "'WakeRsn61'" 62 "'WakeRsn62'" 63 "'WakeRsn63'" 64 "'WakeRsn64'" 65 "'WakeRsn65'" 66 "'WakeRsn66'" 67 "'WakeRsn67'" 68 "'WakeRsn68'" 69 "'WakeRsn69'" 70 "'WakeRsn70'" 71 "'WakeRsn71'" 72 "'WakeRsn72'" 73 "'WakeRsn73'" 74 "'WakeRsn74'" 75 "'WakeRsn75'" 76 "'WakeRsn76'" 77 "'WakeRsn77'" 78 "'WakeRsn78'" 79 "'WakeRsn79'" 80 "'WakeRsn80'" 81 "'WakeRsn81'" 82 "'WakeRsn82'" 83 "'WakeRsn83'" 84 "'WakeRsn84'" 85 "'WakeRsn85'" 86 "'WakeRsn86'" 87 "'WakeRsn87'" 88 "'WakeRsn88'" 89 "'WakeRsn89'" 90 "'WakeRsn90'" 91 "'WakeRsn91'" 92 "'WakeRsn92'" 93 "'WakeRsn93'" 94 "'WakeRsn94'" 95 "'WakeRsn95'" 96 "'WakeRsn96'" 97 "'WakeRsn97'" 98 "'WakeRsn98'" 99 "'WakeRsn99'" 100 "'WakeRsn100'" 101 "'WakeRsn101'" 102 "'WakeRsn102'" 103 "'WakeRsn103'" 104 "'WakeRsn104'" 105 "'WakeRsn105'" 106 "'WakeRsn106'" 107 "'WakeRsn107'" 108 "'WakeRsn108'" 109 "'WakeRsn109'" 110 "'WakeRsn110'" 111 "'WakeRsn111'" 112 "'WakeRsn112'" 113 "'WakeRsn113'" 114 "'WakeRsn114'" 115 "'WakeRsn115'" 116 "'WakeRsn116'" 117 "'WakeRsn117'" 118 "'WakeRsn118'" 119 "'WakeRsn119'" 120 "'WakeRsn120'" 121 "'WakeRsn121'" 122 "'WakeRsn122'" 123 "'WakeRsn123'" 124 "'WakeRsn124'" 125 "'WakeRsn125'" 126 "'WakeRsn126'" 127 "'WakeRsn127'" ;
VAL_ 2654208028 WakeReq_NTP 0 "'NotActive'" 1 "'Active'" ;
VAL_ 2654208048 WakeRsn_PCU 0 "'Diag'" 1 "'Network'" 2 "'WakeRsn2'" 3 "'WakeRsn3'" 4 "'WakeRsn4'" 5 "'WakeRsn5'" 6 "'WakeRsn6'" 7 "'WakeRsn7'" 8 "'WakeRsn8'" 9 "'WakeRsn9'" 10 "'WakeRsn10'" 11 "'WakeRsn11'" 12 "'WakeRsn12'" 13 "'WakeRsn13'" 14 "'WakeRsn14'" 15 "'WakeRsn15'" 16 "'WakeRsn16'" 17 "'WakeRsn17'" 18 "'WakeRsn18'" 19 "'WakeRsn19'" 20 "'WakeRsn20'" 21 "'WakeRsn21'" 22 "'WakeRsn22'" 23 "'WakeRsn23'" 24 "'WakeRsn24'" 25 "'WakeRsn25'" 26 "'WakeRsn26'" 27 "'WakeRsn27'" 28 "'WakeRsn28'" 29 "'WakeRsn29'" 30 "'WakeRsn30'" 31 "'WakeRsn31'" 32 "'WakeRsn32'" 33 "'WakeRsn33'" 34 "'WakeRsn34'" 35 "'WakeRsn35'" 36 "'WakeRsn36'" 37 "'WakeRsn37'" 38 "'WakeRsn38'" 39 "'WakeRsn39'" 40 "'WakeRsn40'" 41 "'WakeRsn41'" 42 "'WakeRsn42'" 43 "'WakeRsn43'" 44 "'WakeRsn44'" 45 "'WakeRsn45'" 46 "'WakeRsn46'" 47 "'WakeRsn47'" 48 "'WakeRsn48'" 49 "'WakeRsn49'" 50 "'WakeRsn50'" 51 "'WakeRsn51'" 52 "'WakeRsn52'" 53 "'WakeRsn53'" 54 "'WakeRsn54'" 55 "'WakeRsn55'" 56 "'WakeRsn56'" 57 "'WakeRsn57'" 58 "'WakeRsn58'" 59 "'WakeRsn59'" 60 "'WakeRsn60'" 61 "'WakeRsn61'" 62 "'WakeRsn62'" 63 "'WakeRsn63'" 64 "'WakeRsn64'" 65 "'WakeRsn65'" 66 "'WakeRsn66'" 67 "'WakeRsn67'" 68 "'WakeRsn68'" 69 "'WakeRsn69'" 70 "'WakeRsn70'" 71 "'WakeRsn71'" 72 "'WakeRsn72'" 73 "'WakeRsn73'" 74 "'WakeRsn74'" 75 "'WakeRsn75'" 76 "'WakeRsn76'" 77 "'WakeRsn77'" 78 "'WakeRsn78'" 79 "'WakeRsn79'" 80 "'WakeRsn80'" 81 "'WakeRsn81'" 82 "'WakeRsn82'" 83 "'WakeRsn83'" 84 "'WakeRsn84'" 85 "'WakeRsn85'" 86 "'WakeRsn86'" 87 "'WakeRsn87'" 88 "'WakeRsn88'" 89 "'WakeRsn89'" 90 "'WakeRsn90'" 91 "'WakeRsn91'" 92 "'WakeRsn92'" 93 "'WakeRsn93'" 94 "'WakeRsn94'" 95 "'WakeRsn95'" 96 "'WakeRsn96'" 97 "'WakeRsn97'" 98 "'WakeRsn98'" 99 "'WakeRsn99'" 100 "'WakeRsn100'" 101 "'WakeRsn101'" 102 "'WakeRsn102'" 103 "'WakeRsn103'" 104 "'WakeRsn104'" 105 "'WakeRsn105'" 106 "'WakeRsn106'" 107 "'WakeRsn107'" 108 "'WakeRsn108'" 109 "'WakeRsn109'" 110 "'WakeRsn110'" 111 "'WakeRsn111'" 112 "'WakeRsn112'" 113 "'WakeRsn113'" 114 "'WakeRsn114'" 115 "'WakeRsn115'" 116 "'WakeRsn116'" 117 "'WakeRsn117'" 118 "'WakeRsn118'" 119 "'WakeRsn119'" 120 "'WakeRsn120'" 121 "'WakeRsn121'" 122 "'WakeRsn122'" 123 "'WakeRsn123'" 124 "'WakeRsn124'" 125 "'WakeRsn125'" 126 "'WakeRsn126'" 127 "'WakeRsn127'" ;
VAL_ 2654208048 WakeReq_PCU 0 "'NotActive'" 1 "'Active'" ;
VAL_ 2654208049 WakeRsn_OBC 0 "'Diag'" 1 "'Network'" 2 "Charge_Plug_Inserted" 3 "'WakeRsn3'" 4 "'WakeRsn4'" 5 "'WakeRsn5'" 6 "'WakeRsn6'" 7 "'WakeRsn7'" 8 "'WakeRsn8'" 9 "'WakeRsn9'" 10 "'WakeRsn10'" 11 "'WakeRsn11'" 12 "'WakeRsn12'" 13 "'WakeRsn13'" 14 "'WakeRsn14'" 15 "'WakeRsn15'" 16 "'WakeRsn16'" 17 "'WakeRsn17'" 18 "'WakeRsn18'" 19 "'WakeRsn19'" 20 "'WakeRsn20'" 21 "'WakeRsn21'" 22 "'WakeRsn22'" 23 "'WakeRsn23'" 24 "'WakeRsn24'" 25 "'WakeRsn25'" 26 "'WakeRsn26'" 27 "'WakeRsn27'" 28 "'WakeRsn28'" 29 "'WakeRsn29'" 30 "'WakeRsn30'" 31 "'WakeRsn31'" 32 "'WakeRsn32'" 33 "'WakeRsn33'" 34 "'WakeRsn34'" 35 "'WakeRsn35'" 36 "'WakeRsn36'" 37 "'WakeRsn37'" 38 "'WakeRsn38'" 39 "'WakeRsn39'" 40 "'WakeRsn40'" 41 "'WakeRsn41'" 42 "'WakeRsn42'" 43 "'WakeRsn43'" 44 "'WakeRsn44'" 45 "'WakeRsn45'" 46 "'WakeRsn46'" 47 "'WakeRsn47'" 48 "'WakeRsn48'" 49 "'WakeRsn49'" 50 "'WakeRsn50'" 51 "'WakeRsn51'" 52 "'WakeRsn52'" 53 "'WakeRsn53'" 54 "'WakeRsn54'" 55 "'WakeRsn55'" 56 "'WakeRsn56'" 57 "'WakeRsn57'" 58 "'WakeRsn58'" 59 "'WakeRsn59'" 60 "'WakeRsn60'" 61 "'WakeRsn61'" 62 "'WakeRsn62'" 63 "'WakeRsn63'" 64 "'WakeRsn64'" 65 "'WakeRsn65'" 66 "'WakeRsn66'" 67 "'WakeRsn67'" 68 "'WakeRsn68'" 69 "'WakeRsn69'" 70 "'WakeRsn70'" 71 "'WakeRsn71'" 72 "'WakeRsn72'" 73 "'WakeRsn73'" 74 "'WakeRsn74'" 75 "'WakeRsn75'" 76 "'WakeRsn76'" 77 "'WakeRsn77'" 78 "'WakeRsn78'" 79 "'WakeRsn79'" 80 "'WakeRsn80'" 81 "'WakeRsn81'" 82 "'WakeRsn82'" 83 "'WakeRsn83'" 84 "'WakeRsn84'" 85 "'WakeRsn85'" 86 "'WakeRsn86'" 87 "'WakeRsn87'" 88 "'WakeRsn88'" 89 "'WakeRsn89'" 90 "'WakeRsn90'" 91 "'WakeRsn91'" 92 "'WakeRsn92'" 93 "'WakeRsn93'" 94 "'WakeRsn94'" 95 "'WakeRsn95'" 96 "'WakeRsn96'" 97 "'WakeRsn97'" 98 "'WakeRsn98'" 99 "'WakeRsn99'" 100 "'WakeRsn100'" 101 "'WakeRsn101'" 102 "'WakeRsn102'" 103 "'WakeRsn103'" 104 "'WakeRsn104'" 105 "'WakeRsn105'" 106 "'WakeRsn106'" 107 "'WakeRsn107'" 108 "'WakeRsn108'" 109 "'WakeRsn109'" 110 "'WakeRsn110'" 111 "'WakeRsn111'" 112 "'WakeRsn112'" 113 "'WakeRsn113'" 114 "'WakeRsn114'" 115 "'WakeRsn115'" 116 "'WakeRsn116'" 117 "'WakeRsn117'" 118 "'WakeRsn118'" 119 "'WakeRsn119'" 120 "'WakeRsn120'" 121 "'WakeRsn121'" 122 "'WakeRsn122'" 123 "'WakeRsn123'" 124 "'WakeRsn124'" 125 "'WakeRsn125'" 126 "'WakeRsn126'" 127 "'WakeRsn127'" ;
VAL_ 2654208049 WakeReq_OBC 0 "'NotActive'" 1 "'Active'" ;
VAL_ 2654208050 WakeRsn_P2 0 "'Diag'" 1 "'Network'" 2 "'High_DC_Voltage'" 3 "'WakeRsn3'" 4 "'WakeRsn4'" 5 "'WakeRsn5'" 6 "'WakeRsn6'" 7 "'WakeRsn7'" 8 "'WakeRsn8'" 9 "'WakeRsn9'" 10 "'WakeRsn10'" 11 "'WakeRsn11'" 12 "'WakeRsn12'" 13 "'WakeRsn13'" 14 "'WakeRsn14'" 15 "'WakeRsn15'" 16 "'WakeRsn16'" 17 "'WakeRsn17'" 18 "'WakeRsn18'" 19 "'WakeRsn19'" 20 "'WakeRsn20'" 21 "'WakeRsn21'" 22 "'WakeRsn22'" 23 "'WakeRsn23'" 24 "'WakeRsn24'" 25 "'WakeRsn25'" 26 "'WakeRsn26'" 27 "'WakeRsn27'" 28 "'WakeRsn28'" 29 "'WakeRsn29'" 30 "'WakeRsn30'" 31 "'WakeRsn31'" 32 "'WakeRsn32'" 33 "'WakeRsn33'" 34 "'WakeRsn34'" 35 "'WakeRsn35'" 36 "'WakeRsn36'" 37 "'WakeRsn37'" 38 "'WakeRsn38'" 39 "'WakeRsn39'" 40 "'WakeRsn40'" 41 "'WakeRsn41'" 42 "'WakeRsn42'" 43 "'WakeRsn43'" 44 "'WakeRsn44'" 45 "'WakeRsn45'" 46 "'WakeRsn46'" 47 "'WakeRsn47'" 48 "'WakeRsn48'" 49 "'WakeRsn49'" 50 "'WakeRsn50'" 51 "'WakeRsn51'" 52 "'WakeRsn52'" 53 "'WakeRsn53'" 54 "'WakeRsn54'" 55 "'WakeRsn55'" 56 "'WakeRsn56'" 57 "'WakeRsn57'" 58 "'WakeRsn58'" 59 "'WakeRsn59'" 60 "'WakeRsn60'" 61 "'WakeRsn61'" 62 "'WakeRsn62'" 63 "'WakeRsn63'" 64 "'WakeRsn64'" 65 "'WakeRsn65'" 66 "'WakeRsn66'" 67 "'WakeRsn67'" 68 "'WakeRsn68'" 69 "'WakeRsn69'" 70 "'WakeRsn70'" 71 "'WakeRsn71'" 72 "'WakeRsn72'" 73 "'WakeRsn73'" 74 "'WakeRsn74'" 75 "'WakeRsn75'" 76 "'WakeRsn76'" 77 "'WakeRsn77'" 78 "'WakeRsn78'" 79 "'WakeRsn79'" 80 "'WakeRsn80'" 81 "'WakeRsn81'" 82 "'WakeRsn82'" 83 "'WakeRsn83'" 84 "'WakeRsn84'" 85 "'WakeRsn85'" 86 "'WakeRsn86'" 87 "'WakeRsn87'" 88 "'WakeRsn88'" 89 "'WakeRsn89'" 90 "'WakeRsn90'" 91 "'WakeRsn91'" 92 "'WakeRsn92'" 93 "'WakeRsn93'" 94 "'WakeRsn94'" 95 "'WakeRsn95'" 96 "'WakeRsn96'" 97 "'WakeRsn97'" 98 "'WakeRsn98'" 99 "'WakeRsn99'" 100 "'WakeRsn100'" 101 "'WakeRsn101'" 102 "'WakeRsn102'" 103 "'WakeRsn103'" 104 "'WakeRsn104'" 105 "'WakeRsn105'" 106 "'WakeRsn106'" 107 "'WakeRsn107'" 108 "'WakeRsn108'" 109 "'WakeRsn109'" 110 "'WakeRsn110'" 111 "'WakeRsn111'" 112 "'WakeRsn112'" 113 "'WakeRsn113'" 114 "'WakeRsn114'" 115 "'WakeRsn115'" 116 "'WakeRsn116'" 117 "'WakeRsn117'" 118 "'WakeRsn118'" 119 "'WakeRsn119'" 120 "'WakeRsn120'" 121 "'WakeRsn121'" 122 "'WakeRsn122'" 123 "'WakeRsn123'" 124 "'WakeRsn124'" 125 "'WakeRsn125'" 126 "'WakeRsn126'" 127 "'WakeRsn127'" ;
VAL_ 2654208050 WakeReq_P2 0 "'NotActive'" 1 "'Active'" ;
VAL_ 2654208089 WakeRsn_SGW 0 "'Diag'" 1 "'Network'" 2 "'WakeRsn2'" 3 "'WakeRsn3'" 4 "'WakeRsn4'" 5 "'WakeRsn5'" 6 "'WakeRsn6'" 7 "'WakeRsn7'" 8 "'WakeRsn8'" 9 "'WakeRsn9'" 10 "'WakeRsn10'" 11 "'WakeRsn11'" 12 "'WakeRsn12'" 13 "'WakeRsn13'" 14 "'WakeRsn14'" 15 "'WakeRsn15'" 16 "'WakeRsn16'" 17 "'WakeRsn17'" 18 "'WakeRsn18'" 19 "'WakeRsn19'" 20 "'WakeRsn20'" 21 "'WakeRsn21'" 22 "'WakeRsn22'" 23 "'WakeRsn23'" 24 "'WakeRsn24'" 25 "'WakeRsn25'" 26 "'WakeRsn26'" 27 "'WakeRsn27'" 28 "'WakeRsn28'" 29 "'WakeRsn29'" 30 "'WakeRsn30'" 31 "'WakeRsn31'" 32 "'WakeRsn32'" 33 "'WakeRsn33'" 34 "'WakeRsn34'" 35 "'WakeRsn35'" 36 "'WakeRsn36'" 37 "'WakeRsn37'" 38 "'WakeRsn38'" 39 "'WakeRsn39'" 40 "'WakeRsn40'" 41 "'WakeRsn41'" 42 "'WakeRsn42'" 43 "'WakeRsn43'" 44 "'WakeRsn44'" 45 "'WakeRsn45'" 46 "'WakeRsn46'" 47 "'WakeRsn47'" 48 "'WakeRsn48'" 49 "'WakeRsn49'" 50 "'WakeRsn50'" 51 "'WakeRsn51'" 52 "'WakeRsn52'" 53 "'WakeRsn53'" 54 "'WakeRsn54'" 55 "'WakeRsn55'" 56 "'WakeRsn56'" 57 "'WakeRsn57'" 58 "'WakeRsn58'" 59 "'WakeRsn59'" 60 "'WakeRsn60'" 61 "'WakeRsn61'" 62 "'WakeRsn62'" 63 "'WakeRsn63'" 64 "'WakeRsn64'" 65 "'WakeRsn65'" 66 "'WakeRsn66'" 67 "'WakeRsn67'" 68 "'WakeRsn68'" 69 "'WakeRsn69'" 70 "'WakeRsn70'" 71 "'WakeRsn71'" 72 "'WakeRsn72'" 73 "'WakeRsn73'" 74 "'WakeRsn74'" 75 "'WakeRsn75'" 76 "'WakeRsn76'" 77 "'WakeRsn77'" 78 "'WakeRsn78'" 79 "'WakeRsn79'" 80 "'WakeRsn80'" 81 "'WakeRsn81'" 82 "'WakeRsn82'" 83 "'WakeRsn83'" 84 "'WakeRsn84'" 85 "'WakeRsn85'" 86 "'WakeRsn86'" 87 "'WakeRsn87'" 88 "'WakeRsn88'" 89 "'WakeRsn89'" 90 "'WakeRsn90'" 91 "'WakeRsn91'" 92 "'WakeRsn92'" 93 "'WakeRsn93'" 94 "'WakeRsn94'" 95 "'WakeRsn95'" 96 "'WakeRsn96'" 97 "'WakeRsn97'" 98 "'WakeRsn98'" 99 "'WakeRsn99'" 100 "'WakeRsn100'" 101 "'WakeRsn101'" 102 "'WakeRsn102'" 103 "'WakeRsn103'" 104 "'WakeRsn104'" 105 "'WakeRsn105'" 106 "'WakeRsn106'" 107 "'WakeRsn107'" 108 "'WakeRsn108'" 109 "'WakeRsn109'" 110 "'WakeRsn110'" 111 "'WakeRsn111'" 112 "'WakeRsn112'" 113 "'WakeRsn113'" 114 "'WakeRsn114'" 115 "'WakeRsn115'" 116 "'WakeRsn116'" 117 "'WakeRsn117'" 118 "'WakeRsn118'" 119 "'WakeRsn119'" 120 "'WakeRsn120'" 121 "'WakeRsn121'" 122 "'WakeRsn122'" 123 "'WakeRsn123'" 124 "'WakeRsn124'" 125 "'WakeRsn125'" 126 "'WakeRsn126'" 127 "'WakeRsn127'" ;
VAL_ 2654208089 WakeReq_SGW 0 "'NotActive'" 1 "'Active'" ;
VAL_ 2654208090 WakeRsn_ADC 0 "'Diag'" 1 "'Network'" 2 "'WakeRsn2'" 3 "'WakeRsn3'" 4 "'WakeRsn4'" 5 "'WakeRsn5'" 6 "'WakeRsn6'" 7 "'WakeRsn7'" 8 "'WakeRsn8'" 9 "'WakeRsn9'" 10 "'WakeRsn10'" 11 "'WakeRsn11'" 12 "'WakeRsn12'" 13 "'WakeRsn13'" 14 "'WakeRsn14'" 15 "'WakeRsn15'" 16 "'WakeRsn16'" 17 "'WakeRsn17'" 18 "'WakeRsn18'" 19 "'WakeRsn19'" 20 "'WakeRsn20'" 21 "'WakeRsn21'" 22 "'WakeRsn22'" 23 "'WakeRsn23'" 24 "'WakeRsn24'" 25 "'WakeRsn25'" 26 "'WakeRsn26'" 27 "'WakeRsn27'" 28 "'WakeRsn28'" 29 "'WakeRsn29'" 30 "'WakeRsn30'" 31 "'WakeRsn31'" 32 "'WakeRsn32'" 33 "'WakeRsn33'" 34 "'WakeRsn34'" 35 "'WakeRsn35'" 36 "'WakeRsn36'" 37 "'WakeRsn37'" 38 "'WakeRsn38'" 39 "'WakeRsn39'" 40 "'WakeRsn40'" 41 "'WakeRsn41'" 42 "'WakeRsn42'" 43 "'WakeRsn43'" 44 "'WakeRsn44'" 45 "'WakeRsn45'" 46 "'WakeRsn46'" 47 "'WakeRsn47'" 48 "'WakeRsn48'" 49 "'WakeRsn49'" 50 "'WakeRsn50'" 51 "'WakeRsn51'" 52 "'WakeRsn52'" 53 "'WakeRsn53'" 54 "'WakeRsn54'" 55 "'WakeRsn55'" 56 "'WakeRsn56'" 57 "'WakeRsn57'" 58 "'WakeRsn58'" 59 "'WakeRsn59'" 60 "'WakeRsn60'" 61 "'WakeRsn61'" 62 "'WakeRsn62'" 63 "'WakeRsn63'" 64 "'WakeRsn64'" 65 "'WakeRsn65'" 66 "'WakeRsn66'" 67 "'WakeRsn67'" 68 "'WakeRsn68'" 69 "'WakeRsn69'" 70 "'WakeRsn70'" 71 "'WakeRsn71'" 72 "'WakeRsn72'" 73 "'WakeRsn73'" 74 "'WakeRsn74'" 75 "'WakeRsn75'" 76 "'WakeRsn76'" 77 "'WakeRsn77'" 78 "'WakeRsn78'" 79 "'WakeRsn79'" 80 "'WakeRsn80'" 81 "'WakeRsn81'" 82 "'WakeRsn82'" 83 "'WakeRsn83'" 84 "'WakeRsn84'" 85 "'WakeRsn85'" 86 "'WakeRsn86'" 87 "'WakeRsn87'" 88 "'WakeRsn88'" 89 "'WakeRsn89'" 90 "'WakeRsn90'" 91 "'WakeRsn91'" 92 "'WakeRsn92'" 93 "'WakeRsn93'" 94 "'WakeRsn94'" 95 "'WakeRsn95'" 96 "'WakeRsn96'" 97 "'WakeRsn97'" 98 "'WakeRsn98'" 99 "'WakeRsn99'" 100 "'WakeRsn100'" 101 "'WakeRsn101'" 102 "'WakeRsn102'" 103 "'WakeRsn103'" 104 "'WakeRsn104'" 105 "'WakeRsn105'" 106 "'WakeRsn106'" 107 "'WakeRsn107'" 108 "'WakeRsn108'" 109 "'WakeRsn109'" 110 "'WakeRsn110'" 111 "'WakeRsn111'" 112 "'WakeRsn112'" 113 "'WakeRsn113'" 114 "'WakeRsn114'" 115 "'WakeRsn115'" 116 "'WakeRsn116'" 117 "'WakeRsn117'" 118 "'WakeRsn118'" 119 "'WakeRsn119'" 120 "'WakeRsn120'" 121 "'WakeRsn121'" 122 "'WakeRsn122'" 123 "'WakeRsn123'" 124 "'WakeRsn124'" 125 "'WakeRsn125'" 126 "'WakeRsn126'" 127 "'WakeRsn127'" ;
VAL_ 2654208090 WakeReq_ADC 0 "'NotActive'" 1 "'Active'" ;
VAL_ 2654208112 WakeRsn_DMS 0 "'Diag'" 1 "'Network'" 2 "'WakeRsn2'" 3 "'WakeRsn3'" 4 "'WakeRsn4'" 5 "'WakeRsn5'" 6 "'WakeRsn6'" 7 "'WakeRsn7'" 8 "'WakeRsn8'" 9 "'WakeRsn9'" 10 "'WakeRsn10'" 11 "'WakeRsn11'" 12 "'WakeRsn12'" 13 "'WakeRsn13'" 14 "'WakeRsn14'" 15 "'WakeRsn15'" 16 "'WakeRsn16'" 17 "'WakeRsn17'" 18 "'WakeRsn18'" 19 "'WakeRsn19'" 20 "'WakeRsn20'" 21 "'WakeRsn21'" 22 "'WakeRsn22'" 23 "'WakeRsn23'" 24 "'WakeRsn24'" 25 "'WakeRsn25'" 26 "'WakeRsn26'" 27 "'WakeRsn27'" 28 "'WakeRsn28'" 29 "'WakeRsn29'" 30 "'WakeRsn30'" 31 "'WakeRsn31'" 32 "'WakeRsn32'" 33 "'WakeRsn33'" 34 "'WakeRsn34'" 35 "'WakeRsn35'" 36 "'WakeRsn36'" 37 "'WakeRsn37'" 38 "'WakeRsn38'" 39 "'WakeRsn39'" 40 "'WakeRsn40'" 41 "'WakeRsn41'" 42 "'WakeRsn42'" 43 "'WakeRsn43'" 44 "'WakeRsn44'" 45 "'WakeRsn45'" 46 "'WakeRsn46'" 47 "'WakeRsn47'" 48 "'WakeRsn48'" 49 "'WakeRsn49'" 50 "'WakeRsn50'" 51 "'WakeRsn51'" 52 "'WakeRsn52'" 53 "'WakeRsn53'" 54 "'WakeRsn54'" 55 "'WakeRsn55'" 56 "'WakeRsn56'" 57 "'WakeRsn57'" 58 "'WakeRsn58'" 59 "'WakeRsn59'" 60 "'WakeRsn60'" 61 "'WakeRsn61'" 62 "'WakeRsn62'" 63 "'WakeRsn63'" 64 "'WakeRsn64'" 65 "'WakeRsn65'" 66 "'WakeRsn66'" 67 "'WakeRsn67'" 68 "'WakeRsn68'" 69 "'WakeRsn69'" 70 "'WakeRsn70'" 71 "'WakeRsn71'" 72 "'WakeRsn72'" 73 "'WakeRsn73'" 74 "'WakeRsn74'" 75 "'WakeRsn75'" 76 "'WakeRsn76'" 77 "'WakeRsn77'" 78 "'WakeRsn78'" 79 "'WakeRsn79'" 80 "'WakeRsn80'" 81 "'WakeRsn81'" 82 "'WakeRsn82'" 83 "'WakeRsn83'" 84 "'WakeRsn84'" 85 "'WakeRsn85'" 86 "'WakeRsn86'" 87 "'WakeRsn87'" 88 "'WakeRsn88'" 89 "'WakeRsn89'" 90 "'WakeRsn90'" 91 "'WakeRsn91'" 92 "'WakeRsn92'" 93 "'WakeRsn93'" 94 "'WakeRsn94'" 95 "'WakeRsn95'" 96 "'WakeRsn96'" 97 "'WakeRsn97'" 98 "'WakeRsn98'" 99 "'WakeRsn99'" 100 "'WakeRsn100'" 101 "'WakeRsn101'" 102 "'WakeRsn102'" 103 "'WakeRsn103'" 104 "'WakeRsn104'" 105 "'WakeRsn105'" 106 "'WakeRsn106'" 107 "'WakeRsn107'" 108 "'WakeRsn108'" 109 "'WakeRsn109'" 110 "'WakeRsn110'" 111 "'WakeRsn111'" 112 "'WakeRsn112'" 113 "'WakeRsn113'" 114 "'WakeRsn114'" 115 "'WakeRsn115'" 116 "'WakeRsn116'" 117 "'WakeRsn117'" 118 "'WakeRsn118'" 119 "'WakeRsn119'" 120 "'WakeRsn120'" 121 "'WakeRsn121'" 122 "'WakeRsn122'" 123 "'WakeRsn123'" 124 "'WakeRsn124'" 125 "'WakeRsn125'" 126 "'WakeRsn126'" 127 "'WakeRsn127'" ;
VAL_ 2654208112 WakeReq_DMS 0 "NotActive" 1 "Active" ;
VAL_ 2654208125 WakeRsn_BES 0 "'Diag'" 1 "'Network'" 2 "'HVBGasDetected'" 3 "'WakeRsn3'" 4 "'WakeRsn4'" 5 "'WakeRsn5'" 6 "'WakeRsn6'" 7 "'WakeRsn7'" 8 "'WakeRsn8'" 9 "'WakeRsn9'" 10 "'WakeRsn10'" 11 "'WakeRsn11'" 12 "'WakeRsn12'" 13 "'WakeRsn13'" 14 "'WakeRsn14'" 15 "'WakeRsn15'" 16 "'WakeRsn16'" 17 "'WakeRsn17'" 18 "'WakeRsn18'" 19 "'WakeRsn19'" 20 "'WakeRsn20'" 21 "'WakeRsn21'" 22 "'WakeRsn22'" 23 "'WakeRsn23'" 24 "'WakeRsn24'" 25 "'WakeRsn25'" 26 "'WakeRsn26'" 27 "'WakeRsn27'" 28 "'WakeRsn28'" 29 "'WakeRsn29'" 30 "'WakeRsn30'" 31 "'WakeRsn31'" 32 "'WakeRsn32'" 33 "'WakeRsn33'" 34 "'WakeRsn34'" 35 "'WakeRsn35'" 36 "'WakeRsn36'" 37 "'WakeRsn37'" 38 "'WakeRsn38'" 39 "'WakeRsn39'" 40 "'WakeRsn40'" 41 "'WakeRsn41'" 42 "'WakeRsn42'" 43 "'WakeRsn43'" 44 "'WakeRsn44'" 45 "'WakeRsn45'" 46 "'WakeRsn46'" 47 "'WakeRsn47'" 48 "'WakeRsn48'" 49 "'WakeRsn49'" 50 "'WakeRsn50'" 51 "'WakeRsn51'" 52 "'WakeRsn52'" 53 "'WakeRsn53'" 54 "'WakeRsn54'" 55 "'WakeRsn55'" 56 "'WakeRsn56'" 57 "'WakeRsn57'" 58 "'WakeRsn58'" 59 "'WakeRsn59'" 60 "'WakeRsn60'" 61 "'WakeRsn61'" 62 "'WakeRsn62'" 63 "'WakeRsn63'" 64 "'WakeRsn64'" 65 "'WakeRsn65'" 66 "'WakeRsn66'" 67 "'WakeRsn67'" 68 "'WakeRsn68'" 69 "'WakeRsn69'" 70 "'WakeRsn70'" 71 "'WakeRsn71'" 72 "'WakeRsn72'" 73 "'WakeRsn73'" 74 "'WakeRsn74'" 75 "'WakeRsn75'" 76 "'WakeRsn76'" 77 "'WakeRsn77'" 78 "'WakeRsn78'" 79 "'WakeRsn79'" 80 "'WakeRsn80'" 81 "'WakeRsn81'" 82 "'WakeRsn82'" 83 "'WakeRsn83'" 84 "'WakeRsn84'" 85 "'WakeRsn85'" 86 "'WakeRsn86'" 87 "'WakeRsn87'" 88 "'WakeRsn88'" 89 "'WakeRsn89'" 90 "'WakeRsn90'" 91 "'WakeRsn91'" 92 "'WakeRsn92'" 93 "'WakeRsn93'" 94 "'WakeRsn94'" 95 "'WakeRsn95'" 96 "'WakeRsn96'" 97 "'WakeRsn97'" 98 "'WakeRsn98'" 99 "'WakeRsn99'" 100 "'WakeRsn100'" 101 "'WakeRsn101'" 102 "'WakeRsn102'" 103 "'WakeRsn103'" 104 "'WakeRsn104'" 105 "'WakeRsn105'" 106 "'WakeRsn106'" 107 "'WakeRsn107'" 108 "'WakeRsn108'" 109 "'WakeRsn109'" 110 "'WakeRsn110'" 111 "'WakeRsn111'" 112 "'WakeRsn112'" 113 "'WakeRsn113'" 114 "'WakeRsn114'" 115 "'WakeRsn115'" 116 "'WakeRsn116'" 117 "'WakeRsn117'" 118 "'WakeRsn118'" 119 "'WakeRsn119'" 120 "'WakeRsn120'" 121 "'WakeRsn121'" 122 "'WakeRsn122'" 123 "'WakeRsn123'" 124 "'WakeRsn124'" 125 "'WakeRsn125'" 126 "'WakeRsn126'" 127 "'WakeRsn127'" ;
VAL_ 2654208125 WakeReq_BES 0 "'NotActive'" 1 "'Active'" ;
VAL_ 2654339074 GenericFailSts_STATUS_C_NGE 0 "No_functional_fail_is_present" 1 "At_least_one_funct_fail_pres" ;
VAL_ 2654339074 CurrentFailSts 0 "No_functional_fail_is_present" 1 "DTCStatus_present" ;
VAL_ 2654339074 EOL_NGE 0 "No_EOL_prog_At_FIAT" 1 "EOL_prog_At_FIAT" ;
VAL_ 2654339074 DES_NGE 0 "Error_active_state" 1 "Error_Passive_warning_state" 2 "Bus_off_state" 3 "Not_used" ;
VAL_ 2654339074 ElectricSteeringFailSts 0 "Fail_not_Present" 1 "Fail_Present" ;
VAL_ 2654339074 NGE_Display_Info 0 "Normal" 1 "Derating" 2 "not_used" 3 "not_used" 4 "not_used" 5 "not_used" 6 "not_used" 7 "not_used" ;
VAL_ 2654339092 GenericFailSts_HVB 0 "No_functional_fail_is_present" 1 "At_least_one_funct_failure" ;
VAL_ 2654339092 CurrentFailSts_HVB 0 "No_functional_fail_is_present" 1 "DTCStatus_present" ;
VAL_ 2654339092 EOL_HVB 0 "No_EOL_prog_At_FIAT" 1 "EOL_prog_At_FIAT" ;
VAL_ 2654339092 DES_HVB 0 "Error_active_state" 1 "Error_Passive_warning_state" 2 "Bus_off_state" 3 "Not_used" ;
VAL_ 2654339092 HVB_Crash_Output 0 "Not_Active" 1 "Active" ;
VAL_ 2654339092 HVBActivityInProgress 0 "Not_Active" 1 "Active" ;
VAL_ 2654339098 GenericFailSts_STATUS_C_NAB_V2 0 "No_functional_fail_is_present" 1 "At_least_one_funct_fail_pres" ;
VAL_ 2654339098 CurrentFailSts 0 "No_functional_fail_is_present" 1 "DTCStatus_present" ;
VAL_ 2654339098 EOL_NAB 0 "No_EOL_prog_At_FIAT" 1 "EOL_prog_At_FIAT" ;
VAL_ 2654339098 DES_NAB 0 "Error_active_state" 1 "Error_Passive_warning_state" 2 "Bus_off_state" 3 "Not_used" ;
VAL_ 2654339100 GenericFailSts_NTP 0 "No_functional_fail_is_present" 1 "At_least_one_funct_failure" ;
VAL_ 2654339100 CurrentFailSts_NTP 0 "No_functional_fail_is_present" 1 "DTCStatus_present" ;
VAL_ 2654339100 EOL_NTP 0 "No_EOL_prog_At_FIAT" 1 "EOL_prog_At_FIAT" ;
VAL_ 2654339100 DES_NTP 0 "Error_active_state" 1 "Error_Passive_warning_state" 2 "Bus_off_state" 3 "Not_used" ;
VAL_ 2654339102 GenericFailSts_HALF 0 "No_functional_fail_is_present" 1 "At_least_one_funct_failure" ;
VAL_ 2654339102 CurrentFailSts_HALF 0 "No_functional_fail_is_present" 1 "DTCStatus_present" ;
VAL_ 2654339102 EOL_HALF 0 "No_EOL_prog_At_FIAT" 1 "EOL_prog_At_FIAT" ;
VAL_ 2654339102 DES_HALF 0 "Error_active_state" 1 "Error_Passive_warning_state" 2 "Bus_off_state" 3 "Not_used" ;
VAL_ 2654339120 GenericFailSts_PCU 0 "No_functional_fail_is_present" 1 "At_least_one_funct_failure" ;
VAL_ 2654339120 CurrentFailSts_PCU 0 "No_functional_fail_is_present" 1 "DTCStatus_present" ;
VAL_ 2654339120 EOL_PCU 0 "No_EOL_prog_At_FIAT" 1 "EOL_prog_At_FIAT" ;
VAL_ 2654339120 DES_PCU 0 "Error_active_state" 1 "Error_Passive_warning_state" 2 "Bus_off_state" 3 "Not_used" ;
VAL_ 2654339121 GenericFailSts_OBC 0 "No_functional_fail_is_present" 1 "At_least_one_funct_failure" ;
VAL_ 2654339121 CurrentFailSts_OBC 0 "No_functional_fail_is_present" 1 "DTCStatus_present" ;
VAL_ 2654339121 EOL_OBC 0 "No_EOL_prog_At_FIAT" 1 "EOL_prog_At_FIAT" ;
VAL_ 2654339121 DES_OBC 0 "Error_active_state" 1 "Error_Passive_warning_state" 2 "Bus_off_state" 3 "Not_used" ;
VAL_ 2654339122 GenericFailSts_P2 0 "No_functional_fail_is_present" 1 "At_least_one_funct_failure" ;
VAL_ 2654339122 CurrentFailSts_P2 0 "No_functional_fail_is_present" 1 "DTCStatus_present" ;
VAL_ 2654339122 EOL_P2 0 "No_EOL_prog_At_FIAT" 1 "EOL_prog_At_FIAT" ;
VAL_ 2654339122 DES_P2 0 "Error_active_state" 1 "Error_Passive_warning_state" 2 "Bus_off_state" 3 "Not_used" ;
VAL_ 2654339129 GenericFailSts_DASM 0 "No_functional_fail_is_present" 1 "At_least_one_funct_failure" ;
VAL_ 2654339129 CurrentFailSts_DASM 0 "No_functional_fail_is_present" 1 "DTCStatus_present" ;
VAL_ 2654339129 EOL_DASM 0 "No_EOL_prog_At_FIAT" 1 "EOL_prog_At_FIAT" ;
VAL_ 2654339129 DES_DASM 0 "Error_active_state" 1 "Error_Passive_warning_state" 2 "Bus_off_state" 3 "Not_used" ;
VAL_ 2654339149 GenericFailSts_MCA 0 "No_functional_fail_is_present" 1 "At_least_one_funct_fail_pres" ;
VAL_ 2654339149 CurrentFailSts_MCA 0 "No_functional_fail_is_present" 1 "DTCStatus_present" ;
VAL_ 2654339149 EOL_MCA 0 "No_EOL_prog_At_FIAT" 1 "EOL_prog_At_FIAT" ;
VAL_ 2654339149 DES_MCA 0 "Error_Active_State" 1 "Error_Passive_Warning_State" 2 "Bus_Off_State" 3 "Not_used" ;
VAL_ 2654339160 GenericFailSts_SDC 0 "No_functional_fail_is_present" 1 "At_least_one_funct_failure" ;
VAL_ 2654339160 CurrentFailSts_SDC 0 "No_functional_fail_is_present" 1 "DTCStatus_present" ;
VAL_ 2654339160 EOL_SDC 0 "No_EOL_prog_At_FIAT" 1 "EOL_prog_At_FIAT" ;
VAL_ 2654339160 DES_SDC 0 "Error_active_state" 1 "Error_Passive_warning_state" 2 "Bus_off_state" 3 "Not_used" ;
VAL_ 2654339161 GenericFailSts_SGW 0 "No_functional_fail_is_present" 1 "At_least_one_funct_fail_pres" ;
VAL_ 2654339161 CurrentFailSts_SGW 0 "No_functional_fail_is_present" 1 "DTCStatus_present" ;
VAL_ 2654339161 EOL_SGW 0 "No_EOL_prog_At_FIAT" 1 "EOL_prog_At_FIAT" ;
VAL_ 2654339161 DES_SGW 0 "Error_active_state" 1 "Error_Passive_warning_state" 2 "Bus_off_state" 3 "Not_used" ;
VAL_ 2654339184 GenericFailSts_DMS 0 "No_functional_fail_is_present" 1 "At_least_one_funct_failure" ;
VAL_ 2654339184 CurrentFailSts_DMS 0 "No_functional_fail_is_present" 1 "DTCStatus_present" ;
VAL_ 2654339184 EOL_DMS 0 "No_EOL_prog_At_FIAT" 1 "EOL_prog_At_FIAT" ;
VAL_ 2654339184 DES_DMS 0 "Error_active_state" 1 "Error_Passive_warning_state" 2 "Bus_off_state" 3 "Not_used" ;
VAL_ 2654339187 GenericFailSts_STATUS_C_LCUL_C1 0 "No_functional_fail_is_present" 1 "At_least_one_funct_fail_pres" ;
VAL_ 2654339187 CurrentFailSts_LCUL_C1 0 "No_functional_fail_is_present" 1 "DTCStatus_present" ;
VAL_ 2654339187 EOL_LCUL_C1 0 "No_EOL_prog_At_FIAT" 1 "EOL_prog_At_FIAT" ;
VAL_ 2654339187 D_ES_LCUL_C1 0 "Error_Active_State" 1 "Error_Passive_Warning_State" 2 "Bus_Off_State" 3 "Not_used" ;
VAL_ 2654339187 Left_LB_Feedback_LCUL_C1 0 "OFF" 1 "ON" ;
VAL_ 2654339187 Left_LB_FailSts 0 "Fail_Not_present" 1 "Fail_present" ;
VAL_ 2654339187 Left_HB_Feedback_LCUL_C1 0 "OFF" 1 "ON" ;
VAL_ 2654339187 Left_HB_FailSts 0 "Fail_Not_present" 1 "Fail_present" ;
VAL_ 2654339187 Left_PL_Feedback_LCUL_C1 0 "OFF" 1 "ON" ;
VAL_ 2654339187 Left_PL_FailSts 0 "Fail_Not_present" 1 "Fail_present" ;
VAL_ 2654339187 Left_DRL_Feedback_LCUL_C1 0 "OFF" 1 "ON" ;
VAL_ 2654339187 Left_DRL_FailSts 0 "Fail_Not_present" 1 "Fail_present" ;
VAL_ 2654339187 Left_TI_Feedback_LCUL_C1 0 "OFF" 1 "ON" ;
VAL_ 2654339187 Left_TI_FailSts_LCUL_C1 0 "Fail_Not_present" 1 "Fail_present" ;
VAL_ 2654339187 Left_LVL_FailSts 0 "Fail_Not_present" 1 "Fail_present" ;
VAL_ 2654339187 Left_FBLFaiLSts 0 "Fail_Not_Present" 1 "Fail_Present" ;
VAL_ 2654339187 ADB_FailSts_LH 0 "Fail_Not_present" 1 "Fail_present" ;
VAL_ 2654339187 Left_ParkingLight_Feedback_LCUL1 0 "Not_Enable" 1 "Enable" ;
VAL_ 2654339187 Left_TrafficChangeFbk 0 "Active_LeftSTD" 1 "Active_RightSTD" 2 "Active_LeftNoSTD" 3 "Active_RightNoSTD" ;
VAL_ 2654339187 Left_DodecaDriver_Failure 0 "Fail_Not_present" 1 "Fail_present" ;
VAL_ 2654339196 GenericFailSts_LCUR_C1 0 "No_functional_fail_is_present" 1 "At_least_one_funct_fail_pres" ;
VAL_ 2654339196 CurrentFailSts_LCUR_C1 0 "No_functional_fail_is_present" 1 "DTCStatus_present" ;
VAL_ 2654339196 EOL_LCUR_C1 0 "No_EOL_prog_At_FIAT" 1 "EOL_prog_At_FIAT" ;
VAL_ 2654339196 D_ES_LCUR_C1 0 "Error_Active_State" 1 "Error_Passive_Warning_State" 2 "Bus_Off_State" 3 "Not_used" ;
VAL_ 2654339196 Right_LB_Feedback_LCUR_C1 0 "OFF" 1 "ON" ;
VAL_ 2654339196 Right_LB_FailSts 0 "Fail_Not_present" 1 "Fail_present" ;
VAL_ 2654339196 Right_HB_Feedback_LCUR_C1 0 "OFF" 1 "ON" ;
VAL_ 2654339196 Right_HB_FailSts 0 "Fail_Not_present" 1 "Fail_present" ;
VAL_ 2654339196 Right_PL_Feedback_LCUR_C1 0 "OFF" 1 "ON" ;
VAL_ 2654339196 Right_PL_FailSts 0 "Fail_Not_present" 1 "Fail_present" ;
VAL_ 2654339196 Right_DRL_Feedback_LCUR_C1 0 "OFF" 1 "ON" ;
VAL_ 2654339196 Right_DRL_FailSts 0 "Fail_Not_present" 1 "Fail_present" ;
VAL_ 2654339196 Right_TI_Feedback_LCUR_C1 0 "OFF" 1 "ON" ;
VAL_ 2654339196 Right_TI_FailSts_LCUR_C1 0 "Fail_Not_present" 1 "Fail_present" ;
VAL_ 2654339196 Right_LVL_FailSts 0 "Fail_Not_present" 1 "Fail_present" ;
VAL_ 2654339196 Right_FBLFaiLSts 0 "Fail_Not_Present" 1 "Fail_Present" ;
VAL_ 2654339196 ADB_FailSts_RH 0 "Fail_Not_present" 1 "Fail_present" ;
VAL_ 2654339196 Right_ParkingLight_Feedback_LCUR 0 "Not_Enable" 1 "Enable" ;
VAL_ 2654339196 Right_TrafficChangeFbk 0 "Active_LeftSTD" 1 "Active_RightSTD" 2 "Active_LeftNoSTD" 3 "Active_RightNoSTD" ;
VAL_ 2654339196 Right_DodecaDriver_Failure 0 "Fail_Not_present" 1 "Fail_present" ;
VAL_ 2654339197 GenericFailSts_BES 0 "No_functional_fail_is_present" 1 "At_least_one_funct_fail_pres" ;
VAL_ 2654339197 CurrentFailSts_BES 0 "No_functional_fail_is_present" 1 "DTCStatus_present" ;
VAL_ 2654339197 EOL_BES 0 "No_EOL_prog_At_FIAT" 1 "EOL_prog_At_FIAT" ;
VAL_ 2654339197 D_ES_BES 0 "Error_active_state" 1 "Error_Passive_warning_state" 2 "Bus_off_state" 3 "Not_used" ;
